VERSION "dbc-export 1 2026.26.6.5"

NS_ :

BS_:

BU_: ADSP APB APP APS APSB BB BMS CC CMP CMPD CP DAS DI DIF DIR DPB EPAS3P EPAS3S EPASTP EPASTS EPBL EPBR ESP EVSE FC GTW HCML HCMR HVP IBST ICR IDB LS OCS1P PARK PCS PCS2 PM PMF PMR PNCD PTC RADC RCM RCM2 RCM3 RCU SCCM SCM SCS SDCR TAS TCU TCU2 TPMS TRCM UI UIS UMC USM V2G VC VCBATT VCBATT0 VCBATT1 VCBATT2 VCCC VCFRONT VCFRONT1 VCFRONT2 VCLEFT VCRIGHT VCSEAT2L VCSEAT2R VCSEC VEH

BO_ 1470 IDB_alertLog: 8 IDB
 SG_ IDB_alertID M : 0|8@1+ (1,0) [0|255] "" Vector__XXX
 SG_ IDB_alertState : 15|1@1+ (1,0) [0|1] "" Vector__XXX
 SG_ IDB_a014_wheelSpeedSensorFreq m14 : 16|1@1+ (1,0) [0|1] "" Vector__XXX
 SG_ IDB_a014_wheelSpeedSensorPhase m14 : 17|1@1+ (1,0) [0|1] "" Vector__XXX
 SG_ IDB_a014_wheelSpeedSensorMisinst m14 : 18|1@1+ (1,0) [0|1] "" Vector__XXX
 SG_ IDB_a014_wheelSpeedSensorWrongEx m14 : 19|1@1+ (1,0) [0|1] "" Vector__XXX
 SG_ IDB_a014_wheelSpeedSensorSpeedJu m14 : 20|1@1+ (1,0) [0|1] "" Vector__XXX
 SG_ IDB_a014_wheelSpeedSensorSp_0001 m14 : 21|1@1+ (1,0) [0|1] "" Vector__XXX
 SG_ IDB_a014_wheelSpeedSensorAirGap m14 : 22|1@1+ (1,0) [0|1] "" Vector__XXX
 SG_ IDB_a014_wheelSpeedSensorBIST m14 : 23|1@1+ (1,0) [0|1] "" Vector__XXX
 SG_ IDB_a014_wheelSpeedSensorLeakage m14 : 24|1@1+ (1,0) [0|1] "" Vector__XXX
 SG_ IDB_a014_wheelSpeedSensorOverTem m14 : 25|1@1+ (1,0) [0|1] "" Vector__XXX
 SG_ IDB_a014_wheelSpeedSensorSh_0001 m14 : 26|1@1+ (1,0) [0|1] "" Vector__XXX
 SG_ IDB_a014_wheelSpeedSensorShortTo m14 : 27|1@1+ (1,0) [0|1] "" Vector__XXX
 SG_ IDB_a014_wheelSpeedSensorOpen m14 : 28|1@1+ (1,0) [0|1] "" Vector__XXX
 SG_ IDB_a015_wheelSpeedSensorFreq m15 : 16|1@1+ (1,0) [0|1] "" Vector__XXX
 SG_ IDB_a015_wheelSpeedSensorPhase m15 : 17|1@1+ (1,0) [0|1] "" Vector__XXX
 SG_ IDB_a015_wheelSpeedSensorMisinst m15 : 18|1@1+ (1,0) [0|1] "" Vector__XXX
 SG_ IDB_a015_wheelSpeedSensorWrongEx m15 : 19|1@1+ (1,0) [0|1] "" Vector__XXX
 SG_ IDB_a015_wheelSpeedSensorSpeedJu m15 : 20|1@1+ (1,0) [0|1] "" Vector__XXX
 SG_ IDB_a015_wheelSpeedSensorSp_0001 m15 : 21|1@1+ (1,0) [0|1] "" Vector__XXX
 SG_ IDB_a015_wheelSpeedSensorAirGap m15 : 22|1@1+ (1,0) [0|1] "" Vector__XXX
 SG_ IDB_a015_wheelSpeedSensorBIST m15 : 23|1@1+ (1,0) [0|1] "" Vector__XXX
 SG_ IDB_a015_wheelSpeedSensorLeakage m15 : 24|1@1+ (1,0) [0|1] "" Vector__XXX
 SG_ IDB_a015_wheelSpeedSensorOverTem m15 : 25|1@1+ (1,0) [0|1] "" Vector__XXX
 SG_ IDB_a015_wheelSpeedSensorSh_0001 m15 : 26|1@1+ (1,0) [0|1] "" Vector__XXX
 SG_ IDB_a015_wheelSpeedSensorShortTo m15 : 27|1@1+ (1,0) [0|1] "" Vector__XXX
 SG_ IDB_a015_wheelSpeedSensorOpen m15 : 28|1@1+ (1,0) [0|1] "" Vector__XXX
 SG_ IDB_a016_wheelSpeedSensorFreq m16 : 16|1@1+ (1,0) [0|1] "" Vector__XXX
 SG_ IDB_a016_wheelSpeedSensorPhase m16 : 17|1@1+ (1,0) [0|1] "" Vector__XXX
 SG_ IDB_a016_wheelSpeedSensorMisinst m16 : 18|1@1+ (1,0) [0|1] "" Vector__XXX
 SG_ IDB_a016_wheelSpeedSensorWrongEx m16 : 19|1@1+ (1,0) [0|1] "" Vector__XXX
 SG_ IDB_a016_wheelSpeedSensorSpeedJu m16 : 20|1@1+ (1,0) [0|1] "" Vector__XXX
 SG_ IDB_a016_wheelSpeedSensorSp_0001 m16 : 21|1@1+ (1,0) [0|1] "" Vector__XXX
 SG_ IDB_a016_wheelSpeedSensorAirGap m16 : 22|1@1+ (1,0) [0|1] "" Vector__XXX
 SG_ IDB_a016_wheelSpeedSensorBIST m16 : 23|1@1+ (1,0) [0|1] "" Vector__XXX
 SG_ IDB_a016_wheelSpeedSensorLeakage m16 : 24|1@1+ (1,0) [0|1] "" Vector__XXX
 SG_ IDB_a016_wheelSpeedSensorOverTem m16 : 25|1@1+ (1,0) [0|1] "" Vector__XXX
 SG_ IDB_a016_wheelSpeedSensorSh_0001 m16 : 26|1@1+ (1,0) [0|1] "" Vector__XXX
 SG_ IDB_a016_wheelSpeedSensorShortTo m16 : 27|1@1+ (1,0) [0|1] "" Vector__XXX
 SG_ IDB_a016_wheelSpeedSensorOpen m16 : 28|1@1+ (1,0) [0|1] "" Vector__XXX
 SG_ IDB_a017_wheelSpeedSensorFreq m17 : 16|1@1+ (1,0) [0|1] "" Vector__XXX
 SG_ IDB_a017_wheelSpeedSensorPhase m17 : 17|1@1+ (1,0) [0|1] "" Vector__XXX
 SG_ IDB_a017_wheelSpeedSensorMisinst m17 : 18|1@1+ (1,0) [0|1] "" Vector__XXX
 SG_ IDB_a017_wheelSpeedSensorWrongEx m17 : 19|1@1+ (1,0) [0|1] "" Vector__XXX
 SG_ IDB_a017_wheelSpeedSensorSpeedJu m17 : 20|1@1+ (1,0) [0|1] "" Vector__XXX
 SG_ IDB_a017_wheelSpeedSensorSp_0001 m17 : 21|1@1+ (1,0) [0|1] "" Vector__XXX
 SG_ IDB_a017_wheelSpeedSensorAirGap m17 : 22|1@1+ (1,0) [0|1] "" Vector__XXX
 SG_ IDB_a017_wheelSpeedSensorBIST m17 : 23|1@1+ (1,0) [0|1] "" Vector__XXX
 SG_ IDB_a017_wheelSpeedSensorLeakage m17 : 24|1@1+ (1,0) [0|1] "" Vector__XXX
 SG_ IDB_a017_wheelSpeedSensorOverTem m17 : 25|1@1+ (1,0) [0|1] "" Vector__XXX
 SG_ IDB_a017_wheelSpeedSensorSh_0001 m17 : 26|1@1+ (1,0) [0|1] "" Vector__XXX
 SG_ IDB_a017_wheelSpeedSensorShortTo m17 : 27|1@1+ (1,0) [0|1] "" Vector__XXX
 SG_ IDB_a017_wheelSpeedSensorOpen m17 : 28|1@1+ (1,0) [0|1] "" Vector__XXX
 SG_ IDB_a020_canSignalValidity m20 : 16|1@1+ (1,0) [0|1] "" Vector__XXX
 SG_ IDB_a020_signalValueCrosscheck m20 : 17|1@1+ (1,0) [0|1] "" Vector__XXX
 SG_ IDB_a030_primaryExternalCircuitL m30 : 16|1@1+ (1,0) [0|1] "" Vector__XXX
 SG_ IDB_a030_secondaryExternalCircui m30 : 17|1@1+ (1,0) [0|1] "" Vector__XXX
 SG_ IDB_a030_primaryChamberInternalL m30 : 18|1@1+ (1,0) [0|1] "" Vector__XXX
 SG_ IDB_a030_syncModeInternalLeakage m30 : 19|1@1+ (1,0) [0|1] "" Vector__XXX
 SG_ IDB_a030_secondaryChamberInterna m30 : 20|1@1+ (1,0) [0|1] "" Vector__XXX
 SG_ IDB_a030_masterCylinderInternalL m30 : 21|1@1+ (1,0) [0|1] "" Vector__XXX
 SG_ IDB_a060_validityOnChassisBus m60 : 16|1@1+ (1,0) [0|1] "" Vector__XXX
 SG_ IDB_a060_validityOnPartyBus m60 : 17|1@1+ (1,0) [0|1] "" Vector__XXX
 SG_ IDB_a061_validityOnChassisBus m61 : 16|1@1+ (1,0) [0|1] "" Vector__XXX
 SG_ IDB_a061_validityOnPartyBus m61 : 17|1@1+ (1,0) [0|1] "" Vector__XXX
 SG_ IDB_a063_validityOnChassisBus m63 : 16|1@1+ (1,0) [0|1] "" Vector__XXX
 SG_ IDB_a063_validityOnPartyBus m63 : 17|1@1+ (1,0) [0|1] "" Vector__XXX
 SG_ IDB_a064_validityOnChassisBus m64 : 16|1@1+ (1,0) [0|1] "" Vector__XXX
 SG_ IDB_a064_validityOnPartyBus m64 : 17|1@1+ (1,0) [0|1] "" Vector__XXX
 SG_ IDB_a065_validityOnChassisBus m65 : 16|1@1+ (1,0) [0|1] "" Vector__XXX
 SG_ IDB_a065_validityOnPartyBus m65 : 17|1@1+ (1,0) [0|1] "" Vector__XXX
 SG_ IDB_a106_qualifierValidity m106 : 16|1@1+ (1,0) [0|1] "" Vector__XXX
 SG_ IDB_a106_signalNotAvailable m106 : 17|1@1+ (1,0) [0|1] "" Vector__XXX
 SG_ IDB_a107_qualifierValidity m107 : 16|1@1+ (1,0) [0|1] "" Vector__XXX
 SG_ IDB_a107_signalNotAvailable m107 : 17|1@1+ (1,0) [0|1] "" Vector__XXX
 SG_ IDB_a112_qualifierValidity m112 : 16|1@1+ (1,0) [0|1] "" Vector__XXX
 SG_ IDB_a112_signalNotAvailable m112 : 17|1@1+ (1,0) [0|1] "" Vector__XXX
 SG_ IDB_a113_qualifierValidity m113 : 16|1@1+ (1,0) [0|1] "" Vector__XXX
 SG_ IDB_a113_signalNotAvailable m113 : 17|1@1+ (1,0) [0|1] "" Vector__XXX
 SG_ IDB_a114_qualifierValidity m114 : 16|1@1+ (1,0) [0|1] "" Vector__XXX
 SG_ IDB_a114_signalNotAvailable m114 : 17|1@1+ (1,0) [0|1] "" Vector__XXX
 SG_ IDB_a126_PMebrCmdStateValidity m126 : 16|1@1+ (1,0) [0|1] "" Vector__XXX
 SG_ IDB_a126_PMstate2Validity m126 : 17|1@1+ (1,0) [0|1] "" Vector__XXX
 SG_ IDB_a126_PMstate2Missing m126 : 18|1@1+ (1,0) [0|1] "" Vector__XXX
 SG_ IDB_a126_DIchassisControlValidit m126 : 19|1@1+ (1,0) [0|1] "" Vector__XXX
 SG_ IDB_a126_DIchassisControlMissing m126 : 20|1@1+ (1,0) [0|1] "" Vector__XXX
 SG_ IDB_a126_DIrequestActiveValidity m126 : 21|1@1+ (1,0) [0|1] "" Vector__XXX
 SG_ IDB_a129_validityOnChassisBus m129 : 16|1@1+ (1,0) [0|1] "" Vector__XXX
 SG_ IDB_a129_validityOnPartyBus m129 : 17|1@1+ (1,0) [0|1] "" Vector__XXX
 SG_ IDB_a130_PMbrakePedalCmdQFValidi m130 : 16|1@1+ (1,0) [0|1] "" Vector__XXX
 SG_ IDB_a130_PMstate2Validity m130 : 17|1@1+ (1,0) [0|1] "" Vector__XXX
 SG_ IDB_a130_PMstate2Missing m130 : 18|1@1+ (1,0) [0|1] "" Vector__XXX
 SG_ IDB_a130_DIbrakeCommandValidity m130 : 19|1@1+ (1,0) [0|1] "" Vector__XXX
 SG_ IDB_a130_DIbrakeCommandMissing m130 : 20|1@1+ (1,0) [0|1] "" Vector__XXX
 SG_ IDB_a130_DIbrakeTorqueCommandFul m130 : 21|1@1+ (1,0) [0|1] "" Vector__XXX
 SG_ IDB_a130_DIbrakeTorqueComma_0001 m130 : 22|1@1+ (1,0) [0|1] "" Vector__XXX
 SG_ IDB_a132_validityOnChassisBus m132 : 16|1@1+ (1,0) [0|1] "" Vector__XXX
 SG_ IDB_a132_validityOnPartyBus m132 : 17|1@1+ (1,0) [0|1] "" Vector__XXX

BO_ 983 IDB_alertMatrix: 8 IDB
 SG_ IDB_matrixIndex M : 0|4@1+ (1,0) [0|15] "" Vector__XXX
 SG_ IDB_a001_mcuGenericFault m0 : 4|1@1+ (1,0) [0|1] "" Vector__XXX
 SG_ IDB_a002_supplyOvervoltage m0 : 5|1@1+ (1,0) [0|1] "" Vector__XXX
 SG_ IDB_a003_supplyHardOvervoltage m0 : 6|1@1+ (1,0) [0|1] "" Vector__XXX
 SG_ IDB_a004_supplyUndervoltage m0 : 7|1@1+ (1,0) [0|1] "" Vector__XXX
 SG_ IDB_a005_supplyMidUndervoltage m0 : 8|1@1+ (1,0) [0|1] "" Vector__XXX
 SG_ IDB_a006_supplyHardUndervoltage m0 : 9|1@1+ (1,0) [0|1] "" Vector__XXX
 SG_ IDB_a007_wakeLineOpen m0 : 10|1@1+ (1,0) [0|1] "" Vector__XXX
 SG_ IDB_a008_motorPowerOpen m0 : 11|1@1+ (1,0) [0|1] "" Vector__XXX
 SG_ IDB_a009_asicBoostFault m0 : 12|1@1+ (1,0) [0|1] "" Vector__XXX
 SG_ IDB_a010_asicGenericFault m0 : 13|1@1+ (1,0) [0|1] "" Vector__XXX
 SG_ IDB_a011_solenoidValveFault m0 : 14|1@1+ (1,0) [0|1] "" Vector__XXX
 SG_ IDB_a012_motorGenericFault m0 : 15|1@1+ (1,0) [0|1] "" Vector__XXX
 SG_ IDB_a013_motorPosSensorFault m0 : 16|1@1+ (1,0) [0|1] "" Vector__XXX
 SG_ IDB_a014_FrLWSSFault m0 : 17|1@1+ (1,0) [0|1] "" Vector__XXX
 SG_ IDB_a015_FrRWSSFault m0 : 18|1@1+ (1,0) [0|1] "" Vector__XXX
 SG_ IDB_a016_ReLWSSFault m0 : 19|1@1+ (1,0) [0|1] "" Vector__XXX
 SG_ IDB_a017_ReRWSSFault m0 : 20|1@1+ (1,0) [0|1] "" Vector__XXX
 SG_ IDB_a018_WSSGenericFault m0 : 21|1@1+ (1,0) [0|1] "" Vector__XXX
 SG_ IDB_a019_pedalSensorFault m0 : 22|1@1+ (1,0) [0|1] "" Vector__XXX
 SG_ IDB_a020_RCUpedalTravelMismatch m0 : 23|1@1+ (1,0) [0|1] "" Vector__XXX
 SG_ IDB_a021_pedalSensorNotCal m0 : 24|1@1+ (1,0) [0|1] "" Vector__XXX
 SG_ IDB_a022_brakeFluidLow m0 : 25|1@1+ (1,0) [0|1] "" Vector__XXX
 SG_ IDB_a023_steeringImplausible m0 : 26|1@1+ (1,0) [0|1] "" Vector__XXX
 SG_ IDB_a024_yawImplausible m0 : 27|1@1+ (1,0) [0|1] "" Vector__XXX
 SG_ IDB_a025_ayImplausible m0 : 28|1@1+ (1,0) [0|1] "" Vector__XXX
 SG_ IDB_a026_axImplausible m0 : 29|1@1+ (1,0) [0|1] "" Vector__XXX
 SG_ IDB_a027_circuitPresSensorFault m0 : 30|1@1+ (1,0) [0|1] "" Vector__XXX
 SG_ IDB_a028_simPresSensorFault m0 : 31|1@1+ (1,0) [0|1] "" Vector__XXX
 SG_ IDB_a029_pressureSensNotCal m0 : 32|1@1+ (1,0) [0|1] "" Vector__XXX
 SG_ IDB_a030_fluidLeakDetected m0 : 33|1@1+ (1,0) [0|1] "" Vector__XXX
 SG_ IDB_a031_solenoidValveStuck m0 : 34|1@1+ (1,0) [0|1] "" Vector__XXX
 SG_ IDB_a032_motorSoftOverheat m0 : 35|1@1+ (1,0) [0|1] "" Vector__XXX
 SG_ IDB_a033_motorHardOverheat m0 : 36|1@1+ (1,0) [0|1] "" Vector__XXX
 SG_ IDB_a034_motorPositionSetFault m0 : 37|1@1+ (1,0) [0|1] "" Vector__XXX
 SG_ IDB_a035_motorStuck m0 : 38|1@1+ (1,0) [0|1] "" Vector__XXX
 SG_ IDB_a036_partyBusOff m0 : 39|1@1+ (1,0) [0|1] "" Vector__XXX
 SG_ IDB_a037_chassisBusOff m0 : 40|1@1+ (1,0) [0|1] "" Vector__XXX
 SG_ IDB_a038_motorInitFault m0 : 41|1@1+ (1,0) [0|1] "" Vector__XXX
 SG_ IDB_a039_absActive m0 : 42|1@1+ (1,0) [0|1] "" Vector__XXX
 SG_ IDB_a040_ebdActive m0 : 43|1@1+ (1,0) [0|1] "" Vector__XXX
 SG_ IDB_a041_vdcActive m0 : 44|1@1+ (1,0) [0|1] "" Vector__XXX
 SG_ IDB_a042_btcActive m0 : 45|1@1+ (1,0) [0|1] "" Vector__XXX
 SG_ IDB_a043_cbcActive m0 : 46|1@1+ (1,0) [0|1] "" Vector__XXX
 SG_ IDB_a044_standstillSkidDetected m0 : 47|1@1+ (1,0) [0|1] "" Vector__XXX
 SG_ IDB_a045_panicBrakeAssistActive m0 : 48|1@1+ (1,0) [0|1] "" Vector__XXX
 SG_ IDB_a046_fadeCompensationActive m0 : 49|1@1+ (1,0) [0|1] "" Vector__XXX
 SG_ IDB_a047_brakeDiscWipeActive m0 : 50|1@1+ (1,0) [0|1] "" Vector__XXX
 SG_ IDB_a048_scmActive m0 : 51|1@1+ (1,0) [0|1] "" Vector__XXX
 SG_ IDB_a049_cdpActive m0 : 52|1@1+ (1,0) [0|1] "" Vector__XXX
 SG_ IDB_a050_absFaulted m0 : 53|1@1+ (1,0) [0|1] "" Vector__XXX
 SG_ IDB_a051_ebdFaulted m0 : 54|1@1+ (1,0) [0|1] "" Vector__XXX
 SG_ IDB_a052_vdcFaulted m0 : 55|1@1+ (1,0) [0|1] "" Vector__XXX
 SG_ IDB_a053_DItorquePathFaulted m0 : 56|1@1+ (1,0) [0|1] "" Vector__XXX
 SG_ IDB_a054_skidDetectionFaulted m0 : 57|1@1+ (1,0) [0|1] "" Vector__XXX
 SG_ IDB_a055_panicBrakeAssistFaulted m0 : 58|1@1+ (1,0) [0|1] "" Vector__XXX
 SG_ IDB_a056_fadeCompensationFaulted m0 : 59|1@1+ (1,0) [0|1] "" Vector__XXX
 SG_ IDB_a057_bdwRequestInvalid m0 : 60|1@1+ (1,0) [0|1] "" Vector__XXX
 SG_ IDB_a058_scmFaulted m0 : 61|1@1+ (1,0) [0|1] "" Vector__XXX
 SG_ IDB_a059_cdpFaulted m0 : 62|1@1+ (1,0) [0|1] "" Vector__XXX
 SG_ IDB_a060_RCUstatusDLC m0 : 63|1@1+ (1,0) [0|1] "" Vector__XXX
 SG_ IDB_a061_RCUstatusChecksum m1 : 4|1@1+ (1,0) [0|1] "" Vector__XXX
 SG_ IDB_a062_RCUstatusCounter m1 : 5|1@1+ (1,0) [0|1] "" Vector__XXX
 SG_ IDB_a063_RCUactuationDLC m1 : 6|1@1+ (1,0) [0|1] "" Vector__XXX
 SG_ IDB_a064_RCUactuationChecksum m1 : 7|1@1+ (1,0) [0|1] "" Vector__XXX
 SG_ IDB_a065_RCUactuationCounter m1 : 8|1@1+ (1,0) [0|1] "" Vector__XXX
 SG_ IDB_a066_DIFtorqueDLC m1 : 9|1@1+ (1,0) [0|1] "" Vector__XXX
 SG_ IDB_a067_DIFtorqueChecksum m1 : 10|1@1+ (1,0) [0|1] "" Vector__XXX
 SG_ IDB_a068_DIFtorqueCounter m1 : 11|1@1+ (1,0) [0|1] "" Vector__XXX
 SG_ IDB_a069_DIchassisControlDLC m1 : 12|1@1+ (1,0) [0|1] "" Vector__XXX
 SG_ IDB_a070_DIchassisControlChecksu m1 : 13|1@1+ (1,0) [0|1] "" Vector__XXX
 SG_ IDB_a071_DIchassisControlCounter m1 : 14|1@1+ (1,0) [0|1] "" Vector__XXX
 SG_ IDB_a072_DIsystemStatusDLC m1 : 15|1@1+ (1,0) [0|1] "" Vector__XXX
 SG_ IDB_a073_DIsystemStatusChecksum m1 : 16|1@1+ (1,0) [0|1] "" Vector__XXX
 SG_ IDB_a074_DIsystemStatusCounter m1 : 17|1@1+ (1,0) [0|1] "" Vector__XXX
 SG_ IDB_a075_DIRtorqueDLC m1 : 18|1@1+ (1,0) [0|1] "" Vector__XXX
 SG_ IDB_a076_DIRtorqueChecksum m1 : 19|1@1+ (1,0) [0|1] "" Vector__XXX
 SG_ IDB_a077_DIRtorqueCounter m1 : 20|1@1+ (1,0) [0|1] "" Vector__XXX
 SG_ IDB_a078_DIvdcLeftDLC m1 : 21|1@1+ (1,0) [0|1] "" Vector__XXX
 SG_ IDB_a079_DIvdcLeftChecksum m1 : 22|1@1+ (1,0) [0|1] "" Vector__XXX
 SG_ IDB_a080_DIvdcLeftCounter m1 : 23|1@1+ (1,0) [0|1] "" Vector__XXX
 SG_ IDB_a081_DIvdcRightDLC m1 : 24|1@1+ (1,0) [0|1] "" Vector__XXX
 SG_ IDB_a082_DIvdcRightChecksum m1 : 25|1@1+ (1,0) [0|1] "" Vector__XXX
 SG_ IDB_a083_DIvdcRightCounter m1 : 26|1@1+ (1,0) [0|1] "" Vector__XXX
 SG_ IDB_a084_EPAS3PsysStatusDLC m1 : 27|1@1+ (1,0) [0|1] "" Vector__XXX
 SG_ IDB_a085_EPAS3PsysStatusChecksum m1 : 28|1@1+ (1,0) [0|1] "" Vector__XXX
 SG_ IDB_a086_EPAS3PsysStatusCounter m1 : 29|1@1+ (1,0) [0|1] "" Vector__XXX
 SG_ IDB_a087_PMstate2DLC m1 : 30|1@1+ (1,0) [0|1] "" Vector__XXX
 SG_ IDB_a088_PMstate2Checksum m1 : 31|1@1+ (1,0) [0|1] "" Vector__XXX
 SG_ IDB_a089_PMstate2Counter m1 : 32|1@1+ (1,0) [0|1] "" Vector__XXX
 SG_ IDB_a090_RCMinertial1DLC m1 : 33|1@1+ (1,0) [0|1] "" Vector__XXX
 SG_ IDB_a091_RCMinertial1Checksum m1 : 34|1@1+ (1,0) [0|1] "" Vector__XXX
 SG_ IDB_a092_RCMinertial1Counter m1 : 35|1@1+ (1,0) [0|1] "" Vector__XXX
 SG_ IDB_a093_RCMinertial2DLC m1 : 36|1@1+ (1,0) [0|1] "" Vector__XXX
 SG_ IDB_a094_RCMinertial2Checksum m1 : 37|1@1+ (1,0) [0|1] "" Vector__XXX
 SG_ IDB_a095_RCMinertial2Counter m1 : 38|1@1+ (1,0) [0|1] "" Vector__XXX
 SG_ IDB_a096_VCFRONTLVPowerStateDLC m1 : 39|1@1+ (1,0) [0|1] "" Vector__XXX
 SG_ IDB_a097_VCFRONTLVPwrStChecksum m1 : 40|1@1+ (1,0) [0|1] "" Vector__XXX
 SG_ IDB_a098_VCFRONTLVPwrStCounter m1 : 41|1@1+ (1,0) [0|1] "" Vector__XXX
 SG_ IDB_a099_RCMcollisionDLC m1 : 42|1@1+ (1,0) [0|1] "" Vector__XXX
 SG_ IDB_a100_RCMcollisionChecksum m1 : 43|1@1+ (1,0) [0|1] "" Vector__XXX
 SG_ IDB_a101_RCMcollisionCounter m1 : 44|1@1+ (1,0) [0|1] "" Vector__XXX
 SG_ IDB_a102_bdwRequestActiveInvalid m1 : 45|1@1+ (1,0) [0|1] "" Vector__XXX
 SG_ IDB_a103_DIfullTorquePathFaulted m1 : 46|1@1+ (1,0) [0|1] "" Vector__XXX
 SG_ IDB_a104_DIaccelPosInvalid m1 : 47|1@1+ (1,0) [0|1] "" Vector__XXX
 SG_ IDB_a105_DIgearInvalid m1 : 48|1@1+ (1,0) [0|1] "" Vector__XXX
 SG_ IDB_a106_DIFtorqueInvalid m1 : 49|1@1+ (1,0) [0|1] "" Vector__XXX
 SG_ IDB_a107_DIRtorqueInvalid m1 : 50|1@1+ (1,0) [0|1] "" Vector__XXX
 SG_ IDB_a108_EPBstatusDLC m1 : 51|1@1+ (1,0) [0|1] "" Vector__XXX
 SG_ IDB_a109_BDWsignalInvalid m1 : 52|1@1+ (1,0) [0|1] "" Vector__XXX
 SG_ IDB_a110_EPBstatusCounter m1 : 53|1@1+ (1,0) [0|1] "" Vector__XXX
 SG_ IDB_a111_EPBstatusChecksum m1 : 54|1@1+ (1,0) [0|1] "" Vector__XXX
 SG_ IDB_a112_yawRateInvalid m1 : 55|1@1+ (1,0) [0|1] "" Vector__XXX
 SG_ IDB_a113_latAccelInvalid m1 : 56|1@1+ (1,0) [0|1] "" Vector__XXX
 SG_ IDB_a114_longAccelInvalid m1 : 57|1@1+ (1,0) [0|1] "" Vector__XXX
 SG_ IDB_a115_VCFRONTespLvStInvalid m1 : 58|1@1+ (1,0) [0|1] "" Vector__XXX
 SG_ IDB_a116_VCFRONTsensorsDLC m1 : 59|1@1+ (1,0) [0|1] "" Vector__XXX
 SG_ IDB_a117_VCLEFTepbmStatusDLC m1 : 60|1@1+ (1,0) [0|1] "" Vector__XXX
 SG_ IDB_a118_VCLEFTepbmStatusCounter m1 : 61|1@1+ (1,0) [0|1] "" Vector__XXX
 SG_ IDB_a119_VCLEFTepbmStatusChecksu m1 : 62|1@1+ (1,0) [0|1] "" Vector__XXX
 SG_ IDB_a120_EPAS3Pinvalid m1 : 63|1@1+ (1,0) [0|1] "" Vector__XXX
 SG_ IDB_a121_dynoModeActive m2 : 4|1@1+ (1,0) [0|1] "" Vector__XXX
 SG_ IDB_a122_DIFtorqueCommandInvalid m2 : 5|1@1+ (1,0) [0|1] "" Vector__XXX
 SG_ IDB_a123_DIRtorqueCommandInvalid m2 : 6|1@1+ (1,0) [0|1] "" Vector__XXX
 SG_ IDB_a124_VCFRONTtempInvalid m2 : 7|1@1+ (1,0) [0|1] "" Vector__XXX
 SG_ IDB_a125_PMvdcCmdStateInvalid m2 : 8|1@1+ (1,0) [0|1] "" Vector__XXX
 SG_ IDB_a126_DItorqueRequestInvalid m2 : 9|1@1+ (1,0) [0|1] "" Vector__XXX
 SG_ IDB_a127_brakeFluidLevelInvalid m2 : 10|1@1+ (1,0) [0|1] "" Vector__XXX
 SG_ IDB_a128_largeAirVolume m2 : 11|1@1+ (1,0) [0|1] "" Vector__XXX
 SG_ IDB_a129_RCUinputRodStrokeInvali m2 : 12|1@1+ (1,0) [0|1] "" Vector__XXX
 SG_ IDB_a130_DIfullTorqueRequestInva m2 : 13|1@1+ (1,0) [0|1] "" Vector__XXX
 SG_ IDB_a131_cbcFaulted m2 : 14|1@1+ (1,0) [0|1] "" Vector__XXX
 SG_ IDB_a132_RCUinputRodStrokeQFInva m2 : 15|1@1+ (1,0) [0|1] "" Vector__XXX
 SG_ IDB_a133_DIbrakeCommandDLC m2 : 16|1@1+ (1,0) [0|1] "" Vector__XXX
 SG_ IDB_a134_DIbrakeCommandCounter m2 : 17|1@1+ (1,0) [0|1] "" Vector__XXX
 SG_ IDB_a135_DIbrakeCommandChecksum m2 : 18|1@1+ (1,0) [0|1] "" Vector__XXX
 SG_ IDB_a136_RCUptsCalMissing m2 : 19|1@1+ (1,0) [0|1] "" Vector__XXX
 SG_ IDB_a137_VCLEFTcdpRequestInvalid m2 : 20|1@1+ (1,0) [0|1] "" Vector__XXX
 SG_ IDB_a138_DIbrakeTorqueCommandAnd m2 : 21|1@1+ (1,0) [0|1] "" Vector__XXX
 SG_ IDB_a139_DIbrakeTorqueCommandFul m2 : 22|1@1+ (1,0) [0|1] "" Vector__XXX
 SG_ IDB_a140_PMbrakePedalCmdQFInvali m2 : 23|1@1+ (1,0) [0|1] "" Vector__XXX
 SG_ IDB_a141_DIbrakeTorqueCommandFul m2 : 24|1@1+ (1,0) [0|1] "" Vector__XXX
 SG_ IDB_a142_PMebrCmdStateInvalid m2 : 25|1@1+ (1,0) [0|1] "" Vector__XXX
 SG_ IDB_a143_factoryModeActive m2 : 26|1@1+ (1,0) [0|1] "" Vector__XXX
 SG_ IDB_a144_hydraulicPushthroughAct m2 : 27|1@1+ (1,0) [0|1] "" Vector__XXX
 SG_ IDB_a145_DASredundantBrakingCont m2 : 28|1@1+ (1,0) [0|1] "" Vector__XXX
 SG_ IDB_a146_DASredundantBrakingCont m2 : 29|1@1+ (1,0) [0|1] "" Vector__XXX
 SG_ IDB_a147_DASredundantBrakingCont m2 : 30|1@1+ (1,0) [0|1] "" Vector__XXX
 SG_ IDB_a148_DASbrakeTorqueCommandIn m2 : 31|1@1+ (1,0) [0|1] "" Vector__XXX
 SG_ IDB_a149_DASmiaBrakeTorqueComman m2 : 32|1@1+ (1,0) [0|1] "" Vector__XXX
 SG_ IDB_a150_DIlocStatus2DLC m2 : 33|1@1+ (1,0) [0|1] "" Vector__XXX
 SG_ IDB_a151_DIlocStatus2Counter m2 : 34|1@1+ (1,0) [0|1] "" Vector__XXX
 SG_ IDB_a152_DIlocStatus2Checksum m2 : 35|1@1+ (1,0) [0|1] "" Vector__XXX
 SG_ IDB_a155_PMlocStateDLC m2 : 38|1@1+ (1,0) [0|1] "" Vector__XXX
 SG_ IDB_a156_PMlocStateChecksum m2 : 39|1@1+ (1,0) [0|1] "" Vector__XXX
 SG_ IDB_a157_PMlocStateCounter m2 : 40|1@1+ (1,0) [0|1] "" Vector__XXX

BO_ 828 IDB_info: 8 IDB
 SG_ IDB_infoIndex M : 0|8@1+ (1,0) [0|255] "" Vector__XXX
 SG_ IDB_infoPcbaID m11 : 16|8@1+ (1,0) [0|255] "" Vector__XXX
 SG_ IDB_infoAssemblyID m11 : 24|8@1+ (1,0) [0|255] "" Vector__XXX
 SG_ IDB_infoUsageID m11 : 32|16@1+ (1,0) [0|65535] "" Vector__XXX
 SG_ IDB_infoSubUsageID m11 : 48|16@1+ (1,0) [0|65535] "" Vector__XXX

BO_ 1012 LS_lightShow: 8 LS
 SG_ LS_lightShowIndex M : 0|5@1+ (1,0) [0|31] "" Vector__XXX
 SG_ LS_lightLeftRampedChannel1Reques m0 : 5|1@1+ (1,0) [0|1] "" Vector__XXX
 SG_ LS_lightLeftRampedChannel1Durati m0 : 6|2@1+ (1,0) [0|3] "" Vector__XXX
 SG_ LS_lightLeftRampedChannel2Reques m0 : 8|1@1+ (1,0) [0|1] "" Vector__XXX
 SG_ LS_lightLeftRampedChannel2Durati m0 : 9|2@1+ (1,0) [0|3] "" Vector__XXX
 SG_ LS_lightLeftRampedChannel3Reques m0 : 11|1@1+ (1,0) [0|1] "" Vector__XXX
 SG_ LS_lightLeftRampedChannel3Durati m0 : 12|2@1+ (1,0) [0|3] "" Vector__XXX
 SG_ LS_lightLeftRampedChannel4Reques m0 : 14|1@1+ (1,0) [0|1] "" Vector__XXX
 SG_ LS_lightLeftRampedChannel4Durati m0 : 16|2@1+ (1,0) [0|3] "" Vector__XXX
 SG_ LS_lightLeftRampedChannel5Reques m0 : 18|1@1+ (1,0) [0|1] "" Vector__XXX
 SG_ LS_lightLeftRampedChannel5Durati m0 : 19|2@1+ (1,0) [0|3] "" Vector__XXX
 SG_ LS_lightLeftRampedChannel6Reques m0 : 21|1@1+ (1,0) [0|1] "" Vector__XXX
 SG_ LS_lightLeftRampedChannel6Durati m0 : 22|2@1+ (1,0) [0|3] "" Vector__XXX
 SG_ LS_lightLeftRampedChannel7Reques m0 : 24|1@1+ (1,0) [0|1] "" Vector__XXX
 SG_ LS_lightLeftRampedChannel7Durati m0 : 25|2@1+ (1,0) [0|3] "" Vector__XXX
 SG_ LS_lightRightRampedChannel1Reque m0 : 27|1@1+ (1,0) [0|1] "" Vector__XXX
 SG_ LS_lightRightRampedChannel1Durat m0 : 28|2@1+ (1,0) [0|3] "" Vector__XXX
 SG_ LS_lightRightRampedChannel2Reque m0 : 30|1@1+ (1,0) [0|1] "" Vector__XXX
 SG_ LS_lightRightRampedChannel2Durat m0 : 31|2@1+ (1,0) [0|3] "" Vector__XXX
 SG_ LS_lightRightRampedChannel3Reque m0 : 33|1@1+ (1,0) [0|1] "" Vector__XXX
 SG_ LS_lightRightRampedChannel3Durat m0 : 34|2@1+ (1,0) [0|3] "" Vector__XXX
 SG_ LS_lightRightRampedChannel4Reque m0 : 36|1@1+ (1,0) [0|1] "" Vector__XXX
 SG_ LS_lightRightRampedChannel4Durat m0 : 37|2@1+ (1,0) [0|3] "" Vector__XXX
 SG_ LS_lightRightRampedChannel5Reque m0 : 39|1@1+ (1,0) [0|1] "" Vector__XXX
 SG_ LS_lightRightRampedChannel5Durat m0 : 40|2@1+ (1,0) [0|3] "" Vector__XXX
 SG_ LS_lightRightRampedChannel6Reque m0 : 42|1@1+ (1,0) [0|1] "" Vector__XXX
 SG_ LS_lightRightRampedChannel6Durat m0 : 43|2@1+ (1,0) [0|3] "" Vector__XXX
 SG_ LS_lightRightRampedChannel7Reque m0 : 45|1@1+ (1,0) [0|1] "" Vector__XXX
 SG_ LS_lightRightRampedChannel7Durat m0 : 46|2@1+ (1,0) [0|3] "" Vector__XXX
 SG_ LS_lightRearTurnLeftRequest m0 : 48|1@1+ (1,0) [0|1] "" Vector__XXX
 SG_ LS_lightRearTurnRightRequest m0 : 49|1@1+ (1,0) [0|1] "" Vector__XXX
 SG_ LS_lightSideRepeaterLeftRequest m0 : 50|1@1+ (1,0) [0|1] "" Vector__XXX
 SG_ LS_lightSideRepeaterRightRequest m0 : 51|1@1+ (1,0) [0|1] "" Vector__XXX
 SG_ LS_lightSideMarkerLeftRequest m0 : 52|1@1+ (1,0) [0|1] "" Vector__XXX
 SG_ LS_lightSideMarkerRightRequest m0 : 53|1@1+ (1,0) [0|1] "" Vector__XXX
 SG_ LS_lightFrontFogLeftRequest m0 : 54|1@1+ (1,0) [0|1] "" Vector__XXX
 SG_ LS_lightFrontFogRightRequest m0 : 55|1@1+ (1,0) [0|1] "" Vector__XXX
 SG_ LS_lightRearFogRequest m0 : 56|1@1+ (1,0) [0|1] "" Vector__XXX
 SG_ LS_lightBrakeRequest m0 : 57|1@1+ (1,0) [0|1] "" Vector__XXX
 SG_ LS_lightTailLeftRequest m0 : 58|1@1+ (1,0) [0|1] "" Vector__XXX
 SG_ LS_lightTailRightRequest m0 : 59|1@1+ (1,0) [0|1] "" Vector__XXX
 SG_ LS_lightLicensePlateRequest m0 : 60|1@1+ (1,0) [0|1] "" Vector__XXX
 SG_ LS_lightReverseRequest m0 : 61|1@1+ (1,0) [0|1] "" Vector__XXX
 SG_ LS_lightAuxParkLeftRequest m0 : 62|1@1+ (1,0) [0|1] "" Vector__XXX
 SG_ LS_lightAuxParkRightRequest m0 : 63|1@1+ (1,0) [0|1] "" Vector__XXX
 SG_ LS_mirrorRequestLeft m1 : 5|3@1+ (1,0) [0|7] "" Vector__XXX
 SG_ LS_mirrorRequestRight m1 : 8|3@1+ (1,0) [0|7] "" Vector__XXX
 SG_ LS_liftgateRequest m1 : 11|3@1+ (1,0) [0|7] "" Vector__XXX
 SG_ LS_windowRequestLF m1 : 16|3@1+ (1,0) [0|7] "" Vector__XXX
 SG_ LS_windowRequestLR m1 : 19|3@1+ (1,0) [0|7] "" Vector__XXX
 SG_ LS_windowRequestRF m1 : 24|3@1+ (1,0) [0|7] "" Vector__XXX
 SG_ LS_windowRequestRR m1 : 27|3@1+ (1,0) [0|7] "" Vector__XXX
 SG_ LS_presentingHandleRequestLF m1 : 32|3@1+ (1,0) [0|7] "" Vector__XXX
 SG_ LS_presentingHandleRequestLR m1 : 35|3@1+ (1,0) [0|7] "" Vector__XXX
 SG_ LS_presentingHandleRequestRF m1 : 40|3@1+ (1,0) [0|7] "" Vector__XXX
 SG_ LS_presentingHandleRequestRR m1 : 43|3@1+ (1,0) [0|7] "" Vector__XXX
 SG_ LS_powerFrontDoorRequestLeft m1 : 46|3@1+ (1,0) [0|7] "" Vector__XXX
 SG_ LS_powerFrontDoorRequestRight m1 : 49|3@1+ (1,0) [0|7] "" Vector__XXX
 SG_ LS_falconDoorRequestLeft m1 : 52|3@1+ (1,0) [0|7] "" Vector__XXX
 SG_ LS_falconDoorRequestRight m1 : 55|3@1+ (1,0) [0|7] "" Vector__XXX
 SG_ LS_chargePortRequest m1 : 58|2@1+ (1,0) [0|2] "" Vector__XXX
 SG_ LS_chargePortRaveRequest m1 : 60|1@1+ (1,0) [0|1] "" Vector__XXX
 SG_ LS_suspensionRequest m1 : 61|2@1+ (1,0) [0|2] "" Vector__XXX
 SG_ LS_rgbIPFLRed m2 : 8|8@1+ (1,0) [0|255] "" Vector__XXX
 SG_ LS_rgbIPFLGreen m2 : 16|8@1+ (1,0) [0|255] "" Vector__XXX
 SG_ LS_rgbIPFLBlue m2 : 24|8@1+ (1,0) [0|255] "" Vector__XXX
 SG_ LS_rgbIPFRRed m2 : 32|8@1+ (1,0) [0|255] "" Vector__XXX
 SG_ LS_rgbIPFRGreen m2 : 40|8@1+ (1,0) [0|255] "" Vector__XXX
 SG_ LS_rgbIPFRBlue m2 : 48|8@1+ (1,0) [0|255] "" Vector__XXX
 SG_ LS_rgbDoorFLForeRed m3 : 8|8@1+ (1,0) [0|255] "" Vector__XXX
 SG_ LS_rgbDoorFLForeGreen m3 : 16|8@1+ (1,0) [0|255] "" Vector__XXX
 SG_ LS_rgbDoorFLForeBlue m3 : 24|8@1+ (1,0) [0|255] "" Vector__XXX
 SG_ LS_rgbDoorFLAftRed m3 : 32|8@1+ (1,0) [0|255] "" Vector__XXX
 SG_ LS_rgbDoorFLAftGreen m3 : 40|8@1+ (1,0) [0|255] "" Vector__XXX
 SG_ LS_rgbDoorFLAftBlue m3 : 48|8@1+ (1,0) [0|255] "" Vector__XXX
 SG_ LS_rgbDoorFRForeRed m4 : 8|8@1+ (1,0) [0|255] "" Vector__XXX
 SG_ LS_rgbDoorFRForeGreen m4 : 16|8@1+ (1,0) [0|255] "" Vector__XXX
 SG_ LS_rgbDoorFRForeBlue m4 : 24|8@1+ (1,0) [0|255] "" Vector__XXX
 SG_ LS_rgbDoorFRAftRed m4 : 32|8@1+ (1,0) [0|255] "" Vector__XXX
 SG_ LS_rgbDoorFRAftGreen m4 : 40|8@1+ (1,0) [0|255] "" Vector__XXX
 SG_ LS_rgbDoorFRAftBlue m4 : 48|8@1+ (1,0) [0|255] "" Vector__XXX
 SG_ LS_rgbDoorRLForeRed m5 : 8|8@1+ (1,0) [0|255] "" Vector__XXX
 SG_ LS_rgbDoorRLForeGreen m5 : 16|8@1+ (1,0) [0|255] "" Vector__XXX
 SG_ LS_rgbDoorRLForeBlue m5 : 24|8@1+ (1,0) [0|255] "" Vector__XXX
 SG_ LS_rgbDoorRLAftRed m5 : 32|8@1+ (1,0) [0|255] "" Vector__XXX
 SG_ LS_rgbDoorRLAftGreen m5 : 40|8@1+ (1,0) [0|255] "" Vector__XXX
 SG_ LS_rgbDoorRLAftBlue m5 : 48|8@1+ (1,0) [0|255] "" Vector__XXX
 SG_ LS_rgbDoorRRForeRed m6 : 8|8@1+ (1,0) [0|255] "" Vector__XXX
 SG_ LS_rgbDoorRRForeGreen m6 : 16|8@1+ (1,0) [0|255] "" Vector__XXX
 SG_ LS_rgbDoorRRForeBlue m6 : 24|8@1+ (1,0) [0|255] "" Vector__XXX
 SG_ LS_rgbDoorRRAftRed m6 : 32|8@1+ (1,0) [0|255] "" Vector__XXX
 SG_ LS_rgbDoorRRAftGreen m6 : 40|8@1+ (1,0) [0|255] "" Vector__XXX
 SG_ LS_rgbDoorRRAftBlue m6 : 48|8@1+ (1,0) [0|255] "" Vector__XXX
 SG_ LS_frontMatrix0 m7 : 8|8@1+ (1,0) [0|255] "" Vector__XXX
 SG_ LS_frontMatrix1 m7 : 16|8@1+ (1,0) [0|255] "" Vector__XXX
 SG_ LS_frontMatrix2 m7 : 24|8@1+ (1,0) [0|255] "" Vector__XXX
 SG_ LS_frontMatrix3 m7 : 32|8@1+ (1,0) [0|255] "" Vector__XXX
 SG_ LS_frontMatrix4 m7 : 40|8@1+ (1,0) [0|255] "" Vector__XXX
 SG_ LS_frontMatrix5 m7 : 48|8@1+ (1,0) [0|255] "" Vector__XXX
 SG_ LS_frontMatrix6 m7 : 56|8@1+ (1,0) [0|255] "" Vector__XXX
 SG_ LS_frontMatrix7 m8 : 8|8@1+ (1,0) [0|255] "" Vector__XXX
 SG_ LS_frontMatrix8 m8 : 16|8@1+ (1,0) [0|255] "" Vector__XXX
 SG_ LS_frontMatrix9 m8 : 24|8@1+ (1,0) [0|255] "" Vector__XXX
 SG_ LS_frontMatrix10 m8 : 32|8@1+ (1,0) [0|255] "" Vector__XXX
 SG_ LS_frontMatrix11 m8 : 40|8@1+ (1,0) [0|255] "" Vector__XXX
 SG_ LS_frontMatrix12 m8 : 48|8@1+ (1,0) [0|255] "" Vector__XXX
 SG_ LS_frontMatrix13 m8 : 56|8@1+ (1,0) [0|255] "" Vector__XXX
 SG_ LS_frontMatrix14 m9 : 8|8@1+ (1,0) [0|255] "" Vector__XXX
 SG_ LS_frontMatrix15 m9 : 16|8@1+ (1,0) [0|255] "" Vector__XXX
 SG_ LS_frontMatrix16 m9 : 24|8@1+ (1,0) [0|255] "" Vector__XXX
 SG_ LS_frontMatrix17 m9 : 32|8@1+ (1,0) [0|255] "" Vector__XXX
 SG_ LS_frontMatrix18 m9 : 40|8@1+ (1,0) [0|255] "" Vector__XXX
 SG_ LS_frontMatrix19 m9 : 48|8@1+ (1,0) [0|255] "" Vector__XXX
 SG_ LS_frontMatrix20 m9 : 56|8@1+ (1,0) [0|255] "" Vector__XXX
 SG_ LS_frontMatrix21 m10 : 8|8@1+ (1,0) [0|255] "" Vector__XXX
 SG_ LS_frontMatrix22 m10 : 16|8@1+ (1,0) [0|255] "" Vector__XXX
 SG_ LS_frontMatrix23 m10 : 24|8@1+ (1,0) [0|255] "" Vector__XXX
 SG_ LS_frontMatrix24 m10 : 32|8@1+ (1,0) [0|255] "" Vector__XXX
 SG_ LS_frontMatrix25 m10 : 40|8@1+ (1,0) [0|255] "" Vector__XXX
 SG_ LS_frontMatrix26 m10 : 48|8@1+ (1,0) [0|255] "" Vector__XXX
 SG_ LS_frontMatrix27 m10 : 56|8@1+ (1,0) [0|255] "" Vector__XXX
 SG_ LS_frontMatrix28 m11 : 8|8@1+ (1,0) [0|255] "" Vector__XXX
 SG_ LS_frontMatrix29 m11 : 16|8@1+ (1,0) [0|255] "" Vector__XXX
 SG_ LS_frontMatrix30 m11 : 24|8@1+ (1,0) [0|255] "" Vector__XXX
 SG_ LS_frontMatrix31 m11 : 32|8@1+ (1,0) [0|255] "" Vector__XXX
 SG_ LS_frontMatrix32 m11 : 40|8@1+ (1,0) [0|255] "" Vector__XXX
 SG_ LS_frontMatrix33 m11 : 48|8@1+ (1,0) [0|255] "" Vector__XXX
 SG_ LS_frontMatrix34 m11 : 56|8@1+ (1,0) [0|255] "" Vector__XXX
 SG_ LS_frontMatrix35 m12 : 8|8@1+ (1,0) [0|255] "" Vector__XXX
 SG_ LS_frontMatrix36 m12 : 16|8@1+ (1,0) [0|255] "" Vector__XXX
 SG_ LS_frontMatrix37 m12 : 24|8@1+ (1,0) [0|255] "" Vector__XXX
 SG_ LS_frontMatrix38 m12 : 32|8@1+ (1,0) [0|255] "" Vector__XXX
 SG_ LS_frontMatrix39 m12 : 40|8@1+ (1,0) [0|255] "" Vector__XXX
 SG_ LS_frontMatrix40 m12 : 48|8@1+ (1,0) [0|255] "" Vector__XXX
 SG_ LS_frontMatrix41 m12 : 56|8@1+ (1,0) [0|255] "" Vector__XXX
 SG_ LS_frontMatrix42 m13 : 8|8@1+ (1,0) [0|255] "" Vector__XXX
 SG_ LS_frontMatrix43 m13 : 16|8@1+ (1,0) [0|255] "" Vector__XXX
 SG_ LS_frontMatrix44 m13 : 24|8@1+ (1,0) [0|255] "" Vector__XXX
 SG_ LS_frontMatrix45 m13 : 32|8@1+ (1,0) [0|255] "" Vector__XXX
 SG_ LS_frontMatrix46 m13 : 40|8@1+ (1,0) [0|255] "" Vector__XXX
 SG_ LS_frontMatrix47 m13 : 48|8@1+ (1,0) [0|255] "" Vector__XXX
 SG_ LS_frontMatrix48 m13 : 56|8@1+ (1,0) [0|255] "" Vector__XXX
 SG_ LS_frontMatrix49 m14 : 8|8@1+ (1,0) [0|255] "" Vector__XXX
 SG_ LS_frontMatrix50 m14 : 16|8@1+ (1,0) [0|255] "" Vector__XXX
 SG_ LS_frontMatrix51 m14 : 24|8@1+ (1,0) [0|255] "" Vector__XXX
 SG_ LS_frontMatrix52 m14 : 32|8@1+ (1,0) [0|255] "" Vector__XXX
 SG_ LS_frontMatrix53 m14 : 40|8@1+ (1,0) [0|255] "" Vector__XXX
 SG_ LS_frontMatrix54 m14 : 48|8@1+ (1,0) [0|255] "" Vector__XXX
 SG_ LS_frontMatrix55 m14 : 56|8@1+ (1,0) [0|255] "" Vector__XXX
 SG_ LS_frontMatrix56 m15 : 8|8@1+ (1,0) [0|255] "" Vector__XXX
 SG_ LS_frontMatrix57 m15 : 16|8@1+ (1,0) [0|255] "" Vector__XXX
 SG_ LS_frontMatrix58 m15 : 24|8@1+ (1,0) [0|255] "" Vector__XXX
 SG_ LS_frontMatrix59 m15 : 32|8@1+ (1,0) [0|255] "" Vector__XXX
 SG_ LS_rearMatrix0 m15 : 40|8@1+ (1,0) [0|255] "" Vector__XXX
 SG_ LS_rearMatrix1 m15 : 48|8@1+ (1,0) [0|255] "" Vector__XXX
 SG_ LS_rearMatrix2 m15 : 56|8@1+ (1,0) [0|255] "" Vector__XXX
 SG_ LS_rearMatrix3 m16 : 8|8@1+ (1,0) [0|255] "" Vector__XXX
 SG_ LS_rearMatrix4 m16 : 16|8@1+ (1,0) [0|255] "" Vector__XXX
 SG_ LS_rearMatrix5 m16 : 24|8@1+ (1,0) [0|255] "" Vector__XXX
 SG_ LS_rearMatrix6 m16 : 32|8@1+ (1,0) [0|255] "" Vector__XXX
 SG_ LS_rearMatrix7 m16 : 40|8@1+ (1,0) [0|255] "" Vector__XXX
 SG_ LS_rearMatrix8 m16 : 48|8@1+ (1,0) [0|255] "" Vector__XXX
 SG_ LS_rearMatrix9 m16 : 56|8@1+ (1,0) [0|255] "" Vector__XXX
 SG_ LS_rearMatrix10 m17 : 8|8@1+ (1,0) [0|255] "" Vector__XXX
 SG_ LS_rearMatrix11 m17 : 16|8@1+ (1,0) [0|255] "" Vector__XXX
 SG_ LS_rearMatrix12 m17 : 24|8@1+ (1,0) [0|255] "" Vector__XXX
 SG_ LS_rearMatrix13 m17 : 32|8@1+ (1,0) [0|255] "" Vector__XXX
 SG_ LS_rearMatrix14 m17 : 40|8@1+ (1,0) [0|255] "" Vector__XXX
 SG_ LS_rearMatrix15 m17 : 48|8@1+ (1,0) [0|255] "" Vector__XXX
 SG_ LS_rearMatrix16 m17 : 56|8@1+ (1,0) [0|255] "" Vector__XXX
 SG_ LS_rearMatrix17 m18 : 8|8@1+ (1,0) [0|255] "" Vector__XXX
 SG_ LS_rearMatrix18 m18 : 16|8@1+ (1,0) [0|255] "" Vector__XXX
 SG_ LS_rearMatrix19 m18 : 24|8@1+ (1,0) [0|255] "" Vector__XXX
 SG_ LS_rearMatrix20 m18 : 32|8@1+ (1,0) [0|255] "" Vector__XXX
 SG_ LS_rearMatrix21 m18 : 40|8@1+ (1,0) [0|255] "" Vector__XXX
 SG_ LS_rearMatrix22 m18 : 48|8@1+ (1,0) [0|255] "" Vector__XXX
 SG_ LS_rearMatrix23 m18 : 56|8@1+ (1,0) [0|255] "" Vector__XXX
 SG_ LS_rearMatrix24 m19 : 8|8@1+ (1,0) [0|255] "" Vector__XXX
 SG_ LS_rearMatrix25 m19 : 16|8@1+ (1,0) [0|255] "" Vector__XXX
 SG_ LS_rearMatrix26 m19 : 24|8@1+ (1,0) [0|255] "" Vector__XXX
 SG_ LS_rearMatrix27 m19 : 32|8@1+ (1,0) [0|255] "" Vector__XXX
 SG_ LS_rearMatrix28 m19 : 40|8@1+ (1,0) [0|255] "" Vector__XXX
 SG_ LS_rearMatrix29 m19 : 48|8@1+ (1,0) [0|255] "" Vector__XXX
 SG_ LS_rearMatrix30 m19 : 56|8@1+ (1,0) [0|255] "" Vector__XXX
 SG_ LS_rearMatrix31 m20 : 8|8@1+ (1,0) [0|255] "" Vector__XXX
 SG_ LS_rearMatrix32 m20 : 16|8@1+ (1,0) [0|255] "" Vector__XXX
 SG_ LS_rearMatrix33 m20 : 24|8@1+ (1,0) [0|255] "" Vector__XXX
 SG_ LS_rearMatrix34 m20 : 32|8@1+ (1,0) [0|255] "" Vector__XXX
 SG_ LS_rearMatrix35 m20 : 40|8@1+ (1,0) [0|255] "" Vector__XXX
 SG_ LS_rearMatrix36 m20 : 48|8@1+ (1,0) [0|255] "" Vector__XXX
 SG_ LS_rearMatrix37 m20 : 56|8@1+ (1,0) [0|255] "" Vector__XXX
 SG_ LS_rearMatrix38 m21 : 8|8@1+ (1,0) [0|255] "" Vector__XXX
 SG_ LS_rearMatrix39 m21 : 16|8@1+ (1,0) [0|255] "" Vector__XXX
 SG_ LS_rearMatrix40 m21 : 24|8@1+ (1,0) [0|255] "" Vector__XXX
 SG_ LS_rearMatrix41 m21 : 32|8@1+ (1,0) [0|255] "" Vector__XXX
 SG_ LS_rearMatrix42 m21 : 40|8@1+ (1,0) [0|255] "" Vector__XXX
 SG_ LS_rearMatrix43 m21 : 48|8@1+ (1,0) [0|255] "" Vector__XXX
 SG_ LS_rearMatrix44 m21 : 56|8@1+ (1,0) [0|255] "" Vector__XXX
 SG_ LS_rearMatrix45 m22 : 8|8@1+ (1,0) [0|255] "" Vector__XXX
 SG_ LS_rearMatrix46 m22 : 16|8@1+ (1,0) [0|255] "" Vector__XXX
 SG_ LS_rearMatrix47 m22 : 24|8@1+ (1,0) [0|255] "" Vector__XXX
 SG_ LS_rearMatrix48 m22 : 32|8@1+ (1,0) [0|255] "" Vector__XXX
 SG_ LS_rearMatrix49 m22 : 40|8@1+ (1,0) [0|255] "" Vector__XXX
 SG_ LS_rearMatrix50 m22 : 48|8@1+ (1,0) [0|255] "" Vector__XXX
 SG_ LS_rearMatrix51 m22 : 56|8@1+ (1,0) [0|255] "" Vector__XXX
 SG_ LS_rearMatrix52 m23 : 8|8@1+ (1,0) [0|255] "" Vector__XXX
 SG_ LS_rearMatrix53 m23 : 16|8@1+ (1,0) [0|255] "" Vector__XXX
 SG_ LS_rearMatrix54 m23 : 24|8@1+ (1,0) [0|255] "" Vector__XXX
 SG_ LS_rearMatrix55 m23 : 32|8@1+ (1,0) [0|255] "" Vector__XXX
 SG_ LS_rearMatrix56 m23 : 40|8@1+ (1,0) [0|255] "" Vector__XXX
 SG_ LS_rearMatrix57 m23 : 48|8@1+ (1,0) [0|255] "" Vector__XXX
 SG_ LS_rearMatrix58 m23 : 56|8@1+ (1,0) [0|255] "" Vector__XXX
 SG_ LS_rearMatrix59 m24 : 8|8@1+ (1,0) [0|255] "" Vector__XXX
 SG_ LS_offroadLightBar0 m24 : 16|8@1+ (1,0) [0|255] "" Vector__XXX
 SG_ LS_offroadLightBar1 m24 : 24|8@1+ (1,0) [0|255] "" Vector__XXX
 SG_ LS_offroadLightBar2 m24 : 32|8@1+ (1,0) [0|255] "" Vector__XXX
 SG_ LS_offroadLightBar3 m24 : 40|8@1+ (1,0) [0|255] "" Vector__XXX
 SG_ LS_offroadLightBar4 m24 : 48|8@1+ (1,0) [0|255] "" Vector__XXX
 SG_ LS_offroadLightBar5 m24 : 56|8@1+ (1,0) [0|255] "" Vector__XXX

BO_ 1429 OCS1P_alertLog: 8 OCS1P
 SG_ OCS1P_alertID M : 0|8@1+ (1,0) [0|255] "" Vector__XXX
 SG_ OCS1P_alertState : 15|1@1+ (1,0) [0|1] "" Vector__XXX
 SG_ OCS1P_a121_sandwichFreq m121 : 16|32@1+ (1,0) [0|4294967295] "" Vector__XXX
 SG_ OCS1P_a122_sandwichFreq m122 : 16|32@1+ (1,0) [0|4294967295] "" Vector__XXX
 SG_ OCS1P_a123_sandwichFreq m123 : 16|32@1+ (1,0) [0|4294967295] "" Vector__XXX
 SG_ OCS1P_a124_cushionSelfFreq m124 : 16|32@1+ (1,0) [0|4294967295] "" Vector__XXX
 SG_ OCS1P_a125_cushionSelfFreq m125 : 16|32@1+ (1,0) [0|4294967295] "" Vector__XXX
 SG_ OCS1P_a126_cushionSelfFreq m126 : 16|32@1+ (1,0) [0|4294967295] "" Vector__XXX
 SG_ OCS1P_a127_seatbackSelfFreq m127 : 16|32@1+ (1,0) [0|4294967295] "" Vector__XXX
 SG_ OCS1P_a128_seatbackSelfFreq m128 : 16|32@1+ (1,0) [0|4294967295] "" Vector__XXX
 SG_ OCS1P_a129_seatbackSelfFreq m129 : 16|32@1+ (1,0) [0|4294967295] "" Vector__XXX
 SG_ OCS1P_a130_sandwichNoCalib m130 : 16|1@1+ (1,0) [0|1] "" Vector__XXX
 SG_ OCS1P_a131_cushionSelfNoCalib m131 : 16|1@1+ (1,0) [0|1] "" Vector__XXX
 SG_ OCS1P_a132_seatbackSelfNoCalib m132 : 16|1@1+ (1,0) [0|1] "" Vector__XXX
 SG_ OCS1P_a133_sandwichBadCalib m133 : 16|1@1+ (1,0) [0|1] "" Vector__XXX
 SG_ OCS1P_a134_uninitializedCalib m134 : 16|1@1+ (1,0) [0|1] "" Vector__XXX
 SG_ OCS1P_a135_tempNoCalib m135 : 16|1@1+ (1,0) [0|1] "" Vector__XXX
 SG_ OCS1P_a140_tempInvalidCalib m140 : 16|1@1+ (1,0) [0|1] "" Vector__XXX
 SG_ OCS1P_a141_humidityInvalidCalib m141 : 16|1@1+ (1,0) [0|1] "" Vector__XXX
 SG_ OCS1P_a142_tempHumidityInvalid m142 : 16|1@1+ (1,0) [0|1] "" Vector__XXX
 SG_ OCS1P_a143_mismatchPassAirbag m143 : 16|1@1+ (1,0) [0|1] "" Vector__XXX
 SG_ OCS1P_a144_mismatchCarRegion m144 : 16|1@1+ (1,0) [0|1] "" Vector__XXX

BO_ 767 OCS1P_alertMatrix: 8 OCS1P
 SG_ OCS1P_matrixIndex M : 0|4@1+ (1,0) [0|15] "" Vector__XXX
 SG_ OCS1P_w015_NVMMAlert m0 : 18|1@1+ (1,0) [0|1] "" Vector__XXX
 SG_ OCS1P_w121_sandwichOpen m2 : 4|1@1+ (1,0) [0|1] "" Vector__XXX
 SG_ OCS1P_w122_sandwichLow m2 : 5|1@1+ (1,0) [0|1] "" Vector__XXX
 SG_ OCS1P_w123_sandwichShort m2 : 6|1@1+ (1,0) [0|1] "" Vector__XXX
 SG_ OCS1P_w124_cushionSelfOpen m2 : 7|1@1+ (1,0) [0|1] "" Vector__XXX
 SG_ OCS1P_w125_cushionSelfLow m2 : 8|1@1+ (1,0) [0|1] "" Vector__XXX
 SG_ OCS1P_w126_cushionSelfShort m2 : 9|1@1+ (1,0) [0|1] "" Vector__XXX
 SG_ OCS1P_w127_seatbackSelfOpen m2 : 10|1@1+ (1,0) [0|1] "" Vector__XXX
 SG_ OCS1P_w128_seatbackSelfLow m2 : 11|1@1+ (1,0) [0|1] "" Vector__XXX
 SG_ OCS1P_w129_seatbackSelfShort m2 : 12|1@1+ (1,0) [0|1] "" Vector__XXX
 SG_ OCS1P_w130_sandwichNoCalib m2 : 13|1@1+ (1,0) [0|1] "" Vector__XXX
 SG_ OCS1P_w131_cushionSelfNoCalib m2 : 14|1@1+ (1,0) [0|1] "" Vector__XXX
 SG_ OCS1P_w132_seatbackSelfNoCalib m2 : 15|1@1+ (1,0) [0|1] "" Vector__XXX
 SG_ OCS1P_w133_sandwichBadCalib m2 : 16|1@1+ (1,0) [0|1] "" Vector__XXX
 SG_ OCS1P_w134_uninitializedCalib m2 : 17|1@1+ (1,0) [0|1] "" Vector__XXX
 SG_ OCS1P_w135_tempNoCalib m2 : 18|1@1+ (1,0) [0|1] "" Vector__XXX
 SG_ OCS1P_w136_cushionSelfDutyLow m2 : 19|1@1+ (1,0) [0|1] "" Vector__XXX
 SG_ OCS1P_w137_cushionSelfDutyHigh m2 : 20|1@1+ (1,0) [0|1] "" Vector__XXX
 SG_ OCS1P_w138_seatbackSelfDutyLow m2 : 21|1@1+ (1,0) [0|1] "" Vector__XXX
 SG_ OCS1P_w139_seatbackSelfDutyHigh m2 : 22|1@1+ (1,0) [0|1] "" Vector__XXX
 SG_ OCS1P_w140_tempInvalidCalib m2 : 23|1@1+ (1,0) [0|1] "" Vector__XXX
 SG_ OCS1P_w141_humidityInvalidCalib m2 : 24|1@1+ (1,0) [0|1] "" Vector__XXX
 SG_ OCS1P_w142_tempHumidityInvalid m2 : 25|1@1+ (1,0) [0|1] "" Vector__XXX
 SG_ OCS1P_w143_mismatchPassAirbag m2 : 26|1@1+ (1,0) [0|1] "" Vector__XXX
 SG_ OCS1P_w144_mismatchCarRegion m2 : 27|1@1+ (1,0) [0|1] "" Vector__XXX
 SG_ OCS1P_w145_rebaselineTriggered m2 : 28|1@1+ (1,0) [0|1] "" Vector__XXX
 SG_ OCS1P_w148_classificationMismatc m2 : 31|1@1+ (1,0) [0|1] "" Vector__XXX
 SG_ OCS1P_w150_rbEntryTriggered m2 : 33|1@1+ (1,0) [0|1] "" Vector__XXX
 SG_ OCS1P_w151_rbEntryExited m2 : 34|1@1+ (1,0) [0|1] "" Vector__XXX
 SG_ OCS1P_w152_rbExit1Triggered m2 : 35|1@1+ (1,0) [0|1] "" Vector__XXX
 SG_ OCS1P_w153_rbExit1Exited m2 : 36|1@1+ (1,0) [0|1] "" Vector__XXX
 SG_ OCS1P_w154_rbExit2Exited1 m2 : 37|1@1+ (1,0) [0|1] "" Vector__XXX
 SG_ OCS1P_w155_rbExit2Exited2 m2 : 38|1@1+ (1,0) [0|1] "" Vector__XXX
 SG_ OCS1P_w156_seatbeltReminderUnava m2 : 39|1@1+ (1,0) [0|1] "" Vector__XXX

BO_ 766 OCS1P_info: 8 OCS1P
 SG_ OCS1P_infoIndex M : 0|8@1+ (1,0) [0|255] "" Vector__XXX
 SG_ OCS1P_infoBuildType m10 : 8|8@1+ (1,0) [0|255] "" Vector__XXX
 SG_ OCS1P_infoBuildConfigID m10 : 16|16@1+ (1,0) [0|65535] "" Vector__XXX
 SG_ OCS1P_infoHardwareID m10 : 32|16@1+ (1,0) [0|65535] "" Vector__XXX
 SG_ OCS1P_infoComponentID m10 : 48|16@1+ (1,0) [0|65535] "" Vector__XXX
 SG_ OCS1P_infoPcbaID m11 : 16|8@1+ (1,0) [0|255] "" Vector__XXX
 SG_ OCS1P_infoAssemblyID m11 : 24|8@1+ (1,0) [0|255] "" Vector__XXX
 SG_ OCS1P_infoUsageID m11 : 32|16@1+ (1,0) [0|65535] "" Vector__XXX
 SG_ OCS1P_infoSubUsageID m11 : 48|16@1+ (1,0) [0|65535] "" Vector__XXX
 SG_ OCS1P_infoApplicationCRC m13 : 32|32@1+ (1,0) [0|4294967295] "" Vector__XXX
 SG_ OCS1P_infoBootSvnRev m14 : 8|24@1+ (1,0) [0|16777215] "" Vector__XXX
 SG_ OCS1P_infoAppGitHashBytes m17 : 8|56@1+ (1,0) [0|7.20575940379e+16] "" Vector__XXX
 SG_ OCS1P_infoBootGitHashBytes m18 : 8|56@1+ (1,0) [0|7.20575940379e+16] "" Vector__XXX
 SG_ OCS1P_infoPlatformType m19 : 8|8@1+ (1,0) [0|255] "" Vector__XXX
 SG_ OCS1P_infoBootUdsProtoVersion m20 : 8|8@1+ (1,0) [0|255] "" Vector__XXX
 SG_ OCS1P_infoBootloaderCRC m20 : 32|32@1+ (1,0) [0|4294967295] "" Vector__XXX

BO_ 771 OCS1P_status: 8 OCS1P
 SG_ OCS1P_occupantClassification : 0|8@1+ (1,0) [0|254] "" Vector__XXX
 SG_ OCS1P_occupantClassificationQF : 8|1@1+ (1,0) [0|1] "" Vector__XXX
 SG_ OCS1P_occupiedState : 9|2@1+ (1,0) [0|2] "" Vector__XXX
 SG_ OCS1P_triggerSnapshot : 11|5@1+ (1,0) [0|31] "" Vector__XXX
 SG_ OCS1P_occupantClassificationRaw : 16|3@1+ (1,0) [0|6] "" Vector__XXX
 SG_ OCS1P_occupantClassificationSelf : 19|3@1+ (1,0) [0|6] "" Vector__XXX
 SG_ OCS1P_occupantClassificationRawC : 22|3@1+ (1,0) [0|6] "" Vector__XXX
 SG_ OCS1P_occupantClassificationCap : 25|3@1+ (1,0) [0|6] "" Vector__XXX
 SG_ OCS1P_classificationHeld : 30|1@1+ (1,0) [0|1] "" Vector__XXX
 SG_ OCS1P_cushionStable : 31|1@1+ (1,0) [0|1] "" Vector__XXX
 SG_ OCS1P_classificationExtHold : 32|1@1+ (1,0) [0|1] "" Vector__XXX
 SG_ OCS1P_classificationHoldState : 33|3@1+ (1,0) [0|7] "" Vector__XXX
 SG_ OCS1P_classificationVariant : 36|3@1+ (1,0) [0|7] "" Vector__XXX
 SG_ OCS1P_sandwichDisabled : 39|1@1+ (1,0) [0|1] "" Vector__XXX
 SG_ OCS1P_noSandwichType : 40|2@1+ (1,0) [0|3] "" Vector__XXX
 SG_ OCS1P_sandwichBoundaryType : 42|1@1+ (1,0) [0|1] "" Vector__XXX
 SG_ OCS1P_sbrBoundaryType : 43|1@1+ (1,0) [0|1] "" Vector__XXX
 SG_ OCS1P_occupiedStateCap : 45|2@1+ (1,0) [0|2] "" Vector__XXX
 SG_ OCS1P_seatbackStable : 47|1@1+ (1,0) [0|1] "" Vector__XXX
 SG_ OCS1P_sandwichStable : 48|1@1+ (1,0) [0|1] "" Vector__XXX
 SG_ OCS1P_cushionStableCap : 49|1@1+ (1,0) [0|1] "" Vector__XXX
 SG_ OCS1P_seatbackStableCap : 50|1@1+ (1,0) [0|1] "" Vector__XXX
 SG_ OCS1P_classificationHeldCap : 51|1@1+ (1,0) [0|1] "" Vector__XXX
 SG_ OCS1P_statusCounter : 52|4@1+ (1,0) [0|15] "" Vector__XXX
 SG_ OCS1P_statusChecksum : 56|8@1+ (1,0) [0|255] "" Vector__XXX

BO_ 1486 PARK_alertLog: 8 PARK
 SG_ PARK_alertID M : 0|7@1+ (1,0) [0|127] "" Vector__XXX
 SG_ PARK_alertState : 15|1@1+ (1,0) [0|1] "" Vector__XXX
 SG_ PARK_sw001_sensorTemperature m1 : 16|16@1+ (0.1,-40) [-40|6513.5] "deg" Vector__XXX
 SG_ PARK_sw002_membraneDisconct m2 : 16|1@1+ (1,0) [0|1] "" Vector__XXX
 SG_ PARK_sw002_dampResistorFail m2 : 17|1@1+ (1,0) [0|1] "" Vector__XXX
 SG_ PARK_sw002_resonanceDrift m2 : 18|1@1+ (1,0) [0|1] "" Vector__XXX
 SG_ PARK_sw002_sensorCRC m2 : 19|1@1+ (1,0) [0|1] "" Vector__XXX
 SG_ PARK_sw002_recieveFailure m2 : 20|1@1+ (1,0) [0|1] "" Vector__XXX
 SG_ PARK_sw002_diagnosticTransferErr m2 : 21|1@1+ (1,0) [0|1] "" Vector__XXX
 SG_ PARK_sw003_linError m3 : 16|1@1+ (1,0) [0|1] "" Vector__XXX
 SG_ PARK_sw003_linBusError m3 : 17|1@1+ (1,0) [0|1] "" Vector__XXX
 SG_ PARK_sw003_linFrameCountError m3 : 18|1@1+ (1,0) [0|1] "" Vector__XXX
 SG_ PARK_sw004_reverbPeriod m4 : 16|16@1+ (1,0) [0|65535] "microseconds" Vector__XXX
 SG_ PARK_sw004_reverbTime m4 : 32|16@1+ (1,0) [0|65535] "microseconds" Vector__XXX
 SG_ PARK_sw004_highAttenTime m4 : 48|1@1+ (1,0) [0|1] "" Vector__XXX
 SG_ PARK_sw004_closeConstEcho m4 : 49|1@1+ (1,0) [0|1] "" Vector__XXX
 SG_ PARK_sw004_lowAttenTime m4 : 50|1@1+ (1,0) [0|1] "" Vector__XXX
 SG_ PARK_sw004_attenTimeJitter m4 : 51|1@1+ (1,0) [0|1] "" Vector__XXX
 SG_ PARK_sw004_reverbFreqJitter m4 : 52|1@1+ (1,0) [0|1] "" Vector__XXX
 SG_ PARK_sw006_sensorTemperature m6 : 16|16@1+ (0.1,-40) [-40|6513.5] "deg" Vector__XXX
 SG_ PARK_sw007_membraneDisconct m7 : 16|1@1+ (1,0) [0|1] "" Vector__XXX
 SG_ PARK_sw007_dampResistorFail m7 : 17|1@1+ (1,0) [0|1] "" Vector__XXX
 SG_ PARK_sw007_resonanceDrift m7 : 18|1@1+ (1,0) [0|1] "" Vector__XXX
 SG_ PARK_sw007_sensorCRC m7 : 19|1@1+ (1,0) [0|1] "" Vector__XXX
 SG_ PARK_sw007_recieveFailure m7 : 20|1@1+ (1,0) [0|1] "" Vector__XXX
 SG_ PARK_sw007_diagnosticTransferErr m7 : 21|1@1+ (1,0) [0|1] "" Vector__XXX
 SG_ PARK_sw008_linError m8 : 16|1@1+ (1,0) [0|1] "" Vector__XXX
 SG_ PARK_sw008_linBusError m8 : 17|1@1+ (1,0) [0|1] "" Vector__XXX
 SG_ PARK_sw008_linFrameCountError m8 : 18|1@1+ (1,0) [0|1] "" Vector__XXX
 SG_ PARK_sw009_reverbPeriod m9 : 16|16@1+ (1,0) [0|65535] "microseconds" Vector__XXX
 SG_ PARK_sw009_reverbTime m9 : 32|16@1+ (1,0) [0|65535] "microseconds" Vector__XXX
 SG_ PARK_sw009_highAttenTime m9 : 48|1@1+ (1,0) [0|1] "" Vector__XXX
 SG_ PARK_sw009_closeConstEcho m9 : 49|1@1+ (1,0) [0|1] "" Vector__XXX
 SG_ PARK_sw009_lowAttenTime m9 : 50|1@1+ (1,0) [0|1] "" Vector__XXX
 SG_ PARK_sw009_attenTimeJitter m9 : 51|1@1+ (1,0) [0|1] "" Vector__XXX
 SG_ PARK_sw009_reverbFreqJitter m9 : 52|1@1+ (1,0) [0|1] "" Vector__XXX
 SG_ PARK_sw011_sensorTemperature m11 : 16|16@1+ (0.1,-40) [-40|6513.5] "deg" Vector__XXX
 SG_ PARK_sw012_membraneDisconct m12 : 16|1@1+ (1,0) [0|1] "" Vector__XXX
 SG_ PARK_sw012_dampResistorFail m12 : 17|1@1+ (1,0) [0|1] "" Vector__XXX
 SG_ PARK_sw012_resonanceDrift m12 : 18|1@1+ (1,0) [0|1] "" Vector__XXX
 SG_ PARK_sw012_sensorCRC m12 : 19|1@1+ (1,0) [0|1] "" Vector__XXX
 SG_ PARK_sw012_recieveFailure m12 : 20|1@1+ (1,0) [0|1] "" Vector__XXX
 SG_ PARK_sw012_diagnosticTransferErr m12 : 21|1@1+ (1,0) [0|1] "" Vector__XXX
 SG_ PARK_sw013_linError m13 : 16|1@1+ (1,0) [0|1] "" Vector__XXX
 SG_ PARK_sw013_linBusError m13 : 17|1@1+ (1,0) [0|1] "" Vector__XXX
 SG_ PARK_sw013_linFrameCountError m13 : 18|1@1+ (1,0) [0|1] "" Vector__XXX
 SG_ PARK_sw014_reverbPeriod m14 : 16|16@1+ (1,0) [0|65535] "microseconds" Vector__XXX
 SG_ PARK_sw014_reverbTime m14 : 32|16@1+ (1,0) [0|65535] "microseconds" Vector__XXX
 SG_ PARK_sw014_highAttenTime m14 : 48|1@1+ (1,0) [0|1] "" Vector__XXX
 SG_ PARK_sw014_closeConstEcho m14 : 49|1@1+ (1,0) [0|1] "" Vector__XXX
 SG_ PARK_sw014_lowAttenTime m14 : 50|1@1+ (1,0) [0|1] "" Vector__XXX
 SG_ PARK_sw014_attenTimeJitter m14 : 51|1@1+ (1,0) [0|1] "" Vector__XXX
 SG_ PARK_sw014_reverbFreqJitter m14 : 52|1@1+ (1,0) [0|1] "" Vector__XXX
 SG_ PARK_sw016_sensorTemperature m16 : 16|16@1+ (0.1,-40) [-40|6513.5] "deg" Vector__XXX
 SG_ PARK_sw017_membraneDisconct m17 : 16|1@1+ (1,0) [0|1] "" Vector__XXX
 SG_ PARK_sw017_dampResistorFail m17 : 17|1@1+ (1,0) [0|1] "" Vector__XXX
 SG_ PARK_sw017_resonanceDrift m17 : 18|1@1+ (1,0) [0|1] "" Vector__XXX
 SG_ PARK_sw017_sensorCRC m17 : 19|1@1+ (1,0) [0|1] "" Vector__XXX
 SG_ PARK_sw017_recieveFailure m17 : 20|1@1+ (1,0) [0|1] "" Vector__XXX
 SG_ PARK_sw017_diagnosticTransferErr m17 : 21|1@1+ (1,0) [0|1] "" Vector__XXX
 SG_ PARK_sw018_linError m18 : 16|1@1+ (1,0) [0|1] "" Vector__XXX
 SG_ PARK_sw018_linBusError m18 : 17|1@1+ (1,0) [0|1] "" Vector__XXX
 SG_ PARK_sw018_linFrameCountError m18 : 18|1@1+ (1,0) [0|1] "" Vector__XXX
 SG_ PARK_sw019_reverbPeriod m19 : 16|16@1+ (1,0) [0|65535] "microseconds" Vector__XXX
 SG_ PARK_sw019_reverbTime m19 : 32|16@1+ (1,0) [0|65535] "microseconds" Vector__XXX
 SG_ PARK_sw019_highAttenTime m19 : 48|1@1+ (1,0) [0|1] "" Vector__XXX
 SG_ PARK_sw019_closeConstEcho m19 : 49|1@1+ (1,0) [0|1] "" Vector__XXX
 SG_ PARK_sw019_lowAttenTime m19 : 50|1@1+ (1,0) [0|1] "" Vector__XXX
 SG_ PARK_sw019_attenTimeJitter m19 : 51|1@1+ (1,0) [0|1] "" Vector__XXX
 SG_ PARK_sw019_reverbFreqJitter m19 : 52|1@1+ (1,0) [0|1] "" Vector__XXX
 SG_ PARK_sw021_sensorTemperature m21 : 16|16@1+ (0.1,-40) [-40|6513.5] "deg" Vector__XXX
 SG_ PARK_sw022_membraneDisconct m22 : 16|1@1+ (1,0) [0|1] "" Vector__XXX
 SG_ PARK_sw022_dampResistorFail m22 : 17|1@1+ (1,0) [0|1] "" Vector__XXX
 SG_ PARK_sw022_resonanceDrift m22 : 18|1@1+ (1,0) [0|1] "" Vector__XXX
 SG_ PARK_sw022_sensorCRC m22 : 19|1@1+ (1,0) [0|1] "" Vector__XXX
 SG_ PARK_sw022_recieveFailure m22 : 20|1@1+ (1,0) [0|1] "" Vector__XXX
 SG_ PARK_sw022_diagnosticTransferErr m22 : 21|1@1+ (1,0) [0|1] "" Vector__XXX
 SG_ PARK_sw023_linError m23 : 16|1@1+ (1,0) [0|1] "" Vector__XXX
 SG_ PARK_sw023_linBusError m23 : 17|1@1+ (1,0) [0|1] "" Vector__XXX
 SG_ PARK_sw023_linFrameCountError m23 : 18|1@1+ (1,0) [0|1] "" Vector__XXX
 SG_ PARK_sw024_reverbPeriod m24 : 16|16@1+ (1,0) [0|65535] "microseconds" Vector__XXX
 SG_ PARK_sw024_reverbTime m24 : 32|16@1+ (1,0) [0|65535] "microseconds" Vector__XXX
 SG_ PARK_sw024_highAttenTime m24 : 48|1@1+ (1,0) [0|1] "" Vector__XXX
 SG_ PARK_sw024_closeConstEcho m24 : 49|1@1+ (1,0) [0|1] "" Vector__XXX
 SG_ PARK_sw024_lowAttenTime m24 : 50|1@1+ (1,0) [0|1] "" Vector__XXX
 SG_ PARK_sw024_attenTimeJitter m24 : 51|1@1+ (1,0) [0|1] "" Vector__XXX
 SG_ PARK_sw024_reverbFreqJitter m24 : 52|1@1+ (1,0) [0|1] "" Vector__XXX
 SG_ PARK_sw026_sensorTemperature m26 : 16|16@1+ (0.1,-40) [-40|6513.5] "deg" Vector__XXX
 SG_ PARK_sw027_membraneDisconct m27 : 16|1@1+ (1,0) [0|1] "" Vector__XXX
 SG_ PARK_sw027_dampResistorFail m27 : 17|1@1+ (1,0) [0|1] "" Vector__XXX
 SG_ PARK_sw027_resonanceDrift m27 : 18|1@1+ (1,0) [0|1] "" Vector__XXX
 SG_ PARK_sw027_sensorCRC m27 : 19|1@1+ (1,0) [0|1] "" Vector__XXX
 SG_ PARK_sw027_recieveFailure m27 : 20|1@1+ (1,0) [0|1] "" Vector__XXX
 SG_ PARK_sw027_diagnosticTransferErr m27 : 21|1@1+ (1,0) [0|1] "" Vector__XXX
 SG_ PARK_sw028_linError m28 : 16|1@1+ (1,0) [0|1] "" Vector__XXX
 SG_ PARK_sw028_linBusError m28 : 17|1@1+ (1,0) [0|1] "" Vector__XXX
 SG_ PARK_sw028_linFrameCountError m28 : 18|1@1+ (1,0) [0|1] "" Vector__XXX
 SG_ PARK_sw029_reverbPeriod m29 : 16|16@1+ (1,0) [0|65535] "microseconds" Vector__XXX
 SG_ PARK_sw029_reverbTime m29 : 32|16@1+ (1,0) [0|65535] "microseconds" Vector__XXX
 SG_ PARK_sw029_highAttenTime m29 : 48|1@1+ (1,0) [0|1] "" Vector__XXX
 SG_ PARK_sw029_closeConstEcho m29 : 49|1@1+ (1,0) [0|1] "" Vector__XXX
 SG_ PARK_sw029_lowAttenTime m29 : 50|1@1+ (1,0) [0|1] "" Vector__XXX
 SG_ PARK_sw029_attenTimeJitter m29 : 51|1@1+ (1,0) [0|1] "" Vector__XXX
 SG_ PARK_sw029_reverbFreqJitter m29 : 52|1@1+ (1,0) [0|1] "" Vector__XXX
 SG_ PARK_sw031_sensorTemperature m31 : 16|16@1+ (0.1,-40) [-40|6513.5] "deg" Vector__XXX
 SG_ PARK_sw032_membraneDisconct m32 : 16|1@1+ (1,0) [0|1] "" Vector__XXX
 SG_ PARK_sw032_dampResistorFail m32 : 17|1@1+ (1,0) [0|1] "" Vector__XXX
 SG_ PARK_sw032_resonanceDrift m32 : 18|1@1+ (1,0) [0|1] "" Vector__XXX
 SG_ PARK_sw032_sensorCRC m32 : 19|1@1+ (1,0) [0|1] "" Vector__XXX
 SG_ PARK_sw032_recieveFailure m32 : 20|1@1+ (1,0) [0|1] "" Vector__XXX
 SG_ PARK_sw032_diagnosticTransferErr m32 : 21|1@1+ (1,0) [0|1] "" Vector__XXX
 SG_ PARK_sw033_linError m33 : 16|1@1+ (1,0) [0|1] "" Vector__XXX
 SG_ PARK_sw033_linBusError m33 : 17|1@1+ (1,0) [0|1] "" Vector__XXX
 SG_ PARK_sw033_linFrameCountError m33 : 18|1@1+ (1,0) [0|1] "" Vector__XXX
 SG_ PARK_sw034_reverbPeriod m34 : 16|16@1+ (1,0) [0|65535] "microseconds" Vector__XXX
 SG_ PARK_sw034_reverbTime m34 : 32|16@1+ (1,0) [0|65535] "microseconds" Vector__XXX
 SG_ PARK_sw034_highAttenTime m34 : 48|1@1+ (1,0) [0|1] "" Vector__XXX
 SG_ PARK_sw034_closeConstEcho m34 : 49|1@1+ (1,0) [0|1] "" Vector__XXX
 SG_ PARK_sw034_lowAttenTime m34 : 50|1@1+ (1,0) [0|1] "" Vector__XXX
 SG_ PARK_sw034_attenTimeJitter m34 : 51|1@1+ (1,0) [0|1] "" Vector__XXX
 SG_ PARK_sw034_reverbFreqJitter m34 : 52|1@1+ (1,0) [0|1] "" Vector__XXX
 SG_ PARK_sw036_sensorTemperature m36 : 16|16@1+ (0.1,-40) [-40|6513.5] "deg" Vector__XXX
 SG_ PARK_sw037_membraneDisconct m37 : 16|1@1+ (1,0) [0|1] "" Vector__XXX
 SG_ PARK_sw037_dampResistorFail m37 : 17|1@1+ (1,0) [0|1] "" Vector__XXX
 SG_ PARK_sw037_resonanceDrift m37 : 18|1@1+ (1,0) [0|1] "" Vector__XXX
 SG_ PARK_sw037_sensorCRC m37 : 19|1@1+ (1,0) [0|1] "" Vector__XXX
 SG_ PARK_sw037_recieveFailure m37 : 20|1@1+ (1,0) [0|1] "" Vector__XXX
 SG_ PARK_sw037_diagnosticTransferErr m37 : 21|1@1+ (1,0) [0|1] "" Vector__XXX
 SG_ PARK_sw038_linError m38 : 16|1@1+ (1,0) [0|1] "" Vector__XXX
 SG_ PARK_sw038_linBusError m38 : 17|1@1+ (1,0) [0|1] "" Vector__XXX
 SG_ PARK_sw038_linFrameCountError m38 : 18|1@1+ (1,0) [0|1] "" Vector__XXX
 SG_ PARK_sw039_reverbPeriod m39 : 16|16@1+ (1,0) [0|65535] "microseconds" Vector__XXX
 SG_ PARK_sw039_reverbTime m39 : 32|16@1+ (1,0) [0|65535] "microseconds" Vector__XXX
 SG_ PARK_sw039_highAttenTime m39 : 48|1@1+ (1,0) [0|1] "" Vector__XXX
 SG_ PARK_sw039_closeConstEcho m39 : 49|1@1+ (1,0) [0|1] "" Vector__XXX
 SG_ PARK_sw039_lowAttenTime m39 : 50|1@1+ (1,0) [0|1] "" Vector__XXX
 SG_ PARK_sw039_attenTimeJitter m39 : 51|1@1+ (1,0) [0|1] "" Vector__XXX
 SG_ PARK_sw039_reverbFreqJitter m39 : 52|1@1+ (1,0) [0|1] "" Vector__XXX
 SG_ PARK_sw041_sensorTemperature m41 : 16|16@1+ (0.1,-40) [-40|6513.5] "deg" Vector__XXX
 SG_ PARK_sw042_membraneDisconct m42 : 16|1@1+ (1,0) [0|1] "" Vector__XXX
 SG_ PARK_sw042_dampResistorFail m42 : 17|1@1+ (1,0) [0|1] "" Vector__XXX
 SG_ PARK_sw042_resonanceDrift m42 : 18|1@1+ (1,0) [0|1] "" Vector__XXX
 SG_ PARK_sw042_sensorCRC m42 : 19|1@1+ (1,0) [0|1] "" Vector__XXX
 SG_ PARK_sw042_recieveFailure m42 : 20|1@1+ (1,0) [0|1] "" Vector__XXX
 SG_ PARK_sw042_diagnosticTransferErr m42 : 21|1@1+ (1,0) [0|1] "" Vector__XXX
 SG_ PARK_sw043_linError m43 : 16|1@1+ (1,0) [0|1] "" Vector__XXX
 SG_ PARK_sw043_linBusError m43 : 17|1@1+ (1,0) [0|1] "" Vector__XXX
 SG_ PARK_sw043_linFrameCountError m43 : 18|1@1+ (1,0) [0|1] "" Vector__XXX
 SG_ PARK_sw044_reverbPeriod m44 : 16|16@1+ (1,0) [0|65535] "microseconds" Vector__XXX
 SG_ PARK_sw044_reverbTime m44 : 32|16@1+ (1,0) [0|65535] "microseconds" Vector__XXX
 SG_ PARK_sw044_highAttenTime m44 : 48|1@1+ (1,0) [0|1] "" Vector__XXX
 SG_ PARK_sw044_closeConstEcho m44 : 49|1@1+ (1,0) [0|1] "" Vector__XXX
 SG_ PARK_sw044_lowAttenTime m44 : 50|1@1+ (1,0) [0|1] "" Vector__XXX
 SG_ PARK_sw044_attenTimeJitter m44 : 51|1@1+ (1,0) [0|1] "" Vector__XXX
 SG_ PARK_sw044_reverbFreqJitter m44 : 52|1@1+ (1,0) [0|1] "" Vector__XXX
 SG_ PARK_sw046_sensorTemperature m46 : 16|16@1+ (0.1,-40) [-40|6513.5] "deg" Vector__XXX
 SG_ PARK_sw047_membraneDisconct m47 : 16|1@1+ (1,0) [0|1] "" Vector__XXX
 SG_ PARK_sw047_dampResistorFail m47 : 17|1@1+ (1,0) [0|1] "" Vector__XXX
 SG_ PARK_sw047_resonanceDrift m47 : 18|1@1+ (1,0) [0|1] "" Vector__XXX
 SG_ PARK_sw047_sensorCRC m47 : 19|1@1+ (1,0) [0|1] "" Vector__XXX
 SG_ PARK_sw047_recieveFailure m47 : 20|1@1+ (1,0) [0|1] "" Vector__XXX
 SG_ PARK_sw047_diagnosticTransferErr m47 : 21|1@1+ (1,0) [0|1] "" Vector__XXX
 SG_ PARK_sw048_linError m48 : 16|1@1+ (1,0) [0|1] "" Vector__XXX
 SG_ PARK_sw048_linBusError m48 : 17|1@1+ (1,0) [0|1] "" Vector__XXX
 SG_ PARK_sw048_linFrameCountError m48 : 18|1@1+ (1,0) [0|1] "" Vector__XXX
 SG_ PARK_sw049_reverbPeriod m49 : 16|16@1+ (1,0) [0|65535] "microseconds" Vector__XXX
 SG_ PARK_sw049_reverbTime m49 : 32|16@1+ (1,0) [0|65535] "microseconds" Vector__XXX
 SG_ PARK_sw049_highAttenTime m49 : 48|1@1+ (1,0) [0|1] "" Vector__XXX
 SG_ PARK_sw049_closeConstEcho m49 : 49|1@1+ (1,0) [0|1] "" Vector__XXX
 SG_ PARK_sw049_lowAttenTime m49 : 50|1@1+ (1,0) [0|1] "" Vector__XXX
 SG_ PARK_sw049_attenTimeJitter m49 : 51|1@1+ (1,0) [0|1] "" Vector__XXX
 SG_ PARK_sw049_reverbFreqJitter m49 : 52|1@1+ (1,0) [0|1] "" Vector__XXX
 SG_ PARK_sw051_sensorTemperature m51 : 16|16@1+ (0.1,-40) [-40|6513.5] "deg" Vector__XXX
 SG_ PARK_sw052_membraneDisconct m52 : 16|1@1+ (1,0) [0|1] "" Vector__XXX
 SG_ PARK_sw052_dampResistorFail m52 : 17|1@1+ (1,0) [0|1] "" Vector__XXX
 SG_ PARK_sw052_resonanceDrift m52 : 18|1@1+ (1,0) [0|1] "" Vector__XXX
 SG_ PARK_sw052_sensorCRC m52 : 19|1@1+ (1,0) [0|1] "" Vector__XXX
 SG_ PARK_sw052_recieveFailure m52 : 20|1@1+ (1,0) [0|1] "" Vector__XXX
 SG_ PARK_sw052_diagnosticTransferErr m52 : 21|1@1+ (1,0) [0|1] "" Vector__XXX
 SG_ PARK_sw053_linError m53 : 16|1@1+ (1,0) [0|1] "" Vector__XXX
 SG_ PARK_sw053_linBusError m53 : 17|1@1+ (1,0) [0|1] "" Vector__XXX
 SG_ PARK_sw053_linFrameCountError m53 : 18|1@1+ (1,0) [0|1] "" Vector__XXX
 SG_ PARK_sw054_reverbPeriod m54 : 16|16@1+ (1,0) [0|65535] "microseconds" Vector__XXX
 SG_ PARK_sw054_reverbTime m54 : 32|16@1+ (1,0) [0|65535] "microseconds" Vector__XXX
 SG_ PARK_sw054_highAttenTime m54 : 48|1@1+ (1,0) [0|1] "" Vector__XXX
 SG_ PARK_sw054_closeConstEcho m54 : 49|1@1+ (1,0) [0|1] "" Vector__XXX
 SG_ PARK_sw054_lowAttenTime m54 : 50|1@1+ (1,0) [0|1] "" Vector__XXX
 SG_ PARK_sw054_attenTimeJitter m54 : 51|1@1+ (1,0) [0|1] "" Vector__XXX
 SG_ PARK_sw054_reverbFreqJitter m54 : 52|1@1+ (1,0) [0|1] "" Vector__XXX
 SG_ PARK_sw056_sensorTemperature m56 : 16|16@1+ (0.1,-40) [-40|6513.5] "deg" Vector__XXX
 SG_ PARK_sw057_membraneDisconct m57 : 16|1@1+ (1,0) [0|1] "" Vector__XXX
 SG_ PARK_sw057_dampResistorFail m57 : 17|1@1+ (1,0) [0|1] "" Vector__XXX
 SG_ PARK_sw057_resonanceDrift m57 : 18|1@1+ (1,0) [0|1] "" Vector__XXX
 SG_ PARK_sw057_sensorCRC m57 : 19|1@1+ (1,0) [0|1] "" Vector__XXX
 SG_ PARK_sw057_recieveFailure m57 : 20|1@1+ (1,0) [0|1] "" Vector__XXX
 SG_ PARK_sw057_diagnosticTransferErr m57 : 21|1@1+ (1,0) [0|1] "" Vector__XXX
 SG_ PARK_sw058_linError m58 : 16|1@1+ (1,0) [0|1] "" Vector__XXX
 SG_ PARK_sw058_linBusError m58 : 17|1@1+ (1,0) [0|1] "" Vector__XXX
 SG_ PARK_sw058_linFrameCountError m58 : 18|1@1+ (1,0) [0|1] "" Vector__XXX
 SG_ PARK_sw059_reverbPeriod m59 : 16|16@1+ (1,0) [0|65535] "microseconds" Vector__XXX
 SG_ PARK_sw059_reverbTime m59 : 32|16@1+ (1,0) [0|65535] "microseconds" Vector__XXX
 SG_ PARK_sw059_highAttenTime m59 : 48|1@1+ (1,0) [0|1] "" Vector__XXX
 SG_ PARK_sw059_closeConstEcho m59 : 49|1@1+ (1,0) [0|1] "" Vector__XXX
 SG_ PARK_sw059_lowAttenTime m59 : 50|1@1+ (1,0) [0|1] "" Vector__XXX
 SG_ PARK_sw059_attenTimeJitter m59 : 51|1@1+ (1,0) [0|1] "" Vector__XXX
 SG_ PARK_sw059_reverbFreqJitter m59 : 52|1@1+ (1,0) [0|1] "" Vector__XXX
 SG_ PARK_sw061_voltage m61 : 16|16@1+ (0.1,0) [0|6553.5] "volts" Vector__XXX
 SG_ PARK_sw063_voltage m63 : 16|16@1+ (0.1,0) [0|6553.5] "volts" Vector__XXX
 SG_ PARK_sw064_faultCode m64 : 16|8@1+ (1,0) [0|255] "" Vector__XXX
 SG_ PARK_sw065_expectedCRC m65 : 16|16@1+ (1,0) [0|65535] "" Vector__XXX
 SG_ PARK_sw065_calculatedCRC m65 : 32|16@1+ (1,0) [0|65535] "" Vector__XXX
 SG_ PARK_sw066_placeHolder m66 : 16|1@1+ (1,0) [0|1] "" Vector__XXX
 SG_ PARK_sw068_placeHolder m68 : 16|1@1+ (1,0) [0|1] "" Vector__XXX
 SG_ PARK_sw069_messageID m69 : 16|16@1+ (1,0) [0|65535] "" Vector__XXX
 SG_ PARK_sw070_messageID m70 : 16|16@1+ (1,0) [0|65535] "" Vector__XXX
 SG_ PARK_sw071_messageID m71 : 16|16@1+ (1,0) [0|65535] "" Vector__XXX
 SG_ PARK_sw072_messageID m72 : 16|16@1+ (1,0) [0|65535] "" Vector__XXX
 SG_ PARK_sw073_messageID m73 : 16|16@1+ (1,0) [0|65535] "" Vector__XXX
 SG_ PARK_sw074_messageID m74 : 16|16@1+ (1,0) [0|65535] "" Vector__XXX
 SG_ PARK_sw075_messageID m75 : 16|16@1+ (1,0) [0|65535] "" Vector__XXX
 SG_ PARK_sw076_messageID m76 : 16|16@1+ (1,0) [0|65535] "" Vector__XXX
 SG_ PARK_sw077_errorExp m77 : 16|8@1+ (1,0) [0|255] "" Vector__XXX
 SG_ PARK_sw077_errorRx m77 : 24|8@1+ (1,0) [0|255] "" Vector__XXX
 SG_ PARK_sw077_messageID m77 : 32|12@1+ (1,0) [0|4095] "" Vector__XXX
 SG_ PARK_sw077_errorType m77 : 44|3@1+ (1,0) [0|7] "" Vector__XXX
 SG_ PARK_sw078_errorExp m78 : 16|8@1+ (1,0) [0|255] "" Vector__XXX
 SG_ PARK_sw078_errorRx m78 : 24|8@1+ (1,0) [0|255] "" Vector__XXX
 SG_ PARK_sw078_messageID m78 : 32|12@1+ (1,0) [0|4095] "" Vector__XXX
 SG_ PARK_sw078_errorType m78 : 44|3@1+ (1,0) [0|7] "" Vector__XXX
 SG_ PARK_sw079_errorExp m79 : 16|8@1+ (1,0) [0|255] "" Vector__XXX
 SG_ PARK_sw079_errorRx m79 : 24|8@1+ (1,0) [0|255] "" Vector__XXX
 SG_ PARK_sw079_messageID m79 : 32|12@1+ (1,0) [0|4095] "" Vector__XXX
 SG_ PARK_sw079_errorType m79 : 44|3@1+ (1,0) [0|7] "" Vector__XXX
 SG_ PARK_sw080_errorExp m80 : 16|8@1+ (1,0) [0|255] "" Vector__XXX
 SG_ PARK_sw080_errorRx m80 : 24|8@1+ (1,0) [0|255] "" Vector__XXX
 SG_ PARK_sw080_messageID m80 : 32|12@1+ (1,0) [0|4095] "" Vector__XXX
 SG_ PARK_sw080_errorType m80 : 44|3@1+ (1,0) [0|7] "" Vector__XXX
 SG_ PARK_sw081_errorExp m81 : 16|8@1+ (1,0) [0|255] "" Vector__XXX
 SG_ PARK_sw081_errorRx m81 : 24|8@1+ (1,0) [0|255] "" Vector__XXX
 SG_ PARK_sw081_messageID m81 : 32|12@1+ (1,0) [0|4095] "" Vector__XXX
 SG_ PARK_sw081_errorType m81 : 44|3@1+ (1,0) [0|7] "" Vector__XXX
 SG_ PARK_sw082_errorExp m82 : 16|8@1+ (1,0) [0|255] "" Vector__XXX
 SG_ PARK_sw082_errorRx m82 : 24|8@1+ (1,0) [0|255] "" Vector__XXX
 SG_ PARK_sw082_messageID m82 : 32|12@1+ (1,0) [0|4095] "" Vector__XXX
 SG_ PARK_sw082_errorType m82 : 44|3@1+ (1,0) [0|7] "" Vector__XXX
 SG_ PARK_sw083_errorExp m83 : 16|8@1+ (1,0) [0|255] "" Vector__XXX
 SG_ PARK_sw083_errorRx m83 : 24|8@1+ (1,0) [0|255] "" Vector__XXX
 SG_ PARK_sw083_messageID m83 : 32|12@1+ (1,0) [0|4095] "" Vector__XXX
 SG_ PARK_sw083_errorType m83 : 44|3@1+ (1,0) [0|7] "" Vector__XXX
 SG_ PARK_sw084_errorExp m84 : 16|8@1+ (1,0) [0|255] "" Vector__XXX
 SG_ PARK_sw084_errorRx m84 : 24|8@1+ (1,0) [0|255] "" Vector__XXX
 SG_ PARK_sw084_messageID m84 : 32|12@1+ (1,0) [0|4095] "" Vector__XXX
 SG_ PARK_sw084_errorType m84 : 44|3@1+ (1,0) [0|7] "" Vector__XXX
 SG_ PARK_sw086_writeRetryCounter m86 : 16|8@1+ (1,0) [0|255] "" Vector__XXX
 SG_ PARK_sw086_readRetryCounter m86 : 24|8@1+ (1,0) [0|255] "" Vector__XXX
 SG_ PARK_sw086_currentErrorCode m86 : 32|8@1+ (1,0) [0|255] "" Vector__XXX
 SG_ PARK_sw087_s1_sensorType m87 : 16|2@1+ (1,0) [0|2] "" Vector__XXX
 SG_ PARK_sw087_s2_sensorType m87 : 18|2@1+ (1,0) [0|2] "" Vector__XXX
 SG_ PARK_sw087_s3_sensorType m87 : 20|2@1+ (1,0) [0|2] "" Vector__XXX
 SG_ PARK_sw087_s4_sensorType m87 : 22|2@1+ (1,0) [0|2] "" Vector__XXX
 SG_ PARK_sw087_s5_sensorType m87 : 24|2@1+ (1,0) [0|2] "" Vector__XXX
 SG_ PARK_sw087_s6_sensorType m87 : 26|2@1+ (1,0) [0|2] "" Vector__XXX
 SG_ PARK_sw087_s7_sensorType m87 : 28|2@1+ (1,0) [0|2] "" Vector__XXX
 SG_ PARK_sw087_s8_sensorType m87 : 30|2@1+ (1,0) [0|2] "" Vector__XXX
 SG_ PARK_sw087_s9_sensorType m87 : 32|2@1+ (1,0) [0|2] "" Vector__XXX
 SG_ PARK_sw087_s10_sensorType m87 : 34|2@1+ (1,0) [0|2] "" Vector__XXX
 SG_ PARK_sw087_s11_sensorType m87 : 36|2@1+ (1,0) [0|2] "" Vector__XXX
 SG_ PARK_sw087_s12_sensorType m87 : 38|2@1+ (1,0) [0|2] "" Vector__XXX

BO_ 806 PARK_info: 8 PARK
 SG_ PARK_infoIndex M : 0|8@1+ (1,0) [0|255] "" Vector__XXX
 SG_ PARK_infoBuildType m10 : 8|8@1+ (1,0) [0|255] "" Vector__XXX
 SG_ PARK_infoComponentID m10 : 48|16@1+ (1,0) [0|65535] "" Vector__XXX
 SG_ PARK_infoPcbaID m11 : 16|8@1+ (1,0) [0|255] "" Vector__XXX
 SG_ PARK_infoAssemblyID m11 : 24|8@1+ (1,0) [0|255] "" Vector__XXX
 SG_ PARK_infoUsageID m11 : 32|16@1+ (1,0) [0|65535] "" Vector__XXX
 SG_ PARK_infoApplicationCRC m13 : 32|32@1+ (1,0) [0|4294967295] "" Vector__XXX
 SG_ PARK_infoBootUdsProtoVersion m20 : 8|8@1+ (1,0) [0|255] "" Vector__XXX
 SG_ PARK_infoBootloaderCRC m20 : 32|32@1+ (1,0) [0|4294967295] "" Vector__XXX

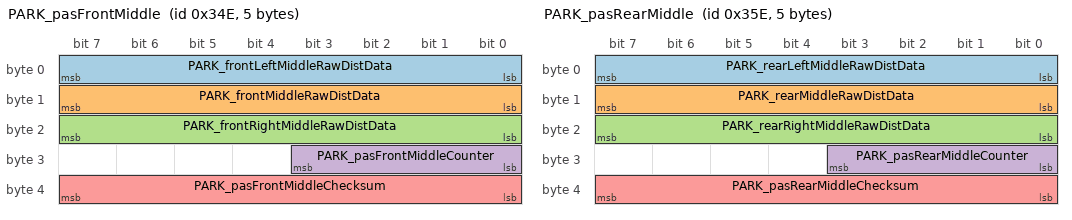
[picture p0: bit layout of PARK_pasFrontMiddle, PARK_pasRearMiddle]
BO_ 846 PARK_pasFrontMiddle: 5 PARK
 SG_ PARK_frontLeftMiddleRawDistData : 0|8@1+ (1,0) [0|254] "cm" Vector__XXX
 SG_ PARK_frontMiddleRawDistData : 8|8@1+ (1,0) [0|254] "cm" Vector__XXX
 SG_ PARK_frontRightMiddleRawDistData : 16|8@1+ (1,0) [0|254] "cm" Vector__XXX
 SG_ PARK_pasFrontMiddleCounter : 24|4@1+ (1,0) [0|15] "" Vector__XXX
 SG_ PARK_pasFrontMiddleChecksum : 32|8@1+ (1,0) [0|255] "" Vector__XXX

BO_ 862 PARK_pasRearMiddle: 5 PARK
 SG_ PARK_rearLeftMiddleRawDistData : 0|8@1+ (1,0) [0|254] "cm" Vector__XXX
 SG_ PARK_rearMiddleRawDistData : 8|8@1+ (1,0) [0|254] "cm" Vector__XXX
 SG_ PARK_rearRightMiddleRawDistData : 16|8@1+ (1,0) [0|254] "cm" Vector__XXX
 SG_ PARK_pasRearMiddleCounter : 24|4@1+ (1,0) [0|15] "" Vector__XXX
 SG_ PARK_pasRearMiddleChecksum : 32|8@1+ (1,0) [0|255] "" Vector__XXX

BO_TX_BU_ 1470 : IDB;
BO_TX_BU_ 983 : IDB;
BO_TX_BU_ 828 : IDB;
BO_TX_BU_ 1012 : LS;
BO_TX_BU_ 1429 : OCS1P;
BO_TX_BU_ 767 : OCS1P;
BO_TX_BU_ 766 : OCS1P;
BO_TX_BU_ 771 : OCS1P;
BO_TX_BU_ 1486 : PARK;
BO_TX_BU_ 806 : PARK;
BO_TX_BU_ 846 : PARK;
BO_TX_BU_ 862 : PARK;
CM_ BO_ 1470 "IDB ECU message: alert log";
CM_ SG_ 1470 IDB_alertID "IDB ECU: alert ID";
CM_ SG_ 1470 IDB_alertState "IDB ECU: alert state";
CM_ SG_ 1470 IDB_a014_wheelSpeedSensorFreq "IDB ECU: a014 wheel speed sensor freq";
CM_ SG_ 1470 IDB_a014_wheelSpeedSensorPhase "IDB ECU: a014 wheel speed sensor phase";
CM_ SG_ 1470 IDB_a014_wheelSpeedSensorMisinst "IDB ECU: a014 wheel speed sensor misinstallation";
CM_ SG_ 1470 IDB_a014_wheelSpeedSensorWrongEx "IDB ECU: a014 wheel speed sensor wrong exciter";
CM_ SG_ 1470 IDB_a014_wheelSpeedSensorSpeedJu "IDB ECU: a014 wheel speed sensor speed jump minus";
CM_ SG_ 1470 IDB_a014_wheelSpeedSensorSp_0001 "IDB ECU: a014 wheel speed sensor speed jump plus";
CM_ SG_ 1470 IDB_a014_wheelSpeedSensorAirGap "IDB ECU: a014 wheel speed sensor air gap";
CM_ SG_ 1470 IDB_a014_wheelSpeedSensorBIST "IDB ECU: a014 wheel speed sensor BIST";
CM_ SG_ 1470 IDB_a014_wheelSpeedSensorLeakage "IDB ECU: a014 wheel speed sensor leakage cur";
CM_ SG_ 1470 IDB_a014_wheelSpeedSensorOverTem "IDB ECU: a014 wheel speed sensor over temp";
CM_ SG_ 1470 IDB_a014_wheelSpeedSensorSh_0001 "IDB ECU: a014 wheel speed sensor short to gnd";
CM_ SG_ 1470 IDB_a014_wheelSpeedSensorShortTo "IDB ECU: a014 wheel speed sensor short to bat";
CM_ SG_ 1470 IDB_a014_wheelSpeedSensorOpen "IDB ECU: a014 wheel speed sensor open";
CM_ SG_ 1470 IDB_a015_wheelSpeedSensorFreq "IDB ECU: a015 wheel speed sensor freq";
CM_ SG_ 1470 IDB_a015_wheelSpeedSensorPhase "IDB ECU: a015 wheel speed sensor phase";
CM_ SG_ 1470 IDB_a015_wheelSpeedSensorMisinst "IDB ECU: a015 wheel speed sensor misinstallation";
CM_ SG_ 1470 IDB_a015_wheelSpeedSensorWrongEx "IDB ECU: a015 wheel speed sensor wrong exciter";
CM_ SG_ 1470 IDB_a015_wheelSpeedSensorSpeedJu "IDB ECU: a015 wheel speed sensor speed jump minus";
CM_ SG_ 1470 IDB_a015_wheelSpeedSensorSp_0001 "IDB ECU: a015 wheel speed sensor speed jump plus";
CM_ SG_ 1470 IDB_a015_wheelSpeedSensorAirGap "IDB ECU: a015 wheel speed sensor air gap";
CM_ SG_ 1470 IDB_a015_wheelSpeedSensorBIST "IDB ECU: a015 wheel speed sensor BIST";
CM_ SG_ 1470 IDB_a015_wheelSpeedSensorLeakage "IDB ECU: a015 wheel speed sensor leakage cur";
CM_ SG_ 1470 IDB_a015_wheelSpeedSensorOverTem "IDB ECU: a015 wheel speed sensor over temp";
CM_ SG_ 1470 IDB_a015_wheelSpeedSensorSh_0001 "IDB ECU: a015 wheel speed sensor short to gnd";
CM_ SG_ 1470 IDB_a015_wheelSpeedSensorShortTo "IDB ECU: a015 wheel speed sensor short to bat";
CM_ SG_ 1470 IDB_a015_wheelSpeedSensorOpen "IDB ECU: a015 wheel speed sensor open";
CM_ SG_ 1470 IDB_a016_wheelSpeedSensorFreq "IDB ECU: a016 wheel speed sensor freq";
CM_ SG_ 1470 IDB_a016_wheelSpeedSensorPhase "IDB ECU: a016 wheel speed sensor phase";
CM_ SG_ 1470 IDB_a016_wheelSpeedSensorMisinst "IDB ECU: a016 wheel speed sensor misinstallation";
CM_ SG_ 1470 IDB_a016_wheelSpeedSensorWrongEx "IDB ECU: a016 wheel speed sensor wrong exciter";
CM_ SG_ 1470 IDB_a016_wheelSpeedSensorSpeedJu "IDB ECU: a016 wheel speed sensor speed jump minus";
CM_ SG_ 1470 IDB_a016_wheelSpeedSensorSp_0001 "IDB ECU: a016 wheel speed sensor speed jump plus";
CM_ SG_ 1470 IDB_a016_wheelSpeedSensorAirGap "IDB ECU: a016 wheel speed sensor air gap";
CM_ SG_ 1470 IDB_a016_wheelSpeedSensorBIST "IDB ECU: a016 wheel speed sensor BIST";
CM_ SG_ 1470 IDB_a016_wheelSpeedSensorLeakage "IDB ECU: a016 wheel speed sensor leakage cur";
CM_ SG_ 1470 IDB_a016_wheelSpeedSensorOverTem "IDB ECU: a016 wheel speed sensor over temp";
CM_ SG_ 1470 IDB_a016_wheelSpeedSensorSh_0001 "IDB ECU: a016 wheel speed sensor short to gnd";
CM_ SG_ 1470 IDB_a016_wheelSpeedSensorShortTo "IDB ECU: a016 wheel speed sensor short to bat";
CM_ SG_ 1470 IDB_a016_wheelSpeedSensorOpen "IDB ECU: a016 wheel speed sensor open";
CM_ SG_ 1470 IDB_a017_wheelSpeedSensorFreq "IDB ECU: a017 wheel speed sensor freq";
CM_ SG_ 1470 IDB_a017_wheelSpeedSensorPhase "IDB ECU: a017 wheel speed sensor phase";
CM_ SG_ 1470 IDB_a017_wheelSpeedSensorMisinst "IDB ECU: a017 wheel speed sensor misinstallation";
CM_ SG_ 1470 IDB_a017_wheelSpeedSensorWrongEx "IDB ECU: a017 wheel speed sensor wrong exciter";
CM_ SG_ 1470 IDB_a017_wheelSpeedSensorSpeedJu "IDB ECU: a017 wheel speed sensor speed jump minus";
CM_ SG_ 1470 IDB_a017_wheelSpeedSensorSp_0001 "IDB ECU: a017 wheel speed sensor speed jump plus";
CM_ SG_ 1470 IDB_a017_wheelSpeedSensorAirGap "IDB ECU: a017 wheel speed sensor air gap";
CM_ SG_ 1470 IDB_a017_wheelSpeedSensorBIST "IDB ECU: a017 wheel speed sensor BIST";
CM_ SG_ 1470 IDB_a017_wheelSpeedSensorLeakage "IDB ECU: a017 wheel speed sensor leakage cur";
CM_ SG_ 1470 IDB_a017_wheelSpeedSensorOverTem "IDB ECU: a017 wheel speed sensor over temp";
CM_ SG_ 1470 IDB_a017_wheelSpeedSensorSh_0001 "IDB ECU: a017 wheel speed sensor short to gnd";
CM_ SG_ 1470 IDB_a017_wheelSpeedSensorShortTo "IDB ECU: a017 wheel speed sensor short to bat";
CM_ SG_ 1470 IDB_a017_wheelSpeedSensorOpen "IDB ECU: a017 wheel speed sensor open";
CM_ SG_ 1470 IDB_a020_canSignalValidity "IDB ECU: a020 can signal validity";
CM_ SG_ 1470 IDB_a020_signalValueCrosscheck "IDB ECU: a020 signal value crosscheck";
CM_ SG_ 1470 IDB_a030_primaryExternalCircuitL "IDB ECU: a030 primary external circuit leakage";
CM_ SG_ 1470 IDB_a030_secondaryExternalCircui "IDB ECU: a030 secondary external circuit leakage";
CM_ SG_ 1470 IDB_a030_primaryChamberInternalL "IDB ECU: a030 primary chamber internal leakage";
CM_ SG_ 1470 IDB_a030_syncModeInternalLeakage "IDB ECU: a030 sync mode internal leakage";
CM_ SG_ 1470 IDB_a030_secondaryChamberInterna "IDB ECU: a030 secondary chamber internal leakage";
CM_ SG_ 1470 IDB_a030_masterCylinderInternalL "IDB ECU: a030 master cylinder internal leakage";
CM_ SG_ 1470 IDB_a060_validityOnChassisBus "IDB ECU: a060 validity on chassis bus";
CM_ SG_ 1470 IDB_a060_validityOnPartyBus "IDB ECU: a060 validity on party bus";
CM_ SG_ 1470 IDB_a061_validityOnChassisBus "IDB ECU: a061 validity on chassis bus";
CM_ SG_ 1470 IDB_a061_validityOnPartyBus "IDB ECU: a061 validity on party bus";
CM_ SG_ 1470 IDB_a063_validityOnChassisBus "IDB ECU: a063 validity on chassis bus";
CM_ SG_ 1470 IDB_a063_validityOnPartyBus "IDB ECU: a063 validity on party bus";
CM_ SG_ 1470 IDB_a064_validityOnChassisBus "IDB ECU: a064 validity on chassis bus";
CM_ SG_ 1470 IDB_a064_validityOnPartyBus "IDB ECU: a064 validity on party bus";
CM_ SG_ 1470 IDB_a065_validityOnChassisBus "IDB ECU: a065 validity on chassis bus";
CM_ SG_ 1470 IDB_a065_validityOnPartyBus "IDB ECU: a065 validity on party bus";
CM_ SG_ 1470 IDB_a106_qualifierValidity "IDB ECU: a106 qualifier validity";
CM_ SG_ 1470 IDB_a106_signalNotAvailable "IDB ECU: a106 signal not available";
CM_ SG_ 1470 IDB_a107_qualifierValidity "IDB ECU: a107 qualifier validity";
CM_ SG_ 1470 IDB_a107_signalNotAvailable "IDB ECU: a107 signal not available";
CM_ SG_ 1470 IDB_a112_qualifierValidity "IDB ECU: a112 qualifier validity";
CM_ SG_ 1470 IDB_a112_signalNotAvailable "IDB ECU: a112 signal not available";
CM_ SG_ 1470 IDB_a113_qualifierValidity "IDB ECU: a113 qualifier validity";
CM_ SG_ 1470 IDB_a113_signalNotAvailable "IDB ECU: a113 signal not available";
CM_ SG_ 1470 IDB_a114_qualifierValidity "IDB ECU: a114 qualifier validity";
CM_ SG_ 1470 IDB_a114_signalNotAvailable "IDB ECU: a114 signal not available";
CM_ SG_ 1470 IDB_a126_PMebrCmdStateValidity "IDB ECU: a126 p mebr cmd state validity";
CM_ SG_ 1470 IDB_a126_PMstate2Validity "IDB ECU: a126 p mstate2 validity";
CM_ SG_ 1470 IDB_a126_PMstate2Missing "IDB ECU: a126 p mstate2 missing";
CM_ SG_ 1470 IDB_a126_DIchassisControlValidit "IDB ECU: a126 d ichassis control validity";
CM_ SG_ 1470 IDB_a126_DIchassisControlMissing "IDB ECU: a126 d ichassis control missing";
CM_ SG_ 1470 IDB_a126_DIrequestActiveValidity "IDB ECU: a126 d irequest active validity";
CM_ SG_ 1470 IDB_a129_validityOnChassisBus "IDB ECU: a129 validity on chassis bus";
CM_ SG_ 1470 IDB_a129_validityOnPartyBus "IDB ECU: a129 validity on party bus";
CM_ SG_ 1470 IDB_a130_PMbrakePedalCmdQFValidi "IDB ECU: a130 p mbrake pedal cmd QF validity";
CM_ SG_ 1470 IDB_a130_PMstate2Validity "IDB ECU: a130 p mstate2 validity";
CM_ SG_ 1470 IDB_a130_PMstate2Missing "IDB ECU: a130 p mstate2 missing";
CM_ SG_ 1470 IDB_a130_DIbrakeCommandValidity "IDB ECU: a130 d ibrake command validity";
CM_ SG_ 1470 IDB_a130_DIbrakeCommandMissing "IDB ECU: a130 d ibrake command missing";
CM_ SG_ 1470 IDB_a130_DIbrakeTorqueCommandFul "IDB ECU: a130 d ibrake torque command full SNA";
CM_ SG_ 1470 IDB_a130_DIbrakeTorqueComma_0001 "IDB ECU: a130 d ibrake torque command full too low";
CM_ SG_ 1470 IDB_a132_validityOnChassisBus "IDB ECU: a132 validity on chassis bus";
CM_ SG_ 1470 IDB_a132_validityOnPartyBus "IDB ECU: a132 validity on party bus";
CM_ BO_ 983 "IDB ECU message: alert matrix";
CM_ SG_ 983 IDB_matrixIndex "IDB ECU: matrix index";
CM_ SG_ 983 IDB_a001_mcuGenericFault "IDB ECU: a001 mcu generic fault";
CM_ SG_ 983 IDB_a002_supplyOvervoltage "IDB ECU: a002 supply overvoltage";
CM_ SG_ 983 IDB_a003_supplyHardOvervoltage "IDB ECU: a003 supply hard overvoltage";
CM_ SG_ 983 IDB_a004_supplyUndervoltage "IDB ECU: a004 supply undervoltage";
CM_ SG_ 983 IDB_a005_supplyMidUndervoltage "IDB ECU: a005 supply mid undervoltage";
CM_ SG_ 983 IDB_a006_supplyHardUndervoltage "IDB ECU: a006 supply hard undervoltage";
CM_ SG_ 983 IDB_a007_wakeLineOpen "IDB ECU: a007 wake line open";
CM_ SG_ 983 IDB_a008_motorPowerOpen "IDB ECU: a008 motor power open";
CM_ SG_ 983 IDB_a009_asicBoostFault "IDB ECU: a009 asic boost fault";
CM_ SG_ 983 IDB_a010_asicGenericFault "IDB ECU: a010 asic generic fault";
CM_ SG_ 983 IDB_a011_solenoidValveFault "IDB ECU: a011 solenoid valve fault";
CM_ SG_ 983 IDB_a012_motorGenericFault "IDB ECU: a012 motor generic fault";
CM_ SG_ 983 IDB_a013_motorPosSensorFault "IDB ECU: a013 motor pos sensor fault";
CM_ SG_ 983 IDB_a014_FrLWSSFault "IDB ECU: a014 fr LWSS fault";
CM_ SG_ 983 IDB_a015_FrRWSSFault "IDB ECU: a015 fr RWSS fault";
CM_ SG_ 983 IDB_a016_ReLWSSFault "IDB ECU: a016 re LWSS fault";
CM_ SG_ 983 IDB_a017_ReRWSSFault "IDB ECU: a017 re RWSS fault";
CM_ SG_ 983 IDB_a018_WSSGenericFault "IDB ECU: a018 WSS generic fault";
CM_ SG_ 983 IDB_a019_pedalSensorFault "IDB ECU: a019 pedal sensor fault";
CM_ SG_ 983 IDB_a020_RCUpedalTravelMismatch "IDB ECU: a020 RC upedal travel mismatch";
CM_ SG_ 983 IDB_a021_pedalSensorNotCal "IDB ECU: a021 pedal sensor not cal";
CM_ SG_ 983 IDB_a022_brakeFluidLow "IDB ECU: a022 brake fluid low";
CM_ SG_ 983 IDB_a023_steeringImplausible "IDB ECU: a023 steering implausible";
CM_ SG_ 983 IDB_a024_yawImplausible "IDB ECU: a024 yaw implausible";
CM_ SG_ 983 IDB_a025_ayImplausible "IDB ECU: a025 ay implausible";
CM_ SG_ 983 IDB_a026_axImplausible "IDB ECU: a026 ax implausible";
CM_ SG_ 983 IDB_a027_circuitPresSensorFault "IDB ECU: a027 circuit pres sensor fault";
CM_ SG_ 983 IDB_a028_simPresSensorFault "IDB ECU: a028 sim pres sensor fault";
CM_ SG_ 983 IDB_a029_pressureSensNotCal "IDB ECU: a029 pressure sens not cal";
CM_ SG_ 983 IDB_a030_fluidLeakDetected "IDB ECU: a030 fluid leak detected";
CM_ SG_ 983 IDB_a031_solenoidValveStuck "IDB ECU: a031 solenoid valve stuck";
CM_ SG_ 983 IDB_a032_motorSoftOverheat "IDB ECU: a032 motor soft overheat";
CM_ SG_ 983 IDB_a033_motorHardOverheat "IDB ECU: a033 motor hard overheat";
CM_ SG_ 983 IDB_a034_motorPositionSetFault "IDB ECU: a034 motor position set fault";
CM_ SG_ 983 IDB_a035_motorStuck "IDB ECU: a035 motor stuck";
CM_ SG_ 983 IDB_a036_partyBusOff "IDB ECU: a036 party bus off";
CM_ SG_ 983 IDB_a037_chassisBusOff "IDB ECU: a037 chassis bus off";
CM_ SG_ 983 IDB_a038_motorInitFault "IDB ECU: a038 motor init fault";
CM_ SG_ 983 IDB_a039_absActive "IDB ECU: a039 abs active";
CM_ SG_ 983 IDB_a040_ebdActive "IDB ECU: a040 ebd active";
CM_ SG_ 983 IDB_a041_vdcActive "IDB ECU: a041 vdc active";
CM_ SG_ 983 IDB_a042_btcActive "IDB ECU: a042 btc active";
CM_ SG_ 983 IDB_a043_cbcActive "IDB ECU: a043 cbc active";
CM_ SG_ 983 IDB_a044_standstillSkidDetected "IDB ECU: a044 standstill skid detected";
CM_ SG_ 983 IDB_a045_panicBrakeAssistActive "IDB ECU: a045 panic brake assist active";
CM_ SG_ 983 IDB_a046_fadeCompensationActive "IDB ECU: a046 fade compensation active";
CM_ SG_ 983 IDB_a047_brakeDiscWipeActive "IDB ECU: a047 brake disc wipe active";
CM_ SG_ 983 IDB_a048_scmActive "IDB ECU: a048 scm active";
CM_ SG_ 983 IDB_a049_cdpActive "IDB ECU: a049 cdp active";
CM_ SG_ 983 IDB_a050_absFaulted "IDB ECU: a050 abs faulted";
CM_ SG_ 983 IDB_a051_ebdFaulted "IDB ECU: a051 ebd faulted";
CM_ SG_ 983 IDB_a052_vdcFaulted "IDB ECU: a052 vdc faulted";
CM_ SG_ 983 IDB_a053_DItorquePathFaulted "IDB ECU: a053 d itorque path faulted";
CM_ SG_ 983 IDB_a054_skidDetectionFaulted "IDB ECU: a054 skid detection faulted";
CM_ SG_ 983 IDB_a055_panicBrakeAssistFaulted "IDB ECU: a055 panic brake assist faulted";
CM_ SG_ 983 IDB_a056_fadeCompensationFaulted "IDB ECU: a056 fade compensation faulted";
CM_ SG_ 983 IDB_a057_bdwRequestInvalid "IDB ECU: a057 bdw request invalid";
CM_ SG_ 983 IDB_a058_scmFaulted "IDB ECU: a058 scm faulted";
CM_ SG_ 983 IDB_a059_cdpFaulted "IDB ECU: a059 cdp faulted";
CM_ SG_ 983 IDB_a060_RCUstatusDLC "IDB ECU: a060 RC ustatus DLC";
CM_ SG_ 983 IDB_a061_RCUstatusChecksum "IDB ECU: a061 RC ustatus checksum";
CM_ SG_ 983 IDB_a062_RCUstatusCounter "IDB ECU: a062 RC ustatus counter";
CM_ SG_ 983 IDB_a063_RCUactuationDLC "IDB ECU: a063 RC uactuation DLC";
CM_ SG_ 983 IDB_a064_RCUactuationChecksum "IDB ECU: a064 RC uactuation checksum";
CM_ SG_ 983 IDB_a065_RCUactuationCounter "IDB ECU: a065 RC uactuation counter";
CM_ SG_ 983 IDB_a066_DIFtorqueDLC "IDB ECU: a066 DI ftorque DLC";
CM_ SG_ 983 IDB_a067_DIFtorqueChecksum "IDB ECU: a067 DI ftorque checksum";
CM_ SG_ 983 IDB_a068_DIFtorqueCounter "IDB ECU: a068 DI ftorque counter";
CM_ SG_ 983 IDB_a069_DIchassisControlDLC "IDB ECU: a069 d ichassis control DLC";
CM_ SG_ 983 IDB_a070_DIchassisControlChecksu "IDB ECU: a070 d ichassis control checksum";
CM_ SG_ 983 IDB_a071_DIchassisControlCounter "IDB ECU: a071 d ichassis control counter";
CM_ SG_ 983 IDB_a072_DIsystemStatusDLC "IDB ECU: a072 d isystem status DLC";
CM_ SG_ 983 IDB_a073_DIsystemStatusChecksum "IDB ECU: a073 d isystem status checksum";
CM_ SG_ 983 IDB_a074_DIsystemStatusCounter "IDB ECU: a074 d isystem status counter";
CM_ SG_ 983 IDB_a075_DIRtorqueDLC "IDB ECU: a075 DI rtorque DLC";
CM_ SG_ 983 IDB_a076_DIRtorqueChecksum "IDB ECU: a076 DI rtorque checksum";
CM_ SG_ 983 IDB_a077_DIRtorqueCounter "IDB ECU: a077 DI rtorque counter";
CM_ SG_ 983 IDB_a078_DIvdcLeftDLC "IDB ECU: a078 d ivdc left DLC";
CM_ SG_ 983 IDB_a079_DIvdcLeftChecksum "IDB ECU: a079 d ivdc left checksum";
CM_ SG_ 983 IDB_a080_DIvdcLeftCounter "IDB ECU: a080 d ivdc left counter";
CM_ SG_ 983 IDB_a081_DIvdcRightDLC "IDB ECU: a081 d ivdc right DLC";
CM_ SG_ 983 IDB_a082_DIvdcRightChecksum "IDB ECU: a082 d ivdc right checksum";
CM_ SG_ 983 IDB_a083_DIvdcRightCounter "IDB ECU: a083 d ivdc right counter";
CM_ SG_ 983 IDB_a084_EPAS3PsysStatusDLC "IDB ECU: a084 EPAS3 psys status DLC";
CM_ SG_ 983 IDB_a085_EPAS3PsysStatusChecksum "IDB ECU: a085 EPAS3 psys status checksum";
CM_ SG_ 983 IDB_a086_EPAS3PsysStatusCounter "IDB ECU: a086 EPAS3 psys status counter";
CM_ SG_ 983 IDB_a087_PMstate2DLC "IDB ECU: a087 p mstate2 DLC";
CM_ SG_ 983 IDB_a088_PMstate2Checksum "IDB ECU: a088 p mstate2 checksum";
CM_ SG_ 983 IDB_a089_PMstate2Counter "IDB ECU: a089 p mstate2 counter";
CM_ SG_ 983 IDB_a090_RCMinertial1DLC "IDB ECU: a090 RC minertial1 DLC";
CM_ SG_ 983 IDB_a091_RCMinertial1Checksum "IDB ECU: a091 RC minertial1 checksum";
CM_ SG_ 983 IDB_a092_RCMinertial1Counter "IDB ECU: a092 RC minertial1 counter";
CM_ SG_ 983 IDB_a093_RCMinertial2DLC "IDB ECU: a093 RC minertial2 DLC";
CM_ SG_ 983 IDB_a094_RCMinertial2Checksum "IDB ECU: a094 RC minertial2 checksum";
CM_ SG_ 983 IDB_a095_RCMinertial2Counter "IDB ECU: a095 RC minertial2 counter";
CM_ SG_ 983 IDB_a096_VCFRONTLVPowerStateDLC "IDB ECU: a096 VCFRONTLV power state DLC";
CM_ SG_ 983 IDB_a097_VCFRONTLVPwrStChecksum "IDB ECU: a097 VCFRONTLV pwr st checksum";
CM_ SG_ 983 IDB_a098_VCFRONTLVPwrStCounter "IDB ECU: a098 VCFRONTLV pwr st counter";
CM_ SG_ 983 IDB_a099_RCMcollisionDLC "IDB ECU: a099 RC mcollision DLC";
CM_ SG_ 983 IDB_a100_RCMcollisionChecksum "IDB ECU: a100 RC mcollision checksum";
CM_ SG_ 983 IDB_a101_RCMcollisionCounter "IDB ECU: a101 RC mcollision counter";
CM_ SG_ 983 IDB_a102_bdwRequestActiveInvalid "IDB ECU: a102 bdw request active invalid";
CM_ SG_ 983 IDB_a103_DIfullTorquePathFaulted "IDB ECU: a103 d ifull torque path faulted";
CM_ SG_ 983 IDB_a104_DIaccelPosInvalid "IDB ECU: a104 d iaccel pos invalid";
CM_ SG_ 983 IDB_a105_DIgearInvalid "IDB ECU: a105 d igear invalid";
CM_ SG_ 983 IDB_a106_DIFtorqueInvalid "IDB ECU: a106 DI ftorque invalid";
CM_ SG_ 983 IDB_a107_DIRtorqueInvalid "IDB ECU: a107 DI rtorque invalid";
CM_ SG_ 983 IDB_a108_EPBstatusDLC "IDB ECU: a108 EP bstatus DLC";
CM_ SG_ 983 IDB_a109_BDWsignalInvalid "IDB ECU: a109 BD wsignal invalid";
CM_ SG_ 983 IDB_a110_EPBstatusCounter "IDB ECU: a110 EP bstatus counter";
CM_ SG_ 983 IDB_a111_EPBstatusChecksum "IDB ECU: a111 EP bstatus checksum";
CM_ SG_ 983 IDB_a112_yawRateInvalid "IDB ECU: a112 yaw rate invalid";
CM_ SG_ 983 IDB_a113_latAccelInvalid "IDB ECU: a113 lat accel invalid";
CM_ SG_ 983 IDB_a114_longAccelInvalid "IDB ECU: a114 long accel invalid";
CM_ SG_ 983 IDB_a115_VCFRONTespLvStInvalid "IDB ECU: a115 VCFRON tesp lv st invalid";
CM_ SG_ 983 IDB_a116_VCFRONTsensorsDLC "IDB ECU: a116 VCFRON tsensors DLC";
CM_ SG_ 983 IDB_a117_VCLEFTepbmStatusDLC "IDB ECU: a117 VCLEF tepbm status DLC";
CM_ SG_ 983 IDB_a118_VCLEFTepbmStatusCounter "IDB ECU: a118 VCLEF tepbm status counter";
CM_ SG_ 983 IDB_a119_VCLEFTepbmStatusChecksu "IDB ECU: a119 VCLEF tepbm status checksum";
CM_ SG_ 983 IDB_a120_EPAS3Pinvalid "IDB ECU: a120 EPAS3 pinvalid";
CM_ SG_ 983 IDB_a121_dynoModeActive "IDB ECU: a121 dyno mode active";
CM_ SG_ 983 IDB_a122_DIFtorqueCommandInvalid "IDB ECU: a122 DI ftorque command invalid";
CM_ SG_ 983 IDB_a123_DIRtorqueCommandInvalid "IDB ECU: a123 DI rtorque command invalid";
CM_ SG_ 983 IDB_a124_VCFRONTtempInvalid "IDB ECU: a124 VCFRON ttemp invalid";
CM_ SG_ 983 IDB_a125_PMvdcCmdStateInvalid "IDB ECU: a125 p mvdc cmd state invalid";
CM_ SG_ 983 IDB_a126_DItorqueRequestInvalid "IDB ECU: a126 d itorque request invalid";
CM_ SG_ 983 IDB_a127_brakeFluidLevelInvalid "IDB ECU: a127 brake fluid level invalid";
CM_ SG_ 983 IDB_a128_largeAirVolume "IDB ECU: a128 large air volume";
CM_ SG_ 983 IDB_a129_RCUinputRodStrokeInvali "IDB ECU: a129 RC uinput rod stroke invalid";
CM_ SG_ 983 IDB_a130_DIfullTorqueRequestInva "IDB ECU: a130 d ifull torque request invalid";
CM_ SG_ 983 IDB_a131_cbcFaulted "IDB ECU: a131 cbc faulted";
CM_ SG_ 983 IDB_a132_RCUinputRodStrokeQFInva "IDB ECU: a132 RC uinput rod stroke QF invalid";
CM_ SG_ 983 IDB_a133_DIbrakeCommandDLC "IDB ECU: a133 d ibrake command DLC";
CM_ SG_ 983 IDB_a134_DIbrakeCommandCounter "IDB ECU: a134 d ibrake command counter";
CM_ SG_ 983 IDB_a135_DIbrakeCommandChecksum "IDB ECU: a135 d ibrake command checksum";
CM_ SG_ 983 IDB_a136_RCUptsCalMissing "IDB ECU: a136 RC upts cal missing";
CM_ SG_ 983 IDB_a137_VCLEFTcdpRequestInvalid "IDB ECU: a137 VCLEF tcdp request invalid";
CM_ SG_ 983 IDB_a138_DIbrakeTorqueCommandAnd "IDB ECU: a138 d ibrake torque command and flag mismatch";
CM_ SG_ 983 IDB_a139_DIbrakeTorqueCommandFul "IDB ECU: a139 d ibrake torque command full SNA";
CM_ SG_ 983 IDB_a140_PMbrakePedalCmdQFInvali "IDB ECU: a140 p mbrake pedal cmd QF invalid";
CM_ SG_ 983 IDB_a141_DIbrakeTorqueCommandFul "IDB ECU: a141 d ibrake torque command full too low";
CM_ SG_ 983 IDB_a142_PMebrCmdStateInvalid "IDB ECU: a142 p mebr cmd state invalid";
CM_ SG_ 983 IDB_a143_factoryModeActive "IDB ECU: a143 factory mode active";
CM_ SG_ 983 IDB_a144_hydraulicPushthroughAct "IDB ECU: a144 hydraulic pushthrough active";
CM_ SG_ 983 IDB_a145_DASredundantBrakingCont "IDB ECU: a145 DA sredundant braking control DLC";
CM_ SG_ 983 IDB_a146_DASredundantBrakingCont "IDB ECU: a146 DA sredundant braking control counter";
CM_ SG_ 983 IDB_a147_DASredundantBrakingCont "IDB ECU: a147 DA sredundant braking control checksum";
CM_ SG_ 983 IDB_a148_DASbrakeTorqueCommandIn "IDB ECU: a148 DA sbrake torque command invalid";
CM_ SG_ 983 IDB_a149_DASmiaBrakeTorqueComman "IDB ECU: a149 DA smia brake torque command invalid";
CM_ SG_ 983 IDB_a150_DIlocStatus2DLC "IDB ECU: a150 d iloc status2 DLC";
CM_ SG_ 983 IDB_a151_DIlocStatus2Counter "IDB ECU: a151 d iloc status2 counter";
CM_ SG_ 983 IDB_a152_DIlocStatus2Checksum "IDB ECU: a152 d iloc status2 checksum";
CM_ SG_ 983 IDB_a155_PMlocStateDLC "IDB ECU: a155 p mloc state DLC";
CM_ SG_ 983 IDB_a156_PMlocStateChecksum "IDB ECU: a156 p mloc state checksum";
CM_ SG_ 983 IDB_a157_PMlocStateCounter "IDB ECU: a157 p mloc state counter";
CM_ BO_ 828 "IDB ECU message: info";
CM_ SG_ 828 IDB_infoIndex "IDB ECU: info index";
CM_ SG_ 828 IDB_infoPcbaID "IDB ECU: info pcba ID";
CM_ SG_ 828 IDB_infoAssemblyID "IDB ECU: info assembly ID";
CM_ SG_ 828 IDB_infoUsageID "IDB ECU: info usage ID";
CM_ SG_ 828 IDB_infoSubUsageID "IDB ECU: info sub usage ID";
CM_ BO_ 1012 "LS ECU message: light show";
CM_ SG_ 1012 LS_lightShowIndex "LS ECU: light show index";
CM_ SG_ 1012 LS_lightLeftRampedChannel1Reques "LS ECU: light left ramped channel1 request";
CM_ SG_ 1012 LS_lightLeftRampedChannel1Durati "LS ECU: light left ramped channel1 duration";
CM_ SG_ 1012 LS_lightLeftRampedChannel2Reques "LS ECU: light left ramped channel2 request";
CM_ SG_ 1012 LS_lightLeftRampedChannel2Durati "LS ECU: light left ramped channel2 duration";
CM_ SG_ 1012 LS_lightLeftRampedChannel3Reques "LS ECU: light left ramped channel3 request";
CM_ SG_ 1012 LS_lightLeftRampedChannel3Durati "LS ECU: light left ramped channel3 duration";
CM_ SG_ 1012 LS_lightLeftRampedChannel4Reques "LS ECU: light left ramped channel4 request";
CM_ SG_ 1012 LS_lightLeftRampedChannel4Durati "LS ECU: light left ramped channel4 duration";
CM_ SG_ 1012 LS_lightLeftRampedChannel5Reques "LS ECU: light left ramped channel5 request";
CM_ SG_ 1012 LS_lightLeftRampedChannel5Durati "LS ECU: light left ramped channel5 duration";
CM_ SG_ 1012 LS_lightLeftRampedChannel6Reques "LS ECU: light left ramped channel6 request";
CM_ SG_ 1012 LS_lightLeftRampedChannel6Durati "LS ECU: light left ramped channel6 duration";
CM_ SG_ 1012 LS_lightLeftRampedChannel7Reques "LS ECU: light left ramped channel7 request";
CM_ SG_ 1012 LS_lightLeftRampedChannel7Durati "LS ECU: light left ramped channel7 duration";
CM_ SG_ 1012 LS_lightRightRampedChannel1Reque "LS ECU: light right ramped channel1 request";
CM_ SG_ 1012 LS_lightRightRampedChannel1Durat "LS ECU: light right ramped channel1 duration; raw 1 = signal not available (SNA)";
CM_ SG_ 1012 LS_lightRightRampedChannel2Reque "LS ECU: light right ramped channel2 request";
CM_ SG_ 1012 LS_lightRightRampedChannel2Durat "LS ECU: light right ramped channel2 duration; raw 1 = signal not available (SNA)";
CM_ SG_ 1012 LS_lightRightRampedChannel3Reque "LS ECU: light right ramped channel3 request";
CM_ SG_ 1012 LS_lightRightRampedChannel3Durat "LS ECU: light right ramped channel3 duration";
CM_ SG_ 1012 LS_lightRightRampedChannel4Reque "LS ECU: light right ramped channel4 request";
CM_ SG_ 1012 LS_lightRightRampedChannel4Durat "LS ECU: light right ramped channel4 duration";
CM_ SG_ 1012 LS_lightRightRampedChannel5Reque "LS ECU: light right ramped channel5 request";
CM_ SG_ 1012 LS_lightRightRampedChannel5Durat "LS ECU: light right ramped channel5 duration";
CM_ SG_ 1012 LS_lightRightRampedChannel6Reque "LS ECU: light right ramped channel6 request";
CM_ SG_ 1012 LS_lightRightRampedChannel6Durat "LS ECU: light right ramped channel6 duration";
CM_ SG_ 1012 LS_lightRightRampedChannel7Reque "LS ECU: light right ramped channel7 request";
CM_ SG_ 1012 LS_lightRightRampedChannel7Durat "LS ECU: light right ramped channel7 duration";
CM_ SG_ 1012 LS_lightRearTurnLeftRequest "LS ECU: light rear turn left request";
CM_ SG_ 1012 LS_lightRearTurnRightRequest "LS ECU: light rear turn right request";
CM_ SG_ 1012 LS_lightSideRepeaterLeftRequest "LS ECU: light side repeater left request";
CM_ SG_ 1012 LS_lightSideRepeaterRightRequest "LS ECU: light side repeater right request";
CM_ SG_ 1012 LS_lightSideMarkerLeftRequest "LS ECU: light side marker left request";
CM_ SG_ 1012 LS_lightSideMarkerRightRequest "LS ECU: light side marker right request";
CM_ SG_ 1012 LS_lightFrontFogLeftRequest "LS ECU: light front fog left request";
CM_ SG_ 1012 LS_lightFrontFogRightRequest "LS ECU: light front fog right request";
CM_ SG_ 1012 LS_lightRearFogRequest "LS ECU: light rear fog request";
CM_ SG_ 1012 LS_lightBrakeRequest "LS ECU: light brake request";
CM_ SG_ 1012 LS_lightTailLeftRequest "LS ECU: light tail left request";
CM_ SG_ 1012 LS_lightTailRightRequest "LS ECU: light tail right request";
CM_ SG_ 1012 LS_lightLicensePlateRequest "LS ECU: light license plate request";
CM_ SG_ 1012 LS_lightReverseRequest "LS ECU: light reverse request";
CM_ SG_ 1012 LS_lightAuxParkLeftRequest "LS ECU: light aux park left request";
CM_ SG_ 1012 LS_lightAuxParkRightRequest "LS ECU: light aux park right request";
CM_ SG_ 1012 LS_mirrorRequestLeft "LS ECU: mirror request left";
CM_ SG_ 1012 LS_mirrorRequestRight "LS ECU: mirror request right";
CM_ SG_ 1012 LS_liftgateRequest "LS ECU: liftgate request";
CM_ SG_ 1012 LS_windowRequestLF "LS ECU: window request LF";
CM_ SG_ 1012 LS_windowRequestLR "LS ECU: window request LR";
CM_ SG_ 1012 LS_windowRequestRF "LS ECU: window request RF";
CM_ SG_ 1012 LS_windowRequestRR "LS ECU: window request RR";
CM_ SG_ 1012 LS_presentingHandleRequestLF "LS ECU: presenting handle request LF";
CM_ SG_ 1012 LS_presentingHandleRequestLR "LS ECU: presenting handle request LR";
CM_ SG_ 1012 LS_presentingHandleRequestRF "LS ECU: presenting handle request RF";
CM_ SG_ 1012 LS_presentingHandleRequestRR "LS ECU: presenting handle request RR";
CM_ SG_ 1012 LS_powerFrontDoorRequestLeft "LS ECU: power front door request left";
CM_ SG_ 1012 LS_powerFrontDoorRequestRight "LS ECU: power front door request right";
CM_ SG_ 1012 LS_falconDoorRequestLeft "LS ECU: falcon door request left";
CM_ SG_ 1012 LS_falconDoorRequestRight "LS ECU: falcon door request right";
CM_ SG_ 1012 LS_chargePortRequest "LS ECU: charge port request; raw 3 = signal not available (SNA)";
CM_ SG_ 1012 LS_chargePortRaveRequest "LS ECU: charge port rave request";
CM_ SG_ 1012 LS_suspensionRequest "LS ECU: suspension request; raw 3 = signal not available (SNA)";
CM_ SG_ 1012 LS_rgbIPFLRed "LS ECU: rgb IPFL red";
CM_ SG_ 1012 LS_rgbIPFLGreen "LS ECU: rgb IPFL green";
CM_ SG_ 1012 LS_rgbIPFLBlue "LS ECU: rgb IPFL blue";
CM_ SG_ 1012 LS_rgbIPFRRed "LS ECU: rgb IPFR red";
CM_ SG_ 1012 LS_rgbIPFRGreen "LS ECU: rgb IPFR green";
CM_ SG_ 1012 LS_rgbIPFRBlue "LS ECU: rgb IPFR blue";
CM_ SG_ 1012 LS_rgbDoorFLForeRed "LS ECU: rgb door FL fore red";
CM_ SG_ 1012 LS_rgbDoorFLForeGreen "LS ECU: rgb door FL fore green";
CM_ SG_ 1012 LS_rgbDoorFLForeBlue "LS ECU: rgb door FL fore blue";
CM_ SG_ 1012 LS_rgbDoorFLAftRed "LS ECU: rgb door FL aft red";
CM_ SG_ 1012 LS_rgbDoorFLAftGreen "LS ECU: rgb door FL aft green";
CM_ SG_ 1012 LS_rgbDoorFLAftBlue "LS ECU: rgb door FL aft blue";
CM_ SG_ 1012 LS_rgbDoorFRForeRed "LS ECU: rgb door FR fore red";
CM_ SG_ 1012 LS_rgbDoorFRForeGreen "LS ECU: rgb door FR fore green";
CM_ SG_ 1012 LS_rgbDoorFRForeBlue "LS ECU: rgb door FR fore blue";
CM_ SG_ 1012 LS_rgbDoorFRAftRed "LS ECU: rgb door FR aft red";
CM_ SG_ 1012 LS_rgbDoorFRAftGreen "LS ECU: rgb door FR aft green";
CM_ SG_ 1012 LS_rgbDoorFRAftBlue "LS ECU: rgb door FR aft blue";
CM_ SG_ 1012 LS_rgbDoorRLForeRed "LS ECU: rgb door RL fore red";
CM_ SG_ 1012 LS_rgbDoorRLForeGreen "LS ECU: rgb door RL fore green";
CM_ SG_ 1012 LS_rgbDoorRLForeBlue "LS ECU: rgb door RL fore blue";
CM_ SG_ 1012 LS_rgbDoorRLAftRed "LS ECU: rgb door RL aft red";
CM_ SG_ 1012 LS_rgbDoorRLAftGreen "LS ECU: rgb door RL aft green";
CM_ SG_ 1012 LS_rgbDoorRLAftBlue "LS ECU: rgb door RL aft blue";
CM_ SG_ 1012 LS_rgbDoorRRForeRed "LS ECU: rgb door RR fore red";
CM_ SG_ 1012 LS_rgbDoorRRForeGreen "LS ECU: rgb door RR fore green";
CM_ SG_ 1012 LS_rgbDoorRRForeBlue "LS ECU: rgb door RR fore blue";
CM_ SG_ 1012 LS_rgbDoorRRAftRed "LS ECU: rgb door RR aft red";
CM_ SG_ 1012 LS_rgbDoorRRAftGreen "LS ECU: rgb door RR aft green";
CM_ SG_ 1012 LS_rgbDoorRRAftBlue "LS ECU: rgb door RR aft blue";
CM_ SG_ 1012 LS_frontMatrix0 "LS ECU: front matrix0";
CM_ SG_ 1012 LS_frontMatrix1 "LS ECU: front matrix1";
CM_ SG_ 1012 LS_frontMatrix2 "LS ECU: front matrix2";
CM_ SG_ 1012 LS_frontMatrix3 "LS ECU: front matrix3";
CM_ SG_ 1012 LS_frontMatrix4 "LS ECU: front matrix4";
CM_ SG_ 1012 LS_frontMatrix5 "LS ECU: front matrix5";
CM_ SG_ 1012 LS_frontMatrix6 "LS ECU: front matrix6";
CM_ SG_ 1012 LS_frontMatrix7 "LS ECU: front matrix7";
CM_ SG_ 1012 LS_frontMatrix8 "LS ECU: front matrix8";
CM_ SG_ 1012 LS_frontMatrix9 "LS ECU: front matrix9";
CM_ SG_ 1012 LS_frontMatrix10 "LS ECU: front matrix10";
CM_ SG_ 1012 LS_frontMatrix11 "LS ECU: front matrix11";
CM_ SG_ 1012 LS_frontMatrix12 "LS ECU: front matrix12";
CM_ SG_ 1012 LS_frontMatrix13 "LS ECU: front matrix13";
CM_ SG_ 1012 LS_frontMatrix14 "LS ECU: front matrix14";
CM_ SG_ 1012 LS_frontMatrix15 "LS ECU: front matrix15";
CM_ SG_ 1012 LS_frontMatrix16 "LS ECU: front matrix16";
CM_ SG_ 1012 LS_frontMatrix17 "LS ECU: front matrix17";
CM_ SG_ 1012 LS_frontMatrix18 "LS ECU: front matrix18";
CM_ SG_ 1012 LS_frontMatrix19 "LS ECU: front matrix19";
CM_ SG_ 1012 LS_frontMatrix20 "LS ECU: front matrix20";
CM_ SG_ 1012 LS_frontMatrix21 "LS ECU: front matrix21";
CM_ SG_ 1012 LS_frontMatrix22 "LS ECU: front matrix22";
CM_ SG_ 1012 LS_frontMatrix23 "LS ECU: front matrix23";
CM_ SG_ 1012 LS_frontMatrix24 "LS ECU: front matrix24";
CM_ SG_ 1012 LS_frontMatrix25 "LS ECU: front matrix25";
CM_ SG_ 1012 LS_frontMatrix26 "LS ECU: front matrix26";
CM_ SG_ 1012 LS_frontMatrix27 "LS ECU: front matrix27";
CM_ SG_ 1012 LS_frontMatrix28 "LS ECU: front matrix28";
CM_ SG_ 1012 LS_frontMatrix29 "LS ECU: front matrix29";
CM_ SG_ 1012 LS_frontMatrix30 "LS ECU: front matrix30";
CM_ SG_ 1012 LS_frontMatrix31 "LS ECU: front matrix31";
CM_ SG_ 1012 LS_frontMatrix32 "LS ECU: front matrix32";
CM_ SG_ 1012 LS_frontMatrix33 "LS ECU: front matrix33";
CM_ SG_ 1012 LS_frontMatrix34 "LS ECU: front matrix34";
CM_ SG_ 1012 LS_frontMatrix35 "LS ECU: front matrix35";
CM_ SG_ 1012 LS_frontMatrix36 "LS ECU: front matrix36";
CM_ SG_ 1012 LS_frontMatrix37 "LS ECU: front matrix37";
CM_ SG_ 1012 LS_frontMatrix38 "LS ECU: front matrix38";
CM_ SG_ 1012 LS_frontMatrix39 "LS ECU: front matrix39";
CM_ SG_ 1012 LS_frontMatrix40 "LS ECU: front matrix40";
CM_ SG_ 1012 LS_frontMatrix41 "LS ECU: front matrix41";
CM_ SG_ 1012 LS_frontMatrix42 "LS ECU: front matrix42";
CM_ SG_ 1012 LS_frontMatrix43 "LS ECU: front matrix43";
CM_ SG_ 1012 LS_frontMatrix44 "LS ECU: front matrix44";
CM_ SG_ 1012 LS_frontMatrix45 "LS ECU: front matrix45";
CM_ SG_ 1012 LS_frontMatrix46 "LS ECU: front matrix46";
CM_ SG_ 1012 LS_frontMatrix47 "LS ECU: front matrix47";
CM_ SG_ 1012 LS_frontMatrix48 "LS ECU: front matrix48";
CM_ SG_ 1012 LS_frontMatrix49 "LS ECU: front matrix49";
CM_ SG_ 1012 LS_frontMatrix50 "LS ECU: front matrix50";
CM_ SG_ 1012 LS_frontMatrix51 "LS ECU: front matrix51";
CM_ SG_ 1012 LS_frontMatrix52 "LS ECU: front matrix52";
CM_ SG_ 1012 LS_frontMatrix53 "LS ECU: front matrix53";
CM_ SG_ 1012 LS_frontMatrix54 "LS ECU: front matrix54";
CM_ SG_ 1012 LS_frontMatrix55 "LS ECU: front matrix55";
CM_ SG_ 1012 LS_frontMatrix56 "LS ECU: front matrix56";
CM_ SG_ 1012 LS_frontMatrix57 "LS ECU: front matrix57";
CM_ SG_ 1012 LS_frontMatrix58 "LS ECU: front matrix58";
CM_ SG_ 1012 LS_frontMatrix59 "LS ECU: front matrix59";
CM_ SG_ 1012 LS_rearMatrix0 "LS ECU: rear matrix0";
CM_ SG_ 1012 LS_rearMatrix1 "LS ECU: rear matrix1";
CM_ SG_ 1012 LS_rearMatrix2 "LS ECU: rear matrix2";
CM_ SG_ 1012 LS_rearMatrix3 "LS ECU: rear matrix3";
CM_ SG_ 1012 LS_rearMatrix4 "LS ECU: rear matrix4";
CM_ SG_ 1012 LS_rearMatrix5 "LS ECU: rear matrix5";
CM_ SG_ 1012 LS_rearMatrix6 "LS ECU: rear matrix6";
CM_ SG_ 1012 LS_rearMatrix7 "LS ECU: rear matrix7";
CM_ SG_ 1012 LS_rearMatrix8 "LS ECU: rear matrix8";
CM_ SG_ 1012 LS_rearMatrix9 "LS ECU: rear matrix9";
CM_ SG_ 1012 LS_rearMatrix10 "LS ECU: rear matrix10";
CM_ SG_ 1012 LS_rearMatrix11 "LS ECU: rear matrix11";
CM_ SG_ 1012 LS_rearMatrix12 "LS ECU: rear matrix12";
CM_ SG_ 1012 LS_rearMatrix13 "LS ECU: rear matrix13";
CM_ SG_ 1012 LS_rearMatrix14 "LS ECU: rear matrix14";
CM_ SG_ 1012 LS_rearMatrix15 "LS ECU: rear matrix15";
CM_ SG_ 1012 LS_rearMatrix16 "LS ECU: rear matrix16";
CM_ SG_ 1012 LS_rearMatrix17 "LS ECU: rear matrix17";
CM_ SG_ 1012 LS_rearMatrix18 "LS ECU: rear matrix18";
CM_ SG_ 1012 LS_rearMatrix19 "LS ECU: rear matrix19";
CM_ SG_ 1012 LS_rearMatrix20 "LS ECU: rear matrix20";
CM_ SG_ 1012 LS_rearMatrix21 "LS ECU: rear matrix21";
CM_ SG_ 1012 LS_rearMatrix22 "LS ECU: rear matrix22";
CM_ SG_ 1012 LS_rearMatrix23 "LS ECU: rear matrix23";
CM_ SG_ 1012 LS_rearMatrix24 "LS ECU: rear matrix24";
CM_ SG_ 1012 LS_rearMatrix25 "LS ECU: rear matrix25";
CM_ SG_ 1012 LS_rearMatrix26 "LS ECU: rear matrix26";
CM_ SG_ 1012 LS_rearMatrix27 "LS ECU: rear matrix27";
CM_ SG_ 1012 LS_rearMatrix28 "LS ECU: rear matrix28";
CM_ SG_ 1012 LS_rearMatrix29 "LS ECU: rear matrix29";
CM_ SG_ 1012 LS_rearMatrix30 "LS ECU: rear matrix30";
CM_ SG_ 1012 LS_rearMatrix31 "LS ECU: rear matrix31";
CM_ SG_ 1012 LS_rearMatrix32 "LS ECU: rear matrix32";
CM_ SG_ 1012 LS_rearMatrix33 "LS ECU: rear matrix33";
CM_ SG_ 1012 LS_rearMatrix34 "LS ECU: rear matrix34";
CM_ SG_ 1012 LS_rearMatrix35 "LS ECU: rear matrix35";
CM_ SG_ 1012 LS_rearMatrix36 "LS ECU: rear matrix36";
CM_ SG_ 1012 LS_rearMatrix37 "LS ECU: rear matrix37";
CM_ SG_ 1012 LS_rearMatrix38 "LS ECU: rear matrix38";
CM_ SG_ 1012 LS_rearMatrix39 "LS ECU: rear matrix39";
CM_ SG_ 1012 LS_rearMatrix40 "LS ECU: rear matrix40";
CM_ SG_ 1012 LS_rearMatrix41 "LS ECU: rear matrix41";
CM_ SG_ 1012 LS_rearMatrix42 "LS ECU: rear matrix42";
CM_ SG_ 1012 LS_rearMatrix43 "LS ECU: rear matrix43";
CM_ SG_ 1012 LS_rearMatrix44 "LS ECU: rear matrix44";
CM_ SG_ 1012 LS_rearMatrix45 "LS ECU: rear matrix45";
CM_ SG_ 1012 LS_rearMatrix46 "LS ECU: rear matrix46";
CM_ SG_ 1012 LS_rearMatrix47 "LS ECU: rear matrix47";
CM_ SG_ 1012 LS_rearMatrix48 "LS ECU: rear matrix48";
CM_ SG_ 1012 LS_rearMatrix49 "LS ECU: rear matrix49";
CM_ SG_ 1012 LS_rearMatrix50 "LS ECU: rear matrix50";
CM_ SG_ 1012 LS_rearMatrix51 "LS ECU: rear matrix51";
CM_ SG_ 1012 LS_rearMatrix52 "LS ECU: rear matrix52";
CM_ SG_ 1012 LS_rearMatrix53 "LS ECU: rear matrix53";
CM_ SG_ 1012 LS_rearMatrix54 "LS ECU: rear matrix54";
CM_ SG_ 1012 LS_rearMatrix55 "LS ECU: rear matrix55";
CM_ SG_ 1012 LS_rearMatrix56 "LS ECU: rear matrix56";
CM_ SG_ 1012 LS_rearMatrix57 "LS ECU: rear matrix57";
CM_ SG_ 1012 LS_rearMatrix58 "LS ECU: rear matrix58";
CM_ SG_ 1012 LS_rearMatrix59 "LS ECU: rear matrix59";
CM_ SG_ 1012 LS_offroadLightBar0 "LS ECU: offroad light bar0";
CM_ SG_ 1012 LS_offroadLightBar1 "LS ECU: offroad light bar1";
CM_ SG_ 1012 LS_offroadLightBar2 "LS ECU: offroad light bar2";
CM_ SG_ 1012 LS_offroadLightBar3 "LS ECU: offroad light bar3";
CM_ SG_ 1012 LS_offroadLightBar4 "LS ECU: offroad light bar4";
CM_ SG_ 1012 LS_offroadLightBar5 "LS ECU: offroad light bar5";
CM_ BO_ 1429 "Occupant classification system message: alert log";
CM_ SG_ 1429 OCS1P_alertID "Occupant classification system: alert ID";
CM_ SG_ 1429 OCS1P_alertState "Occupant classification system: alert state";
CM_ SG_ 1429 OCS1P_a121_sandwichFreq "Occupant classification system: a121 sandwich freq";
CM_ SG_ 1429 OCS1P_a122_sandwichFreq "Occupant classification system: a122 sandwich freq";
CM_ SG_ 1429 OCS1P_a123_sandwichFreq "Occupant classification system: a123 sandwich freq";
CM_ SG_ 1429 OCS1P_a124_cushionSelfFreq "Occupant classification system: a124 cushion self freq";
CM_ SG_ 1429 OCS1P_a125_cushionSelfFreq "Occupant classification system: a125 cushion self freq";
CM_ SG_ 1429 OCS1P_a126_cushionSelfFreq "Occupant classification system: a126 cushion self freq";
CM_ SG_ 1429 OCS1P_a127_seatbackSelfFreq "Occupant classification system: a127 seatback self freq";
CM_ SG_ 1429 OCS1P_a128_seatbackSelfFreq "Occupant classification system: a128 seatback self freq";
CM_ SG_ 1429 OCS1P_a129_seatbackSelfFreq "Occupant classification system: a129 seatback self freq";
CM_ SG_ 1429 OCS1P_a130_sandwichNoCalib "Occupant classification system: a130 sandwich no calib";
CM_ SG_ 1429 OCS1P_a131_cushionSelfNoCalib "Occupant classification system: a131 cushion self no calib";
CM_ SG_ 1429 OCS1P_a132_seatbackSelfNoCalib "Occupant classification system: a132 seatback self no calib";
CM_ SG_ 1429 OCS1P_a133_sandwichBadCalib "Occupant classification system: a133 sandwich bad calib";
CM_ SG_ 1429 OCS1P_a134_uninitializedCalib "Occupant classification system: a134 uninitialized calib";
CM_ SG_ 1429 OCS1P_a135_tempNoCalib "Occupant classification system: a135 temp no calib";
CM_ SG_ 1429 OCS1P_a140_tempInvalidCalib "Occupant classification system: a140 temp invalid calib";
CM_ SG_ 1429 OCS1P_a141_humidityInvalidCalib "Occupant classification system: a141 humidity invalid calib";
CM_ SG_ 1429 OCS1P_a142_tempHumidityInvalid "Occupant classification system: a142 temp humidity invalid";
CM_ SG_ 1429 OCS1P_a143_mismatchPassAirbag "Occupant classification system: a143 mismatch pass airbag";
CM_ SG_ 1429 OCS1P_a144_mismatchCarRegion "Occupant classification system: a144 mismatch car region";
CM_ BO_ 767 "Occupant classification system message: alert matrix";
CM_ SG_ 767 OCS1P_matrixIndex "Occupant classification system: matrix index";
CM_ SG_ 767 OCS1P_w015_NVMMAlert "Occupant classification system: w015 NVMM alert";
CM_ SG_ 767 OCS1P_w121_sandwichOpen "Occupant classification system: w121 sandwich open";
CM_ SG_ 767 OCS1P_w122_sandwichLow "Occupant classification system: w122 sandwich low";
CM_ SG_ 767 OCS1P_w123_sandwichShort "Occupant classification system: w123 sandwich short";
CM_ SG_ 767 OCS1P_w124_cushionSelfOpen "Occupant classification system: w124 cushion self open";
CM_ SG_ 767 OCS1P_w125_cushionSelfLow "Occupant classification system: w125 cushion self low";
CM_ SG_ 767 OCS1P_w126_cushionSelfShort "Occupant classification system: w126 cushion self short";
CM_ SG_ 767 OCS1P_w127_seatbackSelfOpen "Occupant classification system: w127 seatback self open";
CM_ SG_ 767 OCS1P_w128_seatbackSelfLow "Occupant classification system: w128 seatback self low";
CM_ SG_ 767 OCS1P_w129_seatbackSelfShort "Occupant classification system: w129 seatback self short";
CM_ SG_ 767 OCS1P_w130_sandwichNoCalib "Occupant classification system: w130 sandwich no calib";
CM_ SG_ 767 OCS1P_w131_cushionSelfNoCalib "Occupant classification system: w131 cushion self no calib";
CM_ SG_ 767 OCS1P_w132_seatbackSelfNoCalib "Occupant classification system: w132 seatback self no calib";
CM_ SG_ 767 OCS1P_w133_sandwichBadCalib "Occupant classification system: w133 sandwich bad calib";
CM_ SG_ 767 OCS1P_w134_uninitializedCalib "Occupant classification system: w134 uninitialized calib";
CM_ SG_ 767 OCS1P_w135_tempNoCalib "Occupant classification system: w135 temp no calib";
CM_ SG_ 767 OCS1P_w136_cushionSelfDutyLow "Occupant classification system: w136 cushion self duty low";
CM_ SG_ 767 OCS1P_w137_cushionSelfDutyHigh "Occupant classification system: w137 cushion self duty high";
CM_ SG_ 767 OCS1P_w138_seatbackSelfDutyLow "Occupant classification system: w138 seatback self duty low";
CM_ SG_ 767 OCS1P_w139_seatbackSelfDutyHigh "Occupant classification system: w139 seatback self duty high";
CM_ SG_ 767 OCS1P_w140_tempInvalidCalib "Occupant classification system: w140 temp invalid calib";
CM_ SG_ 767 OCS1P_w141_humidityInvalidCalib "Occupant classification system: w141 humidity invalid calib";
CM_ SG_ 767 OCS1P_w142_tempHumidityInvalid "Occupant classification system: w142 temp humidity invalid";
CM_ SG_ 767 OCS1P_w143_mismatchPassAirbag "Occupant classification system: w143 mismatch pass airbag";
CM_ SG_ 767 OCS1P_w144_mismatchCarRegion "Occupant classification system: w144 mismatch car region";
CM_ SG_ 767 OCS1P_w145_rebaselineTriggered "Occupant classification system: w145 rebaseline triggered";
CM_ SG_ 767 OCS1P_w148_classificationMismatc "Occupant classification system: w148 classification mismatch";
CM_ SG_ 767 OCS1P_w150_rbEntryTriggered "Occupant classification system: w150 rb entry triggered";
CM_ SG_ 767 OCS1P_w151_rbEntryExited "Occupant classification system: w151 rb entry exited";
CM_ SG_ 767 OCS1P_w152_rbExit1Triggered "Occupant classification system: w152 rb exit1 triggered";
CM_ SG_ 767 OCS1P_w153_rbExit1Exited "Occupant classification system: w153 rb exit1 exited";
CM_ SG_ 767 OCS1P_w154_rbExit2Exited1 "Occupant classification system: w154 rb exit2 exited1";
CM_ SG_ 767 OCS1P_w155_rbExit2Exited2 "Occupant classification system: w155 rb exit2 exited2";
CM_ SG_ 767 OCS1P_w156_seatbeltReminderUnava "Occupant classification system: w156 seatbelt reminder unavailable";
CM_ BO_ 766 "Occupant classification system message: info";
CM_ SG_ 766 OCS1P_infoIndex "Occupant classification system: info index";
CM_ SG_ 766 OCS1P_infoBuildType "Occupant classification system: info build type";
CM_ SG_ 766 OCS1P_infoBuildConfigID "Occupant classification system: info build config ID";
CM_ SG_ 766 OCS1P_infoHardwareID "Occupant classification system: info hardware ID";
CM_ SG_ 766 OCS1P_infoComponentID "Occupant classification system: info component ID";
CM_ SG_ 766 OCS1P_infoPcbaID "Occupant classification system: info pcba ID";
CM_ SG_ 766 OCS1P_infoAssemblyID "Occupant classification system: info assembly ID";
CM_ SG_ 766 OCS1P_infoUsageID "Occupant classification system: info usage ID";
CM_ SG_ 766 OCS1P_infoSubUsageID "Occupant classification system: info sub usage ID";
CM_ SG_ 766 OCS1P_infoApplicationCRC "Occupant classification system: info application CRC";
CM_ SG_ 766 OCS1P_infoBootSvnRev "Occupant classification system: info boot svn rev";
CM_ SG_ 766 OCS1P_infoAppGitHashBytes "Occupant classification system: info app git hash bytes";
CM_ SG_ 766 OCS1P_infoBootGitHashBytes "Occupant classification system: info boot git hash bytes";
CM_ SG_ 766 OCS1P_infoPlatformType "Occupant classification system: info platform type";
CM_ SG_ 766 OCS1P_infoBootUdsProtoVersion "Occupant classification system: info boot uds proto version";
CM_ SG_ 766 OCS1P_infoBootloaderCRC "Occupant classification system: info bootloader CRC";
CM_ BO_ 771 "Occupant classification system message: status";
CM_ SG_ 771 OCS1P_occupantClassification "Occupant Classification (Filtered); raw 255 = signal not available (SNA)";
CM_ SG_ 771 OCS1P_occupantClassificationQF "Occupant classification system: occupant classification QF";
CM_ SG_ 771 OCS1P_occupiedState "Passenger seat occupied State; raw 3 = signal not available (SNA)";
CM_ SG_ 771 OCS1P_triggerSnapshot "Occupant classification system: trigger snapshot";
CM_ SG_ 771 OCS1P_occupantClassificationRaw "Occupant classification system: occupant classification raw; raw 7 = signal not available (SNA)";
CM_ SG_ 771 OCS1P_occupantClassificationSelf "Occupant classification system: occupant classification self; raw 7 = signal not available (SNA)";
CM_ SG_ 771 OCS1P_occupantClassificationRawC "Occupant classification system: occupant classification raw cap; raw 7 = signal not available (SNA)";
CM_ SG_ 771 OCS1P_occupantClassificationCap "Occupant classification system: occupant classification cap; raw 7 = signal not available (SNA)";
CM_ SG_ 771 OCS1P_classificationHeld "Whether occupant classification is filtered due to door state or stability based on frequency";
CM_ SG_ 771 OCS1P_cushionStable "Whether frequency reading is unchanging of Cushion Self sensor";
CM_ SG_ 771 OCS1P_classificationExtHold "Occupant classification request to be filtered due to door state";
CM_ SG_ 771 OCS1P_classificationHoldState "Occupant classification system: classification hold state";
CM_ SG_ 771 OCS1P_classificationVariant "The combination of sensors used to classify occupant";
CM_ SG_ 771 OCS1P_sandwichDisabled "Cushion mutual sensor disabled by calibration";
CM_ SG_ 771 OCS1P_noSandwichType "Configuration set in factory or service that determines logic around uninstalled sandwich";
CM_ SG_ 771 OCS1P_sandwichBoundaryType "Occupant classification system: sandwich boundary type";
CM_ SG_ 771 OCS1P_sbrBoundaryType "Occupant classification system: sbr boundary type";
CM_ SG_ 771 OCS1P_occupiedStateCap "Occupant classification system: occupied state cap; raw 3 = signal not available (SNA)";
CM_ SG_ 771 OCS1P_seatbackStable "Whether frequency reading is unchanging of Seatback Self sensor";
CM_ SG_ 771 OCS1P_sandwichStable "Whether frequency reading is unchanging of Cushion Mutual sensor";
CM_ SG_ 771 OCS1P_cushionStableCap "Occupant classification system: cushion stable cap";
CM_ SG_ 771 OCS1P_seatbackStableCap "Occupant classification system: seatback stable cap";
CM_ SG_ 771 OCS1P_classificationHeldCap "Occupant classification system: classification held cap";
CM_ SG_ 771 OCS1P_statusCounter "Occupant classification system: status counter";
CM_ SG_ 771 OCS1P_statusChecksum "Occupant classification system: status checksum";
CM_ BO_ 1486 "Parking assist sensors message: alert log";
CM_ SG_ 1486 PARK_alertID "Parking assist sensors: alert ID";
CM_ SG_ 1486 PARK_alertState "Parking assist sensors: alert state";
CM_ SG_ 1486 PARK_sw001_sensorTemperature "Parking assist sensors: sw001 sensor temperature";
CM_ SG_ 1486 PARK_sw002_membraneDisconct "Parking assist sensors: sw002 membrane disconct";
CM_ SG_ 1486 PARK_sw002_dampResistorFail "Parking assist sensors: sw002 damp resistor fail";
CM_ SG_ 1486 PARK_sw002_resonanceDrift "Parking assist sensors: sw002 resonance drift";
CM_ SG_ 1486 PARK_sw002_sensorCRC "Parking assist sensors: sw002 sensor CRC";
CM_ SG_ 1486 PARK_sw002_recieveFailure "Parking assist sensors: sw002 recieve failure";
CM_ SG_ 1486 PARK_sw002_diagnosticTransferErr "Parking assist sensors: sw002 diagnostic transfer error";
CM_ SG_ 1486 PARK_sw003_linError "Parking assist sensors: sw003 lin error";
CM_ SG_ 1486 PARK_sw003_linBusError "Parking assist sensors: sw003 lin bus error";
CM_ SG_ 1486 PARK_sw003_linFrameCountError "Parking assist sensors: sw003 lin frame count error";
CM_ SG_ 1486 PARK_sw004_reverbPeriod "Parking assist sensors: sw004 reverb period";
CM_ SG_ 1486 PARK_sw004_reverbTime "Parking assist sensors: sw004 reverb time";
CM_ SG_ 1486 PARK_sw004_highAttenTime "Parking assist sensors: sw004 high atten time";
CM_ SG_ 1486 PARK_sw004_closeConstEcho "Parking assist sensors: sw004 close const echo";
CM_ SG_ 1486 PARK_sw004_lowAttenTime "Parking assist sensors: sw004 low atten time";
CM_ SG_ 1486 PARK_sw004_attenTimeJitter "Parking assist sensors: sw004 atten time jitter";
CM_ SG_ 1486 PARK_sw004_reverbFreqJitter "Parking assist sensors: sw004 reverb freq jitter";
CM_ SG_ 1486 PARK_sw006_sensorTemperature "Parking assist sensors: sw006 sensor temperature";
CM_ SG_ 1486 PARK_sw007_membraneDisconct "Parking assist sensors: sw007 membrane disconct";
CM_ SG_ 1486 PARK_sw007_dampResistorFail "Parking assist sensors: sw007 damp resistor fail";
CM_ SG_ 1486 PARK_sw007_resonanceDrift "Parking assist sensors: sw007 resonance drift";
CM_ SG_ 1486 PARK_sw007_sensorCRC "Parking assist sensors: sw007 sensor CRC";
CM_ SG_ 1486 PARK_sw007_recieveFailure "Parking assist sensors: sw007 recieve failure";
CM_ SG_ 1486 PARK_sw007_diagnosticTransferErr "Parking assist sensors: sw007 diagnostic transfer error";
CM_ SG_ 1486 PARK_sw008_linError "Parking assist sensors: sw008 lin error";
CM_ SG_ 1486 PARK_sw008_linBusError "Parking assist sensors: sw008 lin bus error";
CM_ SG_ 1486 PARK_sw008_linFrameCountError "Parking assist sensors: sw008 lin frame count error";
CM_ SG_ 1486 PARK_sw009_reverbPeriod "Parking assist sensors: sw009 reverb period";
CM_ SG_ 1486 PARK_sw009_reverbTime "Parking assist sensors: sw009 reverb time";
CM_ SG_ 1486 PARK_sw009_highAttenTime "Parking assist sensors: sw009 high atten time";
CM_ SG_ 1486 PARK_sw009_closeConstEcho "Parking assist sensors: sw009 close const echo";
CM_ SG_ 1486 PARK_sw009_lowAttenTime "Parking assist sensors: sw009 low atten time";
CM_ SG_ 1486 PARK_sw009_attenTimeJitter "Parking assist sensors: sw009 atten time jitter";
CM_ SG_ 1486 PARK_sw009_reverbFreqJitter "Parking assist sensors: sw009 reverb freq jitter";
CM_ SG_ 1486 PARK_sw011_sensorTemperature "Parking assist sensors: sw011 sensor temperature";
CM_ SG_ 1486 PARK_sw012_membraneDisconct "Parking assist sensors: sw012 membrane disconct";
CM_ SG_ 1486 PARK_sw012_dampResistorFail "Parking assist sensors: sw012 damp resistor fail";
CM_ SG_ 1486 PARK_sw012_resonanceDrift "Parking assist sensors: sw012 resonance drift";
CM_ SG_ 1486 PARK_sw012_sensorCRC "Parking assist sensors: sw012 sensor CRC";
CM_ SG_ 1486 PARK_sw012_recieveFailure "Parking assist sensors: sw012 recieve failure";
CM_ SG_ 1486 PARK_sw012_diagnosticTransferErr "Parking assist sensors: sw012 diagnostic transfer error";
CM_ SG_ 1486 PARK_sw013_linError "Parking assist sensors: sw013 lin error";
CM_ SG_ 1486 PARK_sw013_linBusError "Parking assist sensors: sw013 lin bus error";
CM_ SG_ 1486 PARK_sw013_linFrameCountError "Parking assist sensors: sw013 lin frame count error";
CM_ SG_ 1486 PARK_sw014_reverbPeriod "Parking assist sensors: sw014 reverb period";
CM_ SG_ 1486 PARK_sw014_reverbTime "Parking assist sensors: sw014 reverb time";
CM_ SG_ 1486 PARK_sw014_highAttenTime "Parking assist sensors: sw014 high atten time";
CM_ SG_ 1486 PARK_sw014_closeConstEcho "Parking assist sensors: sw014 close const echo";
CM_ SG_ 1486 PARK_sw014_lowAttenTime "Parking assist sensors: sw014 low atten time";
CM_ SG_ 1486 PARK_sw014_attenTimeJitter "Parking assist sensors: sw014 atten time jitter";
CM_ SG_ 1486 PARK_sw014_reverbFreqJitter "Parking assist sensors: sw014 reverb freq jitter";
CM_ SG_ 1486 PARK_sw016_sensorTemperature "Parking assist sensors: sw016 sensor temperature";
CM_ SG_ 1486 PARK_sw017_membraneDisconct "Parking assist sensors: sw017 membrane disconct";
CM_ SG_ 1486 PARK_sw017_dampResistorFail "Parking assist sensors: sw017 damp resistor fail";
CM_ SG_ 1486 PARK_sw017_resonanceDrift "Parking assist sensors: sw017 resonance drift";
CM_ SG_ 1486 PARK_sw017_sensorCRC "Parking assist sensors: sw017 sensor CRC";
CM_ SG_ 1486 PARK_sw017_recieveFailure "Parking assist sensors: sw017 recieve failure";
CM_ SG_ 1486 PARK_sw017_diagnosticTransferErr "Parking assist sensors: sw017 diagnostic transfer error";
CM_ SG_ 1486 PARK_sw018_linError "Parking assist sensors: sw018 lin error";
CM_ SG_ 1486 PARK_sw018_linBusError "Parking assist sensors: sw018 lin bus error";
CM_ SG_ 1486 PARK_sw018_linFrameCountError "Parking assist sensors: sw018 lin frame count error";
CM_ SG_ 1486 PARK_sw019_reverbPeriod "Parking assist sensors: sw019 reverb period";
CM_ SG_ 1486 PARK_sw019_reverbTime "Parking assist sensors: sw019 reverb time";
CM_ SG_ 1486 PARK_sw019_highAttenTime "Parking assist sensors: sw019 high atten time";
CM_ SG_ 1486 PARK_sw019_closeConstEcho "Parking assist sensors: sw019 close const echo";
CM_ SG_ 1486 PARK_sw019_lowAttenTime "Parking assist sensors: sw019 low atten time";
CM_ SG_ 1486 PARK_sw019_attenTimeJitter "Parking assist sensors: sw019 atten time jitter";
CM_ SG_ 1486 PARK_sw019_reverbFreqJitter "Parking assist sensors: sw019 reverb freq jitter";
CM_ SG_ 1486 PARK_sw021_sensorTemperature "Parking assist sensors: sw021 sensor temperature";
CM_ SG_ 1486 PARK_sw022_membraneDisconct "Parking assist sensors: sw022 membrane disconct";
CM_ SG_ 1486 PARK_sw022_dampResistorFail "Parking assist sensors: sw022 damp resistor fail";
CM_ SG_ 1486 PARK_sw022_resonanceDrift "Parking assist sensors: sw022 resonance drift";
CM_ SG_ 1486 PARK_sw022_sensorCRC "Parking assist sensors: sw022 sensor CRC";
CM_ SG_ 1486 PARK_sw022_recieveFailure "Parking assist sensors: sw022 recieve failure";
CM_ SG_ 1486 PARK_sw022_diagnosticTransferErr "Parking assist sensors: sw022 diagnostic transfer error";
CM_ SG_ 1486 PARK_sw023_linError "Parking assist sensors: sw023 lin error";
CM_ SG_ 1486 PARK_sw023_linBusError "Parking assist sensors: sw023 lin bus error";
CM_ SG_ 1486 PARK_sw023_linFrameCountError "Parking assist sensors: sw023 lin frame count error";
CM_ SG_ 1486 PARK_sw024_reverbPeriod "Parking assist sensors: sw024 reverb period";
CM_ SG_ 1486 PARK_sw024_reverbTime "Parking assist sensors: sw024 reverb time";
CM_ SG_ 1486 PARK_sw024_highAttenTime "Parking assist sensors: sw024 high atten time";
CM_ SG_ 1486 PARK_sw024_closeConstEcho "Parking assist sensors: sw024 close const echo";
CM_ SG_ 1486 PARK_sw024_lowAttenTime "Parking assist sensors: sw024 low atten time";
CM_ SG_ 1486 PARK_sw024_attenTimeJitter "Parking assist sensors: sw024 atten time jitter";
CM_ SG_ 1486 PARK_sw024_reverbFreqJitter "Parking assist sensors: sw024 reverb freq jitter";
CM_ SG_ 1486 PARK_sw026_sensorTemperature "Parking assist sensors: sw026 sensor temperature";
CM_ SG_ 1486 PARK_sw027_membraneDisconct "Parking assist sensors: sw027 membrane disconct";
CM_ SG_ 1486 PARK_sw027_dampResistorFail "Parking assist sensors: sw027 damp resistor fail";
CM_ SG_ 1486 PARK_sw027_resonanceDrift "Parking assist sensors: sw027 resonance drift";
CM_ SG_ 1486 PARK_sw027_sensorCRC "Parking assist sensors: sw027 sensor CRC";
CM_ SG_ 1486 PARK_sw027_recieveFailure "Parking assist sensors: sw027 recieve failure";
CM_ SG_ 1486 PARK_sw027_diagnosticTransferErr "Parking assist sensors: sw027 diagnostic transfer error";
CM_ SG_ 1486 PARK_sw028_linError "Parking assist sensors: sw028 lin error";
CM_ SG_ 1486 PARK_sw028_linBusError "Parking assist sensors: sw028 lin bus error";
CM_ SG_ 1486 PARK_sw028_linFrameCountError "Parking assist sensors: sw028 lin frame count error";
CM_ SG_ 1486 PARK_sw029_reverbPeriod "Parking assist sensors: sw029 reverb period";
CM_ SG_ 1486 PARK_sw029_reverbTime "Parking assist sensors: sw029 reverb time";
CM_ SG_ 1486 PARK_sw029_highAttenTime "Parking assist sensors: sw029 high atten time";
CM_ SG_ 1486 PARK_sw029_closeConstEcho "Parking assist sensors: sw029 close const echo";
CM_ SG_ 1486 PARK_sw029_lowAttenTime "Parking assist sensors: sw029 low atten time";
CM_ SG_ 1486 PARK_sw029_attenTimeJitter "Parking assist sensors: sw029 atten time jitter";
CM_ SG_ 1486 PARK_sw029_reverbFreqJitter "Parking assist sensors: sw029 reverb freq jitter";
CM_ SG_ 1486 PARK_sw031_sensorTemperature "Parking assist sensors: sw031 sensor temperature";
CM_ SG_ 1486 PARK_sw032_membraneDisconct "Parking assist sensors: sw032 membrane disconct";
CM_ SG_ 1486 PARK_sw032_dampResistorFail "Parking assist sensors: sw032 damp resistor fail";
CM_ SG_ 1486 PARK_sw032_resonanceDrift "Parking assist sensors: sw032 resonance drift";
CM_ SG_ 1486 PARK_sw032_sensorCRC "Parking assist sensors: sw032 sensor CRC";
CM_ SG_ 1486 PARK_sw032_recieveFailure "Parking assist sensors: sw032 recieve failure";
CM_ SG_ 1486 PARK_sw032_diagnosticTransferErr "Parking assist sensors: sw032 diagnostic transfer error";
CM_ SG_ 1486 PARK_sw033_linError "Parking assist sensors: sw033 lin error";
CM_ SG_ 1486 PARK_sw033_linBusError "Parking assist sensors: sw033 lin bus error";
CM_ SG_ 1486 PARK_sw033_linFrameCountError "Parking assist sensors: sw033 lin frame count error";
CM_ SG_ 1486 PARK_sw034_reverbPeriod "Parking assist sensors: sw034 reverb period";
CM_ SG_ 1486 PARK_sw034_reverbTime "Parking assist sensors: sw034 reverb time";
CM_ SG_ 1486 PARK_sw034_highAttenTime "Parking assist sensors: sw034 high atten time";
CM_ SG_ 1486 PARK_sw034_closeConstEcho "Parking assist sensors: sw034 close const echo";
CM_ SG_ 1486 PARK_sw034_lowAttenTime "Parking assist sensors: sw034 low atten time";
CM_ SG_ 1486 PARK_sw034_attenTimeJitter "Parking assist sensors: sw034 atten time jitter";
CM_ SG_ 1486 PARK_sw034_reverbFreqJitter "Parking assist sensors: sw034 reverb freq jitter";
CM_ SG_ 1486 PARK_sw036_sensorTemperature "Parking assist sensors: sw036 sensor temperature";
CM_ SG_ 1486 PARK_sw037_membraneDisconct "Parking assist sensors: sw037 membrane disconct";
CM_ SG_ 1486 PARK_sw037_dampResistorFail "Parking assist sensors: sw037 damp resistor fail";
CM_ SG_ 1486 PARK_sw037_resonanceDrift "Parking assist sensors: sw037 resonance drift";
CM_ SG_ 1486 PARK_sw037_sensorCRC "Parking assist sensors: sw037 sensor CRC";
CM_ SG_ 1486 PARK_sw037_recieveFailure "Parking assist sensors: sw037 recieve failure";
CM_ SG_ 1486 PARK_sw037_diagnosticTransferErr "Parking assist sensors: sw037 diagnostic transfer error";
CM_ SG_ 1486 PARK_sw038_linError "Parking assist sensors: sw038 lin error";
CM_ SG_ 1486 PARK_sw038_linBusError "Parking assist sensors: sw038 lin bus error";
CM_ SG_ 1486 PARK_sw038_linFrameCountError "Parking assist sensors: sw038 lin frame count error";
CM_ SG_ 1486 PARK_sw039_reverbPeriod "Parking assist sensors: sw039 reverb period";
CM_ SG_ 1486 PARK_sw039_reverbTime "Parking assist sensors: sw039 reverb time";
CM_ SG_ 1486 PARK_sw039_highAttenTime "Parking assist sensors: sw039 high atten time";
CM_ SG_ 1486 PARK_sw039_closeConstEcho "Parking assist sensors: sw039 close const echo";
CM_ SG_ 1486 PARK_sw039_lowAttenTime "Parking assist sensors: sw039 low atten time";
CM_ SG_ 1486 PARK_sw039_attenTimeJitter "Parking assist sensors: sw039 atten time jitter";
CM_ SG_ 1486 PARK_sw039_reverbFreqJitter "Parking assist sensors: sw039 reverb freq jitter";
CM_ SG_ 1486 PARK_sw041_sensorTemperature "Parking assist sensors: sw041 sensor temperature";
CM_ SG_ 1486 PARK_sw042_membraneDisconct "Parking assist sensors: sw042 membrane disconct";
CM_ SG_ 1486 PARK_sw042_dampResistorFail "Parking assist sensors: sw042 damp resistor fail";
CM_ SG_ 1486 PARK_sw042_resonanceDrift "Parking assist sensors: sw042 resonance drift";
CM_ SG_ 1486 PARK_sw042_sensorCRC "Parking assist sensors: sw042 sensor CRC";
CM_ SG_ 1486 PARK_sw042_recieveFailure "Parking assist sensors: sw042 recieve failure";
CM_ SG_ 1486 PARK_sw042_diagnosticTransferErr "Parking assist sensors: sw042 diagnostic transfer error";
CM_ SG_ 1486 PARK_sw043_linError "Parking assist sensors: sw043 lin error";
CM_ SG_ 1486 PARK_sw043_linBusError "Parking assist sensors: sw043 lin bus error";
CM_ SG_ 1486 PARK_sw043_linFrameCountError "Parking assist sensors: sw043 lin frame count error";
CM_ SG_ 1486 PARK_sw044_reverbPeriod "Parking assist sensors: sw044 reverb period";
CM_ SG_ 1486 PARK_sw044_reverbTime "Parking assist sensors: sw044 reverb time";
CM_ SG_ 1486 PARK_sw044_highAttenTime "Parking assist sensors: sw044 high atten time";
CM_ SG_ 1486 PARK_sw044_closeConstEcho "Parking assist sensors: sw044 close const echo";
CM_ SG_ 1486 PARK_sw044_lowAttenTime "Parking assist sensors: sw044 low atten time";
CM_ SG_ 1486 PARK_sw044_attenTimeJitter "Parking assist sensors: sw044 atten time jitter";
CM_ SG_ 1486 PARK_sw044_reverbFreqJitter "Parking assist sensors: sw044 reverb freq jitter";
CM_ SG_ 1486 PARK_sw046_sensorTemperature "Parking assist sensors: sw046 sensor temperature";
CM_ SG_ 1486 PARK_sw047_membraneDisconct "Parking assist sensors: sw047 membrane disconct";
CM_ SG_ 1486 PARK_sw047_dampResistorFail "Parking assist sensors: sw047 damp resistor fail";
CM_ SG_ 1486 PARK_sw047_resonanceDrift "Parking assist sensors: sw047 resonance drift";
CM_ SG_ 1486 PARK_sw047_sensorCRC "Parking assist sensors: sw047 sensor CRC";
CM_ SG_ 1486 PARK_sw047_recieveFailure "Parking assist sensors: sw047 recieve failure";
CM_ SG_ 1486 PARK_sw047_diagnosticTransferErr "Parking assist sensors: sw047 diagnostic transfer error";
CM_ SG_ 1486 PARK_sw048_linError "Parking assist sensors: sw048 lin error";
CM_ SG_ 1486 PARK_sw048_linBusError "Parking assist sensors: sw048 lin bus error";
CM_ SG_ 1486 PARK_sw048_linFrameCountError "Parking assist sensors: sw048 lin frame count error";
CM_ SG_ 1486 PARK_sw049_reverbPeriod "Parking assist sensors: sw049 reverb period";
CM_ SG_ 1486 PARK_sw049_reverbTime "Parking assist sensors: sw049 reverb time";
CM_ SG_ 1486 PARK_sw049_highAttenTime "Parking assist sensors: sw049 high atten time";
CM_ SG_ 1486 PARK_sw049_closeConstEcho "Parking assist sensors: sw049 close const echo";
CM_ SG_ 1486 PARK_sw049_lowAttenTime "Parking assist sensors: sw049 low atten time";
CM_ SG_ 1486 PARK_sw049_attenTimeJitter "Parking assist sensors: sw049 atten time jitter";
CM_ SG_ 1486 PARK_sw049_reverbFreqJitter "Parking assist sensors: sw049 reverb freq jitter";
CM_ SG_ 1486 PARK_sw051_sensorTemperature "Parking assist sensors: sw051 sensor temperature";
CM_ SG_ 1486 PARK_sw052_membraneDisconct "Parking assist sensors: sw052 membrane disconct";
CM_ SG_ 1486 PARK_sw052_dampResistorFail "Parking assist sensors: sw052 damp resistor fail";
CM_ SG_ 1486 PARK_sw052_resonanceDrift "Parking assist sensors: sw052 resonance drift";
CM_ SG_ 1486 PARK_sw052_sensorCRC "Parking assist sensors: sw052 sensor CRC";
CM_ SG_ 1486 PARK_sw052_recieveFailure "Parking assist sensors: sw052 recieve failure";
CM_ SG_ 1486 PARK_sw052_diagnosticTransferErr "Parking assist sensors: sw052 diagnostic transfer error";
CM_ SG_ 1486 PARK_sw053_linError "Parking assist sensors: sw053 lin error";
CM_ SG_ 1486 PARK_sw053_linBusError "Parking assist sensors: sw053 lin bus error";
CM_ SG_ 1486 PARK_sw053_linFrameCountError "Parking assist sensors: sw053 lin frame count error";
CM_ SG_ 1486 PARK_sw054_reverbPeriod "Parking assist sensors: sw054 reverb period";
CM_ SG_ 1486 PARK_sw054_reverbTime "Parking assist sensors: sw054 reverb time";
CM_ SG_ 1486 PARK_sw054_highAttenTime "Parking assist sensors: sw054 high atten time";
CM_ SG_ 1486 PARK_sw054_closeConstEcho "Parking assist sensors: sw054 close const echo";
CM_ SG_ 1486 PARK_sw054_lowAttenTime "Parking assist sensors: sw054 low atten time";
CM_ SG_ 1486 PARK_sw054_attenTimeJitter "Parking assist sensors: sw054 atten time jitter";
CM_ SG_ 1486 PARK_sw054_reverbFreqJitter "Parking assist sensors: sw054 reverb freq jitter";
CM_ SG_ 1486 PARK_sw056_sensorTemperature "Parking assist sensors: sw056 sensor temperature";
CM_ SG_ 1486 PARK_sw057_membraneDisconct "Parking assist sensors: sw057 membrane disconct";
CM_ SG_ 1486 PARK_sw057_dampResistorFail "Parking assist sensors: sw057 damp resistor fail";
CM_ SG_ 1486 PARK_sw057_resonanceDrift "Parking assist sensors: sw057 resonance drift";
CM_ SG_ 1486 PARK_sw057_sensorCRC "Parking assist sensors: sw057 sensor CRC";
CM_ SG_ 1486 PARK_sw057_recieveFailure "Parking assist sensors: sw057 recieve failure";
CM_ SG_ 1486 PARK_sw057_diagnosticTransferErr "Parking assist sensors: sw057 diagnostic transfer error";
CM_ SG_ 1486 PARK_sw058_linError "Parking assist sensors: sw058 lin error";
CM_ SG_ 1486 PARK_sw058_linBusError "Parking assist sensors: sw058 lin bus error";
CM_ SG_ 1486 PARK_sw058_linFrameCountError "Parking assist sensors: sw058 lin frame count error";
CM_ SG_ 1486 PARK_sw059_reverbPeriod "Parking assist sensors: sw059 reverb period";
CM_ SG_ 1486 PARK_sw059_reverbTime "Parking assist sensors: sw059 reverb time";
CM_ SG_ 1486 PARK_sw059_highAttenTime "Parking assist sensors: sw059 high atten time";
CM_ SG_ 1486 PARK_sw059_closeConstEcho "Parking assist sensors: sw059 close const echo";
CM_ SG_ 1486 PARK_sw059_lowAttenTime "Parking assist sensors: sw059 low atten time";
CM_ SG_ 1486 PARK_sw059_attenTimeJitter "Parking assist sensors: sw059 atten time jitter";
CM_ SG_ 1486 PARK_sw059_reverbFreqJitter "Parking assist sensors: sw059 reverb freq jitter";
CM_ SG_ 1486 PARK_sw061_voltage "Parking assist sensors: sw061 voltage";
CM_ SG_ 1486 PARK_sw063_voltage "Parking assist sensors: sw063 voltage";
CM_ SG_ 1486 PARK_sw064_faultCode "Parking assist sensors: sw064 fault code";
CM_ SG_ 1486 PARK_sw065_expectedCRC "Parking assist sensors: sw065 expected CRC";
CM_ SG_ 1486 PARK_sw065_calculatedCRC "Parking assist sensors: sw065 calculated CRC";
CM_ SG_ 1486 PARK_sw066_placeHolder "Parking assist sensors: sw066 place holder";
CM_ SG_ 1486 PARK_sw068_placeHolder "Parking assist sensors: sw068 place holder";
CM_ SG_ 1486 PARK_sw069_messageID "Parking assist sensors: sw069 message ID";
CM_ SG_ 1486 PARK_sw070_messageID "Parking assist sensors: sw070 message ID";
CM_ SG_ 1486 PARK_sw071_messageID "Parking assist sensors: sw071 message ID";
CM_ SG_ 1486 PARK_sw072_messageID "Parking assist sensors: sw072 message ID";
CM_ SG_ 1486 PARK_sw073_messageID "Parking assist sensors: sw073 message ID";
CM_ SG_ 1486 PARK_sw074_messageID "Parking assist sensors: sw074 message ID";
CM_ SG_ 1486 PARK_sw075_messageID "Parking assist sensors: sw075 message ID";
CM_ SG_ 1486 PARK_sw076_messageID "Parking assist sensors: sw076 message ID";
CM_ SG_ 1486 PARK_sw077_errorExp "Parking assist sensors: sw077 error exp";
CM_ SG_ 1486 PARK_sw077_errorRx "Parking assist sensors: sw077 error rx";
CM_ SG_ 1486 PARK_sw077_messageID "Parking assist sensors: sw077 message ID";
CM_ SG_ 1486 PARK_sw077_errorType "Parking assist sensors: sw077 error type";
CM_ SG_ 1486 PARK_sw078_errorExp "Parking assist sensors: sw078 error exp";
CM_ SG_ 1486 PARK_sw078_errorRx "Parking assist sensors: sw078 error rx";
CM_ SG_ 1486 PARK_sw078_messageID "Parking assist sensors: sw078 message ID";
CM_ SG_ 1486 PARK_sw078_errorType "Parking assist sensors: sw078 error type";
CM_ SG_ 1486 PARK_sw079_errorExp "Parking assist sensors: sw079 error exp";
CM_ SG_ 1486 PARK_sw079_errorRx "Parking assist sensors: sw079 error rx";
CM_ SG_ 1486 PARK_sw079_messageID "Parking assist sensors: sw079 message ID";
CM_ SG_ 1486 PARK_sw079_errorType "Parking assist sensors: sw079 error type";
CM_ SG_ 1486 PARK_sw080_errorExp "Parking assist sensors: sw080 error exp";
CM_ SG_ 1486 PARK_sw080_errorRx "Parking assist sensors: sw080 error rx";
CM_ SG_ 1486 PARK_sw080_messageID "Parking assist sensors: sw080 message ID";
CM_ SG_ 1486 PARK_sw080_errorType "Parking assist sensors: sw080 error type";
CM_ SG_ 1486 PARK_sw081_errorExp "Parking assist sensors: sw081 error exp";
CM_ SG_ 1486 PARK_sw081_errorRx "Parking assist sensors: sw081 error rx";
CM_ SG_ 1486 PARK_sw081_messageID "Parking assist sensors: sw081 message ID";
CM_ SG_ 1486 PARK_sw081_errorType "Parking assist sensors: sw081 error type";
CM_ SG_ 1486 PARK_sw082_errorExp "Parking assist sensors: sw082 error exp";
CM_ SG_ 1486 PARK_sw082_errorRx "Parking assist sensors: sw082 error rx";
CM_ SG_ 1486 PARK_sw082_messageID "Parking assist sensors: sw082 message ID";
CM_ SG_ 1486 PARK_sw082_errorType "Parking assist sensors: sw082 error type";
CM_ SG_ 1486 PARK_sw083_errorExp "Parking assist sensors: sw083 error exp";
CM_ SG_ 1486 PARK_sw083_errorRx "Parking assist sensors: sw083 error rx";
CM_ SG_ 1486 PARK_sw083_messageID "Parking assist sensors: sw083 message ID";
CM_ SG_ 1486 PARK_sw083_errorType "Parking assist sensors: sw083 error type";
CM_ SG_ 1486 PARK_sw084_errorExp "Parking assist sensors: sw084 error exp";
CM_ SG_ 1486 PARK_sw084_errorRx "Parking assist sensors: sw084 error rx";
CM_ SG_ 1486 PARK_sw084_messageID "Parking assist sensors: sw084 message ID";
CM_ SG_ 1486 PARK_sw084_errorType "Parking assist sensors: sw084 error type";
CM_ SG_ 1486 PARK_sw086_writeRetryCounter "Parking assist sensors: sw086 write retry counter";
CM_ SG_ 1486 PARK_sw086_readRetryCounter "Parking assist sensors: sw086 read retry counter";
CM_ SG_ 1486 PARK_sw086_currentErrorCode "Parking assist sensors: sw086 current error code";
CM_ SG_ 1486 PARK_sw087_s1_sensorType "Parking assist sensors: sw087 s1 sensor type; raw 3 = signal not available (SNA)";
CM_ SG_ 1486 PARK_sw087_s2_sensorType "Parking assist sensors: sw087 s2 sensor type; raw 3 = signal not available (SNA)";
CM_ SG_ 1486 PARK_sw087_s3_sensorType "Parking assist sensors: sw087 s3 sensor type; raw 3 = signal not available (SNA)";
CM_ SG_ 1486 PARK_sw087_s4_sensorType "Parking assist sensors: sw087 s4 sensor type; raw 3 = signal not available (SNA)";
CM_ SG_ 1486 PARK_sw087_s5_sensorType "Parking assist sensors: sw087 s5 sensor type; raw 3 = signal not available (SNA)";
CM_ SG_ 1486 PARK_sw087_s6_sensorType "Parking assist sensors: sw087 s6 sensor type; raw 3 = signal not available (SNA)";
CM_ SG_ 1486 PARK_sw087_s7_sensorType "Parking assist sensors: sw087 s7 sensor type; raw 3 = signal not available (SNA)";
CM_ SG_ 1486 PARK_sw087_s8_sensorType "Parking assist sensors: sw087 s8 sensor type; raw 3 = signal not available (SNA)";
CM_ SG_ 1486 PARK_sw087_s9_sensorType "Parking assist sensors: sw087 s9 sensor type; raw 3 = signal not available (SNA)";
CM_ SG_ 1486 PARK_sw087_s10_sensorType "Parking assist sensors: sw087 s10 sensor type; raw 3 = signal not available (SNA)";
CM_ SG_ 1486 PARK_sw087_s11_sensorType "Parking assist sensors: sw087 s11 sensor type; raw 3 = signal not available (SNA)";
CM_ SG_ 1486 PARK_sw087_s12_sensorType "Parking assist sensors: sw087 s12 sensor type; raw 3 = signal not available (SNA)";
CM_ BO_ 806 "Parking assist sensors message: info";
CM_ SG_ 806 PARK_infoIndex "Parking assist sensors: info index";
CM_ SG_ 806 PARK_infoBuildType "Parking assist sensors: info build type";
CM_ SG_ 806 PARK_infoComponentID "Parking assist sensors: info component ID";
CM_ SG_ 806 PARK_infoPcbaID "Parking assist sensors: info pcba ID";
CM_ SG_ 806 PARK_infoAssemblyID "Parking assist sensors: info assembly ID";
CM_ SG_ 806 PARK_infoUsageID "Parking assist sensors: info usage ID";
CM_ SG_ 806 PARK_infoApplicationCRC "Parking assist sensors: info application CRC";
CM_ SG_ 806 PARK_infoBootUdsProtoVersion "Parking assist sensors: info boot uds proto version";
CM_ SG_ 806 PARK_infoBootloaderCRC "Parking assist sensors: info bootloader CRC";
CM_ BO_ 846 "Parking assist sensors message: pas front middle";
CM_ SG_ 846 PARK_frontLeftMiddleRawDistData "Zone defined as -38 degrees -> +12 degrees, distance to object in units of centimeters.; raw 255 = signal not available (SNA)";
CM_ SG_ 846 PARK_frontMiddleRawDistData "Zone defined as -12 degrees to +12 degrees, distance to object in units of centimeters.; raw 255 = signal not available (SNA)";
CM_ SG_ 846 PARK_frontRightMiddleRawDistData "Zone defined +12 degrees to +38 degreees, distance to object in units of centimeters.; raw 255 = signal not available (SNA)";
CM_ SG_ 846 PARK_pasFrontMiddleCounter "Parking assist sensors: pas front middle counter";
CM_ SG_ 846 PARK_pasFrontMiddleChecksum "Parking assist sensors: pas front middle checksum";
CM_ BO_ 862 "Parking assist sensors message: pas rear middle";
CM_ SG_ 862 PARK_rearLeftMiddleRawDistData "Zone defined as -124 degrees to -166 degrees, distance to object in units of centimeters.; raw 255 = signal not available (SNA)";
CM_ SG_ 862 PARK_rearMiddleRawDistData "Zone defined as -166 degrees to +166 degrees, distance to object in units of centimeters.; raw 255 = signal not available (SNA)";
CM_ SG_ 862 PARK_rearRightMiddleRawDistData "Zone defined as +166 degrees to +124 degrees, distance to object in units of centimeters.; raw 255 = signal not available (SNA)";
CM_ SG_ 862 PARK_pasRearMiddleCounter "Parking assist sensors: pas rear middle counter";
CM_ SG_ 862 PARK_pasRearMiddleChecksum "Parking assist sensors: pas rear middle checksum";
BA_DEF_ BO_ "GenMsgCycleTime" INT 0 3600000;
BA_DEF_ BO_ "GenMsgSendType" ENUM "Cyclic","NotUsed","NotUsed","NotUsed","NotUsed","NotUsed","NotUsed","IfActive","NoMsgSendType","NotUsed";
BA_DEF_ BO_ "VFrameFormat" ENUM "StandardCAN","ExtendedCAN","reserved","J1939PG","reserved","reserved","reserved","reserved","reserved","reserved","reserved","reserved","reserved","reserved","StandardCAN_FD","ExtendedCAN_FD";
BA_DEF_ BO_ "CANFD_BRS" ENUM "0","1";
BA_DEF_ SG_ "GenSigSNA" STRING;
BA_DEF_ SG_ "SystemSignalLongSymbol" STRING;
BA_DEF_ SG_ "Confidence" ENUM "validated","plausible","layout-only","contradicted";
BA_DEF_DEF_ "GenMsgCycleTime" 0;
BA_DEF_DEF_ "GenMsgSendType" "NoMsgSendType";
BA_DEF_DEF_ "VFrameFormat" "StandardCAN";
BA_DEF_DEF_ "CANFD_BRS" "1";
BA_DEF_DEF_ "GenSigSNA" "";
BA_DEF_DEF_ "SystemSignalLongSymbol" "";
BA_DEF_DEF_ "Confidence" "layout-only";
BA_ "GenMsgCycleTime" BO_ 983 1000;
BA_ "GenMsgSendType" BO_ 983 0;
BA_ "GenMsgCycleTime" BO_ 828 10000;
BA_ "GenMsgSendType" BO_ 828 0;
BA_ "GenMsgCycleTime" BO_ 767 100;
BA_ "GenMsgSendType" BO_ 767 0;
BA_ "GenMsgCycleTime" BO_ 766 1000;
BA_ "GenMsgSendType" BO_ 766 0;
BA_ "GenMsgCycleTime" BO_ 771 500;
BA_ "GenMsgSendType" BO_ 771 0;
BA_ "GenMsgCycleTime" BO_ 806 1000;
BA_ "GenMsgSendType" BO_ 806 0;
BA_ "GenMsgCycleTime" BO_ 846 100;
BA_ "GenMsgSendType" BO_ 846 0;
BA_ "GenMsgCycleTime" BO_ 862 100;
BA_ "GenMsgSendType" BO_ 862 0;
BA_ "Confidence" SG_ 1470 IDB_alertID 1;
BA_ "Confidence" SG_ 1470 IDB_alertState 1;
BA_ "Confidence" SG_ 1470 IDB_a014_wheelSpeedSensorFreq 1;
BA_ "Confidence" SG_ 1470 IDB_a014_wheelSpeedSensorPhase 1;
BA_ "Confidence" SG_ 1470 IDB_a014_wheelSpeedSensorMisinst 1;
BA_ "SystemSignalLongSymbol" SG_ 1470 IDB_a014_wheelSpeedSensorMisinst "IDB_a014_wheelSpeedSensorMisinstallation";
BA_ "Confidence" SG_ 1470 IDB_a014_wheelSpeedSensorWrongEx 1;
BA_ "SystemSignalLongSymbol" SG_ 1470 IDB_a014_wheelSpeedSensorWrongEx "IDB_a014_wheelSpeedSensorWrongExciter";
BA_ "Confidence" SG_ 1470 IDB_a014_wheelSpeedSensorSpeedJu 1;
BA_ "SystemSignalLongSymbol" SG_ 1470 IDB_a014_wheelSpeedSensorSpeedJu "IDB_a014_wheelSpeedSensorSpeedJumpMinus";
BA_ "Confidence" SG_ 1470 IDB_a014_wheelSpeedSensorSp_0001 1;
BA_ "SystemSignalLongSymbol" SG_ 1470 IDB_a014_wheelSpeedSensorSp_0001 "IDB_a014_wheelSpeedSensorSpeedJumpPlus";
BA_ "Confidence" SG_ 1470 IDB_a014_wheelSpeedSensorAirGap 1;
BA_ "Confidence" SG_ 1470 IDB_a014_wheelSpeedSensorBIST 1;
BA_ "Confidence" SG_ 1470 IDB_a014_wheelSpeedSensorLeakage 1;
BA_ "SystemSignalLongSymbol" SG_ 1470 IDB_a014_wheelSpeedSensorLeakage "IDB_a014_wheelSpeedSensorLeakageCur";
BA_ "Confidence" SG_ 1470 IDB_a014_wheelSpeedSensorOverTem 1;
BA_ "SystemSignalLongSymbol" SG_ 1470 IDB_a014_wheelSpeedSensorOverTem "IDB_a014_wheelSpeedSensorOverTemp";
BA_ "Confidence" SG_ 1470 IDB_a014_wheelSpeedSensorSh_0001 1;
BA_ "SystemSignalLongSymbol" SG_ 1470 IDB_a014_wheelSpeedSensorSh_0001 "IDB_a014_wheelSpeedSensorShortToGnd";
BA_ "Confidence" SG_ 1470 IDB_a014_wheelSpeedSensorShortTo 1;
BA_ "SystemSignalLongSymbol" SG_ 1470 IDB_a014_wheelSpeedSensorShortTo "IDB_a014_wheelSpeedSensorShortToBat";
BA_ "Confidence" SG_ 1470 IDB_a014_wheelSpeedSensorOpen 1;
BA_ "Confidence" SG_ 1470 IDB_a015_wheelSpeedSensorFreq 1;
BA_ "Confidence" SG_ 1470 IDB_a015_wheelSpeedSensorPhase 1;
BA_ "Confidence" SG_ 1470 IDB_a015_wheelSpeedSensorMisinst 1;
BA_ "SystemSignalLongSymbol" SG_ 1470 IDB_a015_wheelSpeedSensorMisinst "IDB_a015_wheelSpeedSensorMisinstallation";
BA_ "Confidence" SG_ 1470 IDB_a015_wheelSpeedSensorWrongEx 1;
BA_ "SystemSignalLongSymbol" SG_ 1470 IDB_a015_wheelSpeedSensorWrongEx "IDB_a015_wheelSpeedSensorWrongExciter";
BA_ "Confidence" SG_ 1470 IDB_a015_wheelSpeedSensorSpeedJu 1;
BA_ "SystemSignalLongSymbol" SG_ 1470 IDB_a015_wheelSpeedSensorSpeedJu "IDB_a015_wheelSpeedSensorSpeedJumpMinus";
BA_ "Confidence" SG_ 1470 IDB_a015_wheelSpeedSensorSp_0001 1;
BA_ "SystemSignalLongSymbol" SG_ 1470 IDB_a015_wheelSpeedSensorSp_0001 "IDB_a015_wheelSpeedSensorSpeedJumpPlus";
BA_ "Confidence" SG_ 1470 IDB_a015_wheelSpeedSensorAirGap 1;
BA_ "Confidence" SG_ 1470 IDB_a015_wheelSpeedSensorBIST 1;
BA_ "Confidence" SG_ 1470 IDB_a015_wheelSpeedSensorLeakage 1;
BA_ "SystemSignalLongSymbol" SG_ 1470 IDB_a015_wheelSpeedSensorLeakage "IDB_a015_wheelSpeedSensorLeakageCur";
BA_ "Confidence" SG_ 1470 IDB_a015_wheelSpeedSensorOverTem 1;
BA_ "SystemSignalLongSymbol" SG_ 1470 IDB_a015_wheelSpeedSensorOverTem "IDB_a015_wheelSpeedSensorOverTemp";
BA_ "Confidence" SG_ 1470 IDB_a015_wheelSpeedSensorSh_0001 1;
BA_ "SystemSignalLongSymbol" SG_ 1470 IDB_a015_wheelSpeedSensorSh_0001 "IDB_a015_wheelSpeedSensorShortToGnd";
BA_ "Confidence" SG_ 1470 IDB_a015_wheelSpeedSensorShortTo 1;
BA_ "SystemSignalLongSymbol" SG_ 1470 IDB_a015_wheelSpeedSensorShortTo "IDB_a015_wheelSpeedSensorShortToBat";
BA_ "Confidence" SG_ 1470 IDB_a015_wheelSpeedSensorOpen 1;
BA_ "Confidence" SG_ 1470 IDB_a016_wheelSpeedSensorFreq 1;
BA_ "Confidence" SG_ 1470 IDB_a016_wheelSpeedSensorPhase 1;
BA_ "Confidence" SG_ 1470 IDB_a016_wheelSpeedSensorMisinst 1;
BA_ "SystemSignalLongSymbol" SG_ 1470 IDB_a016_wheelSpeedSensorMisinst "IDB_a016_wheelSpeedSensorMisinstallation";
BA_ "Confidence" SG_ 1470 IDB_a016_wheelSpeedSensorWrongEx 1;
BA_ "SystemSignalLongSymbol" SG_ 1470 IDB_a016_wheelSpeedSensorWrongEx "IDB_a016_wheelSpeedSensorWrongExciter";
BA_ "Confidence" SG_ 1470 IDB_a016_wheelSpeedSensorSpeedJu 1;
BA_ "SystemSignalLongSymbol" SG_ 1470 IDB_a016_wheelSpeedSensorSpeedJu "IDB_a016_wheelSpeedSensorSpeedJumpMinus";
BA_ "Confidence" SG_ 1470 IDB_a016_wheelSpeedSensorSp_0001 1;
BA_ "SystemSignalLongSymbol" SG_ 1470 IDB_a016_wheelSpeedSensorSp_0001 "IDB_a016_wheelSpeedSensorSpeedJumpPlus";
BA_ "Confidence" SG_ 1470 IDB_a016_wheelSpeedSensorAirGap 1;
BA_ "Confidence" SG_ 1470 IDB_a016_wheelSpeedSensorBIST 1;
BA_ "Confidence" SG_ 1470 IDB_a016_wheelSpeedSensorLeakage 1;
BA_ "SystemSignalLongSymbol" SG_ 1470 IDB_a016_wheelSpeedSensorLeakage "IDB_a016_wheelSpeedSensorLeakageCur";
BA_ "Confidence" SG_ 1470 IDB_a016_wheelSpeedSensorOverTem 1;
BA_ "SystemSignalLongSymbol" SG_ 1470 IDB_a016_wheelSpeedSensorOverTem "IDB_a016_wheelSpeedSensorOverTemp";
BA_ "Confidence" SG_ 1470 IDB_a016_wheelSpeedSensorSh_0001 1;
BA_ "SystemSignalLongSymbol" SG_ 1470 IDB_a016_wheelSpeedSensorSh_0001 "IDB_a016_wheelSpeedSensorShortToGnd";
BA_ "Confidence" SG_ 1470 IDB_a016_wheelSpeedSensorShortTo 1;
BA_ "SystemSignalLongSymbol" SG_ 1470 IDB_a016_wheelSpeedSensorShortTo "IDB_a016_wheelSpeedSensorShortToBat";
BA_ "Confidence" SG_ 1470 IDB_a016_wheelSpeedSensorOpen 1;
BA_ "Confidence" SG_ 1470 IDB_a017_wheelSpeedSensorFreq 1;
BA_ "Confidence" SG_ 1470 IDB_a017_wheelSpeedSensorPhase 1;
BA_ "Confidence" SG_ 1470 IDB_a017_wheelSpeedSensorMisinst 1;
BA_ "SystemSignalLongSymbol" SG_ 1470 IDB_a017_wheelSpeedSensorMisinst "IDB_a017_wheelSpeedSensorMisinstallation";
BA_ "Confidence" SG_ 1470 IDB_a017_wheelSpeedSensorWrongEx 1;
BA_ "SystemSignalLongSymbol" SG_ 1470 IDB_a017_wheelSpeedSensorWrongEx "IDB_a017_wheelSpeedSensorWrongExciter";
BA_ "Confidence" SG_ 1470 IDB_a017_wheelSpeedSensorSpeedJu 1;
BA_ "SystemSignalLongSymbol" SG_ 1470 IDB_a017_wheelSpeedSensorSpeedJu "IDB_a017_wheelSpeedSensorSpeedJumpMinus";
BA_ "Confidence" SG_ 1470 IDB_a017_wheelSpeedSensorSp_0001 1;
BA_ "SystemSignalLongSymbol" SG_ 1470 IDB_a017_wheelSpeedSensorSp_0001 "IDB_a017_wheelSpeedSensorSpeedJumpPlus";
BA_ "Confidence" SG_ 1470 IDB_a017_wheelSpeedSensorAirGap 1;
BA_ "Confidence" SG_ 1470 IDB_a017_wheelSpeedSensorBIST 1;
BA_ "Confidence" SG_ 1470 IDB_a017_wheelSpeedSensorLeakage 1;
BA_ "SystemSignalLongSymbol" SG_ 1470 IDB_a017_wheelSpeedSensorLeakage "IDB_a017_wheelSpeedSensorLeakageCur";
BA_ "Confidence" SG_ 1470 IDB_a017_wheelSpeedSensorOverTem 1;
BA_ "SystemSignalLongSymbol" SG_ 1470 IDB_a017_wheelSpeedSensorOverTem "IDB_a017_wheelSpeedSensorOverTemp";
BA_ "Confidence" SG_ 1470 IDB_a017_wheelSpeedSensorSh_0001 1;
BA_ "SystemSignalLongSymbol" SG_ 1470 IDB_a017_wheelSpeedSensorSh_0001 "IDB_a017_wheelSpeedSensorShortToGnd";
BA_ "Confidence" SG_ 1470 IDB_a017_wheelSpeedSensorShortTo 1;
BA_ "SystemSignalLongSymbol" SG_ 1470 IDB_a017_wheelSpeedSensorShortTo "IDB_a017_wheelSpeedSensorShortToBat";
BA_ "Confidence" SG_ 1470 IDB_a017_wheelSpeedSensorOpen 1;
BA_ "Confidence" SG_ 1470 IDB_a020_canSignalValidity 1;
BA_ "Confidence" SG_ 1470 IDB_a020_signalValueCrosscheck 1;
BA_ "Confidence" SG_ 1470 IDB_a030_primaryExternalCircuitL 1;
BA_ "SystemSignalLongSymbol" SG_ 1470 IDB_a030_primaryExternalCircuitL "IDB_a030_primaryExternalCircuitLeakage";
BA_ "Confidence" SG_ 1470 IDB_a030_secondaryExternalCircui 1;
BA_ "SystemSignalLongSymbol" SG_ 1470 IDB_a030_secondaryExternalCircui "IDB_a030_secondaryExternalCircuitLeakage";
BA_ "Confidence" SG_ 1470 IDB_a030_primaryChamberInternalL 1;
BA_ "SystemSignalLongSymbol" SG_ 1470 IDB_a030_primaryChamberInternalL "IDB_a030_primaryChamberInternalLeakage";
BA_ "Confidence" SG_ 1470 IDB_a030_syncModeInternalLeakage 1;
BA_ "Confidence" SG_ 1470 IDB_a030_secondaryChamberInterna 1;
BA_ "SystemSignalLongSymbol" SG_ 1470 IDB_a030_secondaryChamberInterna "IDB_a030_secondaryChamberInternalLeakage";
BA_ "Confidence" SG_ 1470 IDB_a030_masterCylinderInternalL 1;
BA_ "SystemSignalLongSymbol" SG_ 1470 IDB_a030_masterCylinderInternalL "IDB_a030_masterCylinderInternalLeakage";
BA_ "Confidence" SG_ 1470 IDB_a060_validityOnChassisBus 1;
BA_ "Confidence" SG_ 1470 IDB_a060_validityOnPartyBus 1;
BA_ "Confidence" SG_ 1470 IDB_a061_validityOnChassisBus 1;
BA_ "Confidence" SG_ 1470 IDB_a061_validityOnPartyBus 1;
BA_ "Confidence" SG_ 1470 IDB_a063_validityOnChassisBus 1;
BA_ "Confidence" SG_ 1470 IDB_a063_validityOnPartyBus 1;
BA_ "Confidence" SG_ 1470 IDB_a064_validityOnChassisBus 1;
BA_ "Confidence" SG_ 1470 IDB_a064_validityOnPartyBus 1;
BA_ "Confidence" SG_ 1470 IDB_a065_validityOnChassisBus 1;
BA_ "Confidence" SG_ 1470 IDB_a065_validityOnPartyBus 1;
BA_ "Confidence" SG_ 1470 IDB_a106_qualifierValidity 1;
BA_ "Confidence" SG_ 1470 IDB_a106_signalNotAvailable 1;
BA_ "Confidence" SG_ 1470 IDB_a107_qualifierValidity 1;
BA_ "Confidence" SG_ 1470 IDB_a107_signalNotAvailable 1;
BA_ "Confidence" SG_ 1470 IDB_a112_qualifierValidity 1;
BA_ "Confidence" SG_ 1470 IDB_a112_signalNotAvailable 1;
BA_ "Confidence" SG_ 1470 IDB_a113_qualifierValidity 1;
BA_ "Confidence" SG_ 1470 IDB_a113_signalNotAvailable 1;
BA_ "Confidence" SG_ 1470 IDB_a114_qualifierValidity 1;
BA_ "Confidence" SG_ 1470 IDB_a114_signalNotAvailable 1;
BA_ "Confidence" SG_ 1470 IDB_a126_PMebrCmdStateValidity 1;
BA_ "Confidence" SG_ 1470 IDB_a126_PMstate2Validity 1;
BA_ "Confidence" SG_ 1470 IDB_a126_PMstate2Missing 1;
BA_ "Confidence" SG_ 1470 IDB_a126_DIchassisControlValidit 1;
BA_ "SystemSignalLongSymbol" SG_ 1470 IDB_a126_DIchassisControlValidit "IDB_a126_DIchassisControlValidity";
BA_ "Confidence" SG_ 1470 IDB_a126_DIchassisControlMissing 1;
BA_ "Confidence" SG_ 1470 IDB_a126_DIrequestActiveValidity 1;
BA_ "Confidence" SG_ 1470 IDB_a129_validityOnChassisBus 1;
BA_ "Confidence" SG_ 1470 IDB_a129_validityOnPartyBus 1;
BA_ "Confidence" SG_ 1470 IDB_a130_PMbrakePedalCmdQFValidi 1;
BA_ "SystemSignalLongSymbol" SG_ 1470 IDB_a130_PMbrakePedalCmdQFValidi "IDB_a130_PMbrakePedalCmdQFValidity";
BA_ "Confidence" SG_ 1470 IDB_a130_PMstate2Validity 1;
BA_ "Confidence" SG_ 1470 IDB_a130_PMstate2Missing 1;
BA_ "Confidence" SG_ 1470 IDB_a130_DIbrakeCommandValidity 1;
BA_ "Confidence" SG_ 1470 IDB_a130_DIbrakeCommandMissing 1;
BA_ "Confidence" SG_ 1470 IDB_a130_DIbrakeTorqueCommandFul 1;
BA_ "SystemSignalLongSymbol" SG_ 1470 IDB_a130_DIbrakeTorqueCommandFul "IDB_a130_DIbrakeTorqueCommandFullSNA";
BA_ "Confidence" SG_ 1470 IDB_a130_DIbrakeTorqueComma_0001 1;
BA_ "SystemSignalLongSymbol" SG_ 1470 IDB_a130_DIbrakeTorqueComma_0001 "IDB_a130_DIbrakeTorqueCommandFullTooLow";
BA_ "Confidence" SG_ 1470 IDB_a132_validityOnChassisBus 1;
BA_ "Confidence" SG_ 1470 IDB_a132_validityOnPartyBus 1;
BA_ "Confidence" SG_ 983 IDB_matrixIndex 1;
BA_ "SystemSignalLongSymbol" SG_ 983 IDB_a070_DIchassisControlChecksu "IDB_a070_DIchassisControlChecksum";
BA_ "SystemSignalLongSymbol" SG_ 983 IDB_a119_VCLEFTepbmStatusChecksu "IDB_a119_VCLEFTepbmStatusChecksum";
BA_ "SystemSignalLongSymbol" SG_ 983 IDB_a129_RCUinputRodStrokeInvali "IDB_a129_RCUinputRodStrokeInvalid";
BA_ "SystemSignalLongSymbol" SG_ 983 IDB_a130_DIfullTorqueRequestInva "IDB_a130_DIfullTorqueRequestInvalid";
BA_ "SystemSignalLongSymbol" SG_ 983 IDB_a132_RCUinputRodStrokeQFInva "IDB_a132_RCUinputRodStrokeQFInvalid";
BA_ "SystemSignalLongSymbol" SG_ 983 IDB_a138_DIbrakeTorqueCommandAnd "IDB_a138_DIbrakeTorqueCommandAndFlagMismatch";
BA_ "SystemSignalLongSymbol" SG_ 983 IDB_a139_DIbrakeTorqueCommandFul "IDB_a139_DIbrakeTorqueCommandFullSNA";
BA_ "SystemSignalLongSymbol" SG_ 983 IDB_a140_PMbrakePedalCmdQFInvali "IDB_a140_PMbrakePedalCmdQFInvalid";
BA_ "SystemSignalLongSymbol" SG_ 983 IDB_a141_DIbrakeTorqueCommandFul "IDB_a141_DIbrakeTorqueCommandFullTooLow";
BA_ "SystemSignalLongSymbol" SG_ 983 IDB_a144_hydraulicPushthroughAct "IDB_a144_hydraulicPushthroughActive";
BA_ "SystemSignalLongSymbol" SG_ 983 IDB_a145_DASredundantBrakingCont "IDB_a145_DASredundantBrakingControlDLC";
BA_ "SystemSignalLongSymbol" SG_ 983 IDB_a146_DASredundantBrakingCont "IDB_a146_DASredundantBrakingControlCounter";
BA_ "SystemSignalLongSymbol" SG_ 983 IDB_a147_DASredundantBrakingCont "IDB_a147_DASredundantBrakingControlChecksum";
BA_ "SystemSignalLongSymbol" SG_ 983 IDB_a148_DASbrakeTorqueCommandIn "IDB_a148_DASbrakeTorqueCommandInvalid";
BA_ "SystemSignalLongSymbol" SG_ 983 IDB_a149_DASmiaBrakeTorqueComman "IDB_a149_DASmiaBrakeTorqueCommandInvalid";
BA_ "Confidence" SG_ 828 IDB_infoIndex 1;
BA_ "Confidence" SG_ 828 IDB_infoPcbaID 0;
BA_ "Confidence" SG_ 828 IDB_infoAssemblyID 0;
BA_ "Confidence" SG_ 828 IDB_infoUsageID 0;
BA_ "Confidence" SG_ 828 IDB_infoSubUsageID 0;
BA_ "Confidence" SG_ 1012 LS_lightShowIndex 1;
BA_ "Confidence" SG_ 1012 LS_lightLeftRampedChannel1Reques 0;
BA_ "SystemSignalLongSymbol" SG_ 1012 LS_lightLeftRampedChannel1Reques "LS_lightLeftRampedChannel1Request";
BA_ "Confidence" SG_ 1012 LS_lightLeftRampedChannel1Durati 0;
BA_ "SystemSignalLongSymbol" SG_ 1012 LS_lightLeftRampedChannel1Durati "LS_lightLeftRampedChannel1Duration";
BA_ "Confidence" SG_ 1012 LS_lightLeftRampedChannel2Reques 0;
BA_ "SystemSignalLongSymbol" SG_ 1012 LS_lightLeftRampedChannel2Reques "LS_lightLeftRampedChannel2Request";
BA_ "Confidence" SG_ 1012 LS_lightLeftRampedChannel2Durati 0;
BA_ "SystemSignalLongSymbol" SG_ 1012 LS_lightLeftRampedChannel2Durati "LS_lightLeftRampedChannel2Duration";
BA_ "Confidence" SG_ 1012 LS_lightLeftRampedChannel3Reques 0;
BA_ "SystemSignalLongSymbol" SG_ 1012 LS_lightLeftRampedChannel3Reques "LS_lightLeftRampedChannel3Request";
BA_ "Confidence" SG_ 1012 LS_lightLeftRampedChannel3Durati 0;
BA_ "SystemSignalLongSymbol" SG_ 1012 LS_lightLeftRampedChannel3Durati "LS_lightLeftRampedChannel3Duration";
BA_ "Confidence" SG_ 1012 LS_lightLeftRampedChannel4Reques 0;
BA_ "SystemSignalLongSymbol" SG_ 1012 LS_lightLeftRampedChannel4Reques "LS_lightLeftRampedChannel4Request";
BA_ "Confidence" SG_ 1012 LS_lightLeftRampedChannel4Durati 0;
BA_ "SystemSignalLongSymbol" SG_ 1012 LS_lightLeftRampedChannel4Durati "LS_lightLeftRampedChannel4Duration";
BA_ "Confidence" SG_ 1012 LS_lightLeftRampedChannel5Reques 0;
BA_ "SystemSignalLongSymbol" SG_ 1012 LS_lightLeftRampedChannel5Reques "LS_lightLeftRampedChannel5Request";
BA_ "Confidence" SG_ 1012 LS_lightLeftRampedChannel5Durati 0;
BA_ "SystemSignalLongSymbol" SG_ 1012 LS_lightLeftRampedChannel5Durati "LS_lightLeftRampedChannel5Duration";
BA_ "Confidence" SG_ 1012 LS_lightLeftRampedChannel6Reques 0;
BA_ "SystemSignalLongSymbol" SG_ 1012 LS_lightLeftRampedChannel6Reques "LS_lightLeftRampedChannel6Request";
BA_ "Confidence" SG_ 1012 LS_lightLeftRampedChannel6Durati 0;
BA_ "SystemSignalLongSymbol" SG_ 1012 LS_lightLeftRampedChannel6Durati "LS_lightLeftRampedChannel6Duration";
BA_ "Confidence" SG_ 1012 LS_lightLeftRampedChannel7Reques 0;
BA_ "SystemSignalLongSymbol" SG_ 1012 LS_lightLeftRampedChannel7Reques "LS_lightLeftRampedChannel7Request";
BA_ "Confidence" SG_ 1012 LS_lightLeftRampedChannel7Durati 0;
BA_ "SystemSignalLongSymbol" SG_ 1012 LS_lightLeftRampedChannel7Durati "LS_lightLeftRampedChannel7Duration";
BA_ "Confidence" SG_ 1012 LS_lightRightRampedChannel1Reque 0;
BA_ "SystemSignalLongSymbol" SG_ 1012 LS_lightRightRampedChannel1Reque "LS_lightRightRampedChannel1Request";
BA_ "Confidence" SG_ 1012 LS_lightRightRampedChannel1Durat 0;
BA_ "GenSigSNA" SG_ 1012 LS_lightRightRampedChannel1Durat "1";
BA_ "SystemSignalLongSymbol" SG_ 1012 LS_lightRightRampedChannel1Durat "LS_lightRightRampedChannel1Duration";
BA_ "Confidence" SG_ 1012 LS_lightRightRampedChannel2Reque 0;
BA_ "SystemSignalLongSymbol" SG_ 1012 LS_lightRightRampedChannel2Reque "LS_lightRightRampedChannel2Request";
BA_ "Confidence" SG_ 1012 LS_lightRightRampedChannel2Durat 0;
BA_ "GenSigSNA" SG_ 1012 LS_lightRightRampedChannel2Durat "1";
BA_ "SystemSignalLongSymbol" SG_ 1012 LS_lightRightRampedChannel2Durat "LS_lightRightRampedChannel2Duration";
BA_ "Confidence" SG_ 1012 LS_lightRightRampedChannel3Reque 0;
BA_ "SystemSignalLongSymbol" SG_ 1012 LS_lightRightRampedChannel3Reque "LS_lightRightRampedChannel3Request";
BA_ "Confidence" SG_ 1012 LS_lightRightRampedChannel3Durat 0;
BA_ "SystemSignalLongSymbol" SG_ 1012 LS_lightRightRampedChannel3Durat "LS_lightRightRampedChannel3Duration";
BA_ "Confidence" SG_ 1012 LS_lightRightRampedChannel4Reque 0;
BA_ "SystemSignalLongSymbol" SG_ 1012 LS_lightRightRampedChannel4Reque "LS_lightRightRampedChannel4Request";
BA_ "Confidence" SG_ 1012 LS_lightRightRampedChannel4Durat 0;
BA_ "SystemSignalLongSymbol" SG_ 1012 LS_lightRightRampedChannel4Durat "LS_lightRightRampedChannel4Duration";
BA_ "Confidence" SG_ 1012 LS_lightRightRampedChannel5Reque 0;
BA_ "SystemSignalLongSymbol" SG_ 1012 LS_lightRightRampedChannel5Reque "LS_lightRightRampedChannel5Request";
BA_ "Confidence" SG_ 1012 LS_lightRightRampedChannel5Durat 0;
BA_ "SystemSignalLongSymbol" SG_ 1012 LS_lightRightRampedChannel5Durat "LS_lightRightRampedChannel5Duration";
BA_ "Confidence" SG_ 1012 LS_lightRightRampedChannel6Reque 0;
BA_ "SystemSignalLongSymbol" SG_ 1012 LS_lightRightRampedChannel6Reque "LS_lightRightRampedChannel6Request";
BA_ "Confidence" SG_ 1012 LS_lightRightRampedChannel6Durat 0;
BA_ "SystemSignalLongSymbol" SG_ 1012 LS_lightRightRampedChannel6Durat "LS_lightRightRampedChannel6Duration";
BA_ "Confidence" SG_ 1012 LS_lightRightRampedChannel7Reque 0;
BA_ "SystemSignalLongSymbol" SG_ 1012 LS_lightRightRampedChannel7Reque "LS_lightRightRampedChannel7Request";
BA_ "Confidence" SG_ 1012 LS_lightRightRampedChannel7Durat 0;
BA_ "SystemSignalLongSymbol" SG_ 1012 LS_lightRightRampedChannel7Durat "LS_lightRightRampedChannel7Duration";
BA_ "Confidence" SG_ 1012 LS_lightRearTurnLeftRequest 0;
BA_ "Confidence" SG_ 1012 LS_lightRearTurnRightRequest 0;
BA_ "Confidence" SG_ 1012 LS_lightSideRepeaterLeftRequest 0;
BA_ "Confidence" SG_ 1012 LS_lightSideRepeaterRightRequest 0;
BA_ "Confidence" SG_ 1012 LS_lightSideMarkerLeftRequest 0;
BA_ "Confidence" SG_ 1012 LS_lightSideMarkerRightRequest 0;
BA_ "Confidence" SG_ 1012 LS_lightFrontFogLeftRequest 0;
BA_ "Confidence" SG_ 1012 LS_lightFrontFogRightRequest 0;
BA_ "Confidence" SG_ 1012 LS_lightRearFogRequest 0;
BA_ "Confidence" SG_ 1012 LS_lightBrakeRequest 0;
BA_ "Confidence" SG_ 1012 LS_lightTailLeftRequest 0;
BA_ "Confidence" SG_ 1012 LS_lightTailRightRequest 0;
BA_ "Confidence" SG_ 1012 LS_lightLicensePlateRequest 0;
BA_ "Confidence" SG_ 1012 LS_lightReverseRequest 0;
BA_ "Confidence" SG_ 1012 LS_lightAuxParkLeftRequest 0;
BA_ "Confidence" SG_ 1012 LS_lightAuxParkRightRequest 0;
BA_ "Confidence" SG_ 1012 LS_mirrorRequestLeft 0;
BA_ "Confidence" SG_ 1012 LS_mirrorRequestRight 0;
BA_ "Confidence" SG_ 1012 LS_liftgateRequest 0;
BA_ "Confidence" SG_ 1012 LS_windowRequestLF 0;
BA_ "Confidence" SG_ 1012 LS_windowRequestLR 0;
BA_ "Confidence" SG_ 1012 LS_windowRequestRF 0;
BA_ "Confidence" SG_ 1012 LS_windowRequestRR 0;
BA_ "Confidence" SG_ 1012 LS_presentingHandleRequestLF 0;
BA_ "Confidence" SG_ 1012 LS_presentingHandleRequestLR 0;
BA_ "Confidence" SG_ 1012 LS_presentingHandleRequestRF 0;
BA_ "Confidence" SG_ 1012 LS_presentingHandleRequestRR 0;
BA_ "Confidence" SG_ 1012 LS_powerFrontDoorRequestLeft 0;
BA_ "Confidence" SG_ 1012 LS_powerFrontDoorRequestRight 0;
BA_ "Confidence" SG_ 1012 LS_falconDoorRequestLeft 0;
BA_ "Confidence" SG_ 1012 LS_falconDoorRequestRight 0;
BA_ "Confidence" SG_ 1012 LS_chargePortRequest 0;
BA_ "GenSigSNA" SG_ 1012 LS_chargePortRequest "3";
BA_ "Confidence" SG_ 1012 LS_chargePortRaveRequest 0;
BA_ "Confidence" SG_ 1012 LS_suspensionRequest 0;
BA_ "GenSigSNA" SG_ 1012 LS_suspensionRequest "3";
BA_ "Confidence" SG_ 1012 LS_rgbIPFLRed 0;
BA_ "Confidence" SG_ 1012 LS_rgbIPFLGreen 0;
BA_ "Confidence" SG_ 1012 LS_rgbIPFLBlue 0;
BA_ "Confidence" SG_ 1012 LS_rgbIPFRRed 0;
BA_ "Confidence" SG_ 1012 LS_rgbIPFRGreen 0;
BA_ "Confidence" SG_ 1012 LS_rgbIPFRBlue 0;
BA_ "Confidence" SG_ 1012 LS_rgbDoorFLForeRed 0;
BA_ "Confidence" SG_ 1012 LS_rgbDoorFLForeGreen 0;
BA_ "Confidence" SG_ 1012 LS_rgbDoorFLForeBlue 0;
BA_ "Confidence" SG_ 1012 LS_rgbDoorFLAftRed 0;
BA_ "Confidence" SG_ 1012 LS_rgbDoorFLAftGreen 0;
BA_ "Confidence" SG_ 1012 LS_rgbDoorFLAftBlue 0;
BA_ "Confidence" SG_ 1012 LS_rgbDoorFRForeRed 0;
BA_ "Confidence" SG_ 1012 LS_rgbDoorFRForeGreen 0;
BA_ "Confidence" SG_ 1012 LS_rgbDoorFRForeBlue 0;
BA_ "Confidence" SG_ 1012 LS_rgbDoorFRAftRed 0;
BA_ "Confidence" SG_ 1012 LS_rgbDoorFRAftGreen 0;
BA_ "Confidence" SG_ 1012 LS_rgbDoorFRAftBlue 0;
BA_ "Confidence" SG_ 1012 LS_rgbDoorRLForeRed 0;
BA_ "Confidence" SG_ 1012 LS_rgbDoorRLForeGreen 0;
BA_ "Confidence" SG_ 1012 LS_rgbDoorRLForeBlue 0;
BA_ "Confidence" SG_ 1012 LS_rgbDoorRLAftRed 0;
BA_ "Confidence" SG_ 1012 LS_rgbDoorRLAftGreen 0;
BA_ "Confidence" SG_ 1012 LS_rgbDoorRLAftBlue 0;
BA_ "Confidence" SG_ 1012 LS_rgbDoorRRForeRed 0;
BA_ "Confidence" SG_ 1012 LS_rgbDoorRRForeGreen 0;
BA_ "Confidence" SG_ 1012 LS_rgbDoorRRForeBlue 0;
BA_ "Confidence" SG_ 1012 LS_rgbDoorRRAftRed 0;
BA_ "Confidence" SG_ 1012 LS_rgbDoorRRAftGreen 0;
BA_ "Confidence" SG_ 1012 LS_rgbDoorRRAftBlue 0;
BA_ "Confidence" SG_ 1012 LS_frontMatrix0 0;
BA_ "Confidence" SG_ 1012 LS_frontMatrix1 0;
BA_ "Confidence" SG_ 1012 LS_frontMatrix2 0;
BA_ "Confidence" SG_ 1012 LS_frontMatrix3 0;
BA_ "Confidence" SG_ 1012 LS_frontMatrix4 0;
BA_ "Confidence" SG_ 1012 LS_frontMatrix5 0;
BA_ "Confidence" SG_ 1012 LS_frontMatrix6 0;
BA_ "Confidence" SG_ 1012 LS_frontMatrix7 0;
BA_ "Confidence" SG_ 1012 LS_frontMatrix8 0;
BA_ "Confidence" SG_ 1012 LS_frontMatrix9 0;
BA_ "Confidence" SG_ 1012 LS_frontMatrix10 0;
BA_ "Confidence" SG_ 1012 LS_frontMatrix11 0;
BA_ "Confidence" SG_ 1012 LS_frontMatrix12 0;
BA_ "Confidence" SG_ 1012 LS_frontMatrix13 0;
BA_ "Confidence" SG_ 1012 LS_frontMatrix14 0;
BA_ "Confidence" SG_ 1012 LS_frontMatrix15 0;
BA_ "Confidence" SG_ 1012 LS_frontMatrix16 0;
BA_ "Confidence" SG_ 1012 LS_frontMatrix17 0;
BA_ "Confidence" SG_ 1012 LS_frontMatrix18 0;
BA_ "Confidence" SG_ 1012 LS_frontMatrix19 0;
BA_ "Confidence" SG_ 1012 LS_frontMatrix20 0;
BA_ "Confidence" SG_ 1012 LS_frontMatrix21 0;
BA_ "Confidence" SG_ 1012 LS_frontMatrix22 0;
BA_ "Confidence" SG_ 1012 LS_frontMatrix23 0;
BA_ "Confidence" SG_ 1012 LS_frontMatrix24 0;
BA_ "Confidence" SG_ 1012 LS_frontMatrix25 0;
BA_ "Confidence" SG_ 1012 LS_frontMatrix26 0;
BA_ "Confidence" SG_ 1012 LS_frontMatrix27 0;
BA_ "Confidence" SG_ 1012 LS_frontMatrix28 0;
BA_ "Confidence" SG_ 1012 LS_frontMatrix29 0;
BA_ "Confidence" SG_ 1012 LS_frontMatrix30 0;
BA_ "Confidence" SG_ 1012 LS_frontMatrix31 0;
BA_ "Confidence" SG_ 1012 LS_frontMatrix32 0;
BA_ "Confidence" SG_ 1012 LS_frontMatrix33 0;
BA_ "Confidence" SG_ 1012 LS_frontMatrix34 0;
BA_ "Confidence" SG_ 1012 LS_frontMatrix35 0;
BA_ "Confidence" SG_ 1012 LS_frontMatrix36 0;
BA_ "Confidence" SG_ 1012 LS_frontMatrix37 0;
BA_ "Confidence" SG_ 1012 LS_frontMatrix38 0;
BA_ "Confidence" SG_ 1012 LS_frontMatrix39 0;
BA_ "Confidence" SG_ 1012 LS_frontMatrix40 0;
BA_ "Confidence" SG_ 1012 LS_frontMatrix41 0;
BA_ "Confidence" SG_ 1012 LS_frontMatrix42 0;
BA_ "Confidence" SG_ 1012 LS_frontMatrix43 0;
BA_ "Confidence" SG_ 1012 LS_frontMatrix44 0;
BA_ "Confidence" SG_ 1012 LS_frontMatrix45 0;
BA_ "Confidence" SG_ 1012 LS_frontMatrix46 0;
BA_ "Confidence" SG_ 1012 LS_frontMatrix47 0;
BA_ "Confidence" SG_ 1012 LS_frontMatrix48 0;
BA_ "Confidence" SG_ 1012 LS_frontMatrix49 0;
BA_ "Confidence" SG_ 1012 LS_frontMatrix50 0;
BA_ "Confidence" SG_ 1012 LS_frontMatrix51 0;
BA_ "Confidence" SG_ 1012 LS_frontMatrix52 0;
BA_ "Confidence" SG_ 1012 LS_frontMatrix53 0;
BA_ "Confidence" SG_ 1012 LS_frontMatrix54 0;
BA_ "Confidence" SG_ 1012 LS_frontMatrix55 0;
BA_ "Confidence" SG_ 1012 LS_frontMatrix56 0;
BA_ "Confidence" SG_ 1012 LS_frontMatrix57 0;
BA_ "Confidence" SG_ 1012 LS_frontMatrix58 0;
BA_ "Confidence" SG_ 1012 LS_frontMatrix59 0;
BA_ "Confidence" SG_ 1012 LS_rearMatrix0 0;
BA_ "Confidence" SG_ 1012 LS_rearMatrix1 0;
BA_ "Confidence" SG_ 1012 LS_rearMatrix2 0;
BA_ "Confidence" SG_ 1012 LS_rearMatrix3 0;
BA_ "Confidence" SG_ 1012 LS_rearMatrix4 0;
BA_ "Confidence" SG_ 1012 LS_rearMatrix5 0;
BA_ "Confidence" SG_ 1012 LS_rearMatrix6 0;
BA_ "Confidence" SG_ 1012 LS_rearMatrix7 0;
BA_ "Confidence" SG_ 1012 LS_rearMatrix8 0;
BA_ "Confidence" SG_ 1012 LS_rearMatrix9 0;
BA_ "Confidence" SG_ 1012 LS_rearMatrix10 0;
BA_ "Confidence" SG_ 1012 LS_rearMatrix11 0;
BA_ "Confidence" SG_ 1012 LS_rearMatrix12 0;
BA_ "Confidence" SG_ 1012 LS_rearMatrix13 0;
BA_ "Confidence" SG_ 1012 LS_rearMatrix14 0;
BA_ "Confidence" SG_ 1012 LS_rearMatrix15 0;
BA_ "Confidence" SG_ 1012 LS_rearMatrix16 0;
BA_ "Confidence" SG_ 1012 LS_rearMatrix17 0;
BA_ "Confidence" SG_ 1012 LS_rearMatrix18 0;
BA_ "Confidence" SG_ 1012 LS_rearMatrix19 0;
BA_ "Confidence" SG_ 1012 LS_rearMatrix20 0;
BA_ "Confidence" SG_ 1012 LS_rearMatrix21 0;
BA_ "Confidence" SG_ 1012 LS_rearMatrix22 0;
BA_ "Confidence" SG_ 1012 LS_rearMatrix23 0;
BA_ "Confidence" SG_ 1012 LS_rearMatrix24 0;
BA_ "Confidence" SG_ 1012 LS_rearMatrix25 0;
BA_ "Confidence" SG_ 1012 LS_rearMatrix26 0;
BA_ "Confidence" SG_ 1012 LS_rearMatrix27 0;
BA_ "Confidence" SG_ 1012 LS_rearMatrix28 0;
BA_ "Confidence" SG_ 1012 LS_rearMatrix29 0;
BA_ "Confidence" SG_ 1012 LS_rearMatrix30 0;
BA_ "Confidence" SG_ 1012 LS_rearMatrix31 0;
BA_ "Confidence" SG_ 1012 LS_rearMatrix32 0;
BA_ "Confidence" SG_ 1012 LS_rearMatrix33 0;
BA_ "Confidence" SG_ 1012 LS_rearMatrix34 0;
BA_ "Confidence" SG_ 1012 LS_rearMatrix35 0;
BA_ "Confidence" SG_ 1012 LS_rearMatrix36 0;
BA_ "Confidence" SG_ 1012 LS_rearMatrix37 0;
BA_ "Confidence" SG_ 1012 LS_rearMatrix38 0;
BA_ "Confidence" SG_ 1012 LS_rearMatrix39 0;
BA_ "Confidence" SG_ 1012 LS_rearMatrix40 0;
BA_ "Confidence" SG_ 1012 LS_rearMatrix41 0;
BA_ "Confidence" SG_ 1012 LS_rearMatrix42 0;
BA_ "Confidence" SG_ 1012 LS_rearMatrix43 0;
BA_ "Confidence" SG_ 1012 LS_rearMatrix44 0;
BA_ "Confidence" SG_ 1012 LS_rearMatrix45 0;
BA_ "Confidence" SG_ 1012 LS_rearMatrix46 0;
BA_ "Confidence" SG_ 1012 LS_rearMatrix47 0;
BA_ "Confidence" SG_ 1012 LS_rearMatrix48 0;
BA_ "Confidence" SG_ 1012 LS_rearMatrix49 0;
BA_ "Confidence" SG_ 1012 LS_rearMatrix50 0;
BA_ "Confidence" SG_ 1012 LS_rearMatrix51 0;
BA_ "Confidence" SG_ 1012 LS_rearMatrix52 0;
BA_ "Confidence" SG_ 1012 LS_rearMatrix53 0;
BA_ "Confidence" SG_ 1012 LS_rearMatrix54 0;
BA_ "Confidence" SG_ 1012 LS_rearMatrix55 0;
BA_ "Confidence" SG_ 1012 LS_rearMatrix56 0;
BA_ "Confidence" SG_ 1012 LS_rearMatrix57 0;
BA_ "Confidence" SG_ 1012 LS_rearMatrix58 0;
BA_ "Confidence" SG_ 1012 LS_rearMatrix59 0;
BA_ "Confidence" SG_ 1012 LS_offroadLightBar0 0;
BA_ "Confidence" SG_ 1012 LS_offroadLightBar1 0;
BA_ "Confidence" SG_ 1012 LS_offroadLightBar2 0;
BA_ "Confidence" SG_ 1012 LS_offroadLightBar3 0;
BA_ "Confidence" SG_ 1012 LS_offroadLightBar4 0;
BA_ "Confidence" SG_ 1012 LS_offroadLightBar5 0;
BA_ "Confidence" SG_ 1429 OCS1P_alertID 1;
BA_ "Confidence" SG_ 1429 OCS1P_alertState 1;
BA_ "Confidence" SG_ 767 OCS1P_matrixIndex 1;
BA_ "SystemSignalLongSymbol" SG_ 767 OCS1P_w148_classificationMismatc "OCS1P_w148_classificationMismatch";
BA_ "SystemSignalLongSymbol" SG_ 767 OCS1P_w156_seatbeltReminderUnava "OCS1P_w156_seatbeltReminderUnavailable";
BA_ "Confidence" SG_ 766 OCS1P_infoIndex 1;
BA_ "Confidence" SG_ 766 OCS1P_infoBuildType 0;
BA_ "Confidence" SG_ 766 OCS1P_infoBuildConfigID 0;
BA_ "Confidence" SG_ 766 OCS1P_infoHardwareID 0;
BA_ "Confidence" SG_ 766 OCS1P_infoComponentID 0;
BA_ "Confidence" SG_ 766 OCS1P_infoPcbaID 0;
BA_ "Confidence" SG_ 766 OCS1P_infoAssemblyID 0;
BA_ "Confidence" SG_ 766 OCS1P_infoUsageID 0;
BA_ "Confidence" SG_ 766 OCS1P_infoSubUsageID 0;
BA_ "Confidence" SG_ 766 OCS1P_infoApplicationCRC 0;
BA_ "Confidence" SG_ 766 OCS1P_infoBootSvnRev 0;
BA_ "Confidence" SG_ 766 OCS1P_infoAppGitHashBytes 0;
BA_ "Confidence" SG_ 766 OCS1P_infoBootGitHashBytes 0;
BA_ "Confidence" SG_ 766 OCS1P_infoPlatformType 0;
BA_ "Confidence" SG_ 766 OCS1P_infoBootUdsProtoVersion 0;
BA_ "Confidence" SG_ 766 OCS1P_infoBootloaderCRC 0;
BA_ "Confidence" SG_ 771 OCS1P_occupantClassification 0;
BA_ "GenSigSNA" SG_ 771 OCS1P_occupantClassification "255";
BA_ "Confidence" SG_ 771 OCS1P_occupantClassificationQF 0;
BA_ "Confidence" SG_ 771 OCS1P_occupiedState 0;
BA_ "GenSigSNA" SG_ 771 OCS1P_occupiedState "3";
BA_ "Confidence" SG_ 771 OCS1P_triggerSnapshot 0;
BA_ "Confidence" SG_ 771 OCS1P_occupantClassificationRaw 0;
BA_ "GenSigSNA" SG_ 771 OCS1P_occupantClassificationRaw "7";
BA_ "Confidence" SG_ 771 OCS1P_occupantClassificationSelf 0;
BA_ "GenSigSNA" SG_ 771 OCS1P_occupantClassificationSelf "7";
BA_ "Confidence" SG_ 771 OCS1P_occupantClassificationRawC 0;
BA_ "GenSigSNA" SG_ 771 OCS1P_occupantClassificationRawC "7";
BA_ "SystemSignalLongSymbol" SG_ 771 OCS1P_occupantClassificationRawC "OCS1P_occupantClassificationRawCap";
BA_ "Confidence" SG_ 771 OCS1P_occupantClassificationCap 0;
BA_ "GenSigSNA" SG_ 771 OCS1P_occupantClassificationCap "7";
BA_ "Confidence" SG_ 771 OCS1P_classificationHeld 0;
BA_ "Confidence" SG_ 771 OCS1P_cushionStable 0;
BA_ "Confidence" SG_ 771 OCS1P_classificationExtHold 0;
BA_ "Confidence" SG_ 771 OCS1P_classificationHoldState 0;
BA_ "Confidence" SG_ 771 OCS1P_classificationVariant 0;
BA_ "Confidence" SG_ 771 OCS1P_sandwichDisabled 0;
BA_ "Confidence" SG_ 771 OCS1P_noSandwichType 0;
BA_ "Confidence" SG_ 771 OCS1P_sandwichBoundaryType 0;
BA_ "Confidence" SG_ 771 OCS1P_sbrBoundaryType 0;
BA_ "Confidence" SG_ 771 OCS1P_occupiedStateCap 0;
BA_ "GenSigSNA" SG_ 771 OCS1P_occupiedStateCap "3";
BA_ "Confidence" SG_ 771 OCS1P_seatbackStable 0;
BA_ "Confidence" SG_ 771 OCS1P_sandwichStable 0;
BA_ "Confidence" SG_ 771 OCS1P_cushionStableCap 0;
BA_ "Confidence" SG_ 771 OCS1P_seatbackStableCap 0;
BA_ "Confidence" SG_ 771 OCS1P_classificationHeldCap 0;
BA_ "Confidence" SG_ 771 OCS1P_statusCounter 0;
BA_ "Confidence" SG_ 771 OCS1P_statusChecksum 0;
BA_ "Confidence" SG_ 1486 PARK_alertID 1;
BA_ "Confidence" SG_ 1486 PARK_alertState 1;
BA_ "Confidence" SG_ 1486 PARK_sw001_sensorTemperature 1;
BA_ "SystemSignalLongSymbol" SG_ 1486 PARK_sw002_diagnosticTransferErr "PARK_sw002_diagnosticTransferError";
BA_ "Confidence" SG_ 1486 PARK_sw004_reverbPeriod 1;
BA_ "Confidence" SG_ 1486 PARK_sw004_reverbTime 1;
BA_ "Confidence" SG_ 1486 PARK_sw006_sensorTemperature 1;
BA_ "SystemSignalLongSymbol" SG_ 1486 PARK_sw007_diagnosticTransferErr "PARK_sw007_diagnosticTransferError";
BA_ "Confidence" SG_ 1486 PARK_sw009_reverbPeriod 1;
BA_ "Confidence" SG_ 1486 PARK_sw009_reverbTime 1;
BA_ "Confidence" SG_ 1486 PARK_sw011_sensorTemperature 1;
BA_ "SystemSignalLongSymbol" SG_ 1486 PARK_sw012_diagnosticTransferErr "PARK_sw012_diagnosticTransferError";
BA_ "Confidence" SG_ 1486 PARK_sw014_reverbPeriod 1;
BA_ "Confidence" SG_ 1486 PARK_sw014_reverbTime 1;
BA_ "Confidence" SG_ 1486 PARK_sw016_sensorTemperature 1;
BA_ "SystemSignalLongSymbol" SG_ 1486 PARK_sw017_diagnosticTransferErr "PARK_sw017_diagnosticTransferError";
BA_ "Confidence" SG_ 1486 PARK_sw019_reverbPeriod 1;
BA_ "Confidence" SG_ 1486 PARK_sw019_reverbTime 1;
BA_ "Confidence" SG_ 1486 PARK_sw021_sensorTemperature 1;
BA_ "SystemSignalLongSymbol" SG_ 1486 PARK_sw022_diagnosticTransferErr "PARK_sw022_diagnosticTransferError";
BA_ "Confidence" SG_ 1486 PARK_sw024_reverbPeriod 1;
BA_ "Confidence" SG_ 1486 PARK_sw024_reverbTime 1;
BA_ "Confidence" SG_ 1486 PARK_sw026_sensorTemperature 1;
BA_ "SystemSignalLongSymbol" SG_ 1486 PARK_sw027_diagnosticTransferErr "PARK_sw027_diagnosticTransferError";
BA_ "Confidence" SG_ 1486 PARK_sw029_reverbPeriod 1;
BA_ "Confidence" SG_ 1486 PARK_sw029_reverbTime 1;
BA_ "Confidence" SG_ 1486 PARK_sw031_sensorTemperature 1;
BA_ "SystemSignalLongSymbol" SG_ 1486 PARK_sw032_diagnosticTransferErr "PARK_sw032_diagnosticTransferError";
BA_ "Confidence" SG_ 1486 PARK_sw034_reverbPeriod 1;
BA_ "Confidence" SG_ 1486 PARK_sw034_reverbTime 1;
BA_ "Confidence" SG_ 1486 PARK_sw036_sensorTemperature 1;
BA_ "SystemSignalLongSymbol" SG_ 1486 PARK_sw037_diagnosticTransferErr "PARK_sw037_diagnosticTransferError";
BA_ "Confidence" SG_ 1486 PARK_sw039_reverbPeriod 1;
BA_ "Confidence" SG_ 1486 PARK_sw039_reverbTime 1;
BA_ "Confidence" SG_ 1486 PARK_sw041_sensorTemperature 1;
BA_ "SystemSignalLongSymbol" SG_ 1486 PARK_sw042_diagnosticTransferErr "PARK_sw042_diagnosticTransferError";
BA_ "Confidence" SG_ 1486 PARK_sw044_reverbPeriod 1;
BA_ "Confidence" SG_ 1486 PARK_sw044_reverbTime 1;
BA_ "Confidence" SG_ 1486 PARK_sw046_sensorTemperature 1;
BA_ "SystemSignalLongSymbol" SG_ 1486 PARK_sw047_diagnosticTransferErr "PARK_sw047_diagnosticTransferError";
BA_ "Confidence" SG_ 1486 PARK_sw049_reverbPeriod 1;
BA_ "Confidence" SG_ 1486 PARK_sw049_reverbTime 1;
BA_ "Confidence" SG_ 1486 PARK_sw051_sensorTemperature 1;
BA_ "SystemSignalLongSymbol" SG_ 1486 PARK_sw052_diagnosticTransferErr "PARK_sw052_diagnosticTransferError";
BA_ "Confidence" SG_ 1486 PARK_sw054_reverbPeriod 1;
BA_ "Confidence" SG_ 1486 PARK_sw054_reverbTime 1;
BA_ "Confidence" SG_ 1486 PARK_sw056_sensorTemperature 1;
BA_ "SystemSignalLongSymbol" SG_ 1486 PARK_sw057_diagnosticTransferErr "PARK_sw057_diagnosticTransferError";
BA_ "Confidence" SG_ 1486 PARK_sw059_reverbPeriod 1;
BA_ "Confidence" SG_ 1486 PARK_sw059_reverbTime 1;
BA_ "Confidence" SG_ 1486 PARK_sw061_voltage 1;
BA_ "Confidence" SG_ 1486 PARK_sw063_voltage 1;
BA_ "Confidence" SG_ 1486 PARK_sw077_errorType 1;
BA_ "Confidence" SG_ 1486 PARK_sw078_errorType 1;
BA_ "Confidence" SG_ 1486 PARK_sw079_errorType 1;
BA_ "Confidence" SG_ 1486 PARK_sw080_errorType 1;
BA_ "Confidence" SG_ 1486 PARK_sw081_errorType 1;
BA_ "Confidence" SG_ 1486 PARK_sw082_errorType 1;
BA_ "Confidence" SG_ 1486 PARK_sw083_errorType 1;
BA_ "Confidence" SG_ 1486 PARK_sw084_errorType 1;
BA_ "Confidence" SG_ 1486 PARK_sw087_s1_sensorType 1;
BA_ "GenSigSNA" SG_ 1486 PARK_sw087_s1_sensorType "3";
BA_ "Confidence" SG_ 1486 PARK_sw087_s2_sensorType 1;
BA_ "GenSigSNA" SG_ 1486 PARK_sw087_s2_sensorType "3";
BA_ "Confidence" SG_ 1486 PARK_sw087_s3_sensorType 1;
BA_ "GenSigSNA" SG_ 1486 PARK_sw087_s3_sensorType "3";
BA_ "Confidence" SG_ 1486 PARK_sw087_s4_sensorType 1;
BA_ "GenSigSNA" SG_ 1486 PARK_sw087_s4_sensorType "3";
BA_ "Confidence" SG_ 1486 PARK_sw087_s5_sensorType 1;
BA_ "GenSigSNA" SG_ 1486 PARK_sw087_s5_sensorType "3";
BA_ "Confidence" SG_ 1486 PARK_sw087_s6_sensorType 1;
BA_ "GenSigSNA" SG_ 1486 PARK_sw087_s6_sensorType "3";
BA_ "Confidence" SG_ 1486 PARK_sw087_s7_sensorType 1;
BA_ "GenSigSNA" SG_ 1486 PARK_sw087_s7_sensorType "3";
BA_ "Confidence" SG_ 1486 PARK_sw087_s8_sensorType 1;
BA_ "GenSigSNA" SG_ 1486 PARK_sw087_s8_sensorType "3";
BA_ "Confidence" SG_ 1486 PARK_sw087_s9_sensorType 1;
BA_ "GenSigSNA" SG_ 1486 PARK_sw087_s9_sensorType "3";
BA_ "Confidence" SG_ 1486 PARK_sw087_s10_sensorType 1;
BA_ "GenSigSNA" SG_ 1486 PARK_sw087_s10_sensorType "3";
BA_ "Confidence" SG_ 1486 PARK_sw087_s11_sensorType 1;
BA_ "GenSigSNA" SG_ 1486 PARK_sw087_s11_sensorType "3";
BA_ "Confidence" SG_ 1486 PARK_sw087_s12_sensorType 1;
BA_ "GenSigSNA" SG_ 1486 PARK_sw087_s12_sensorType "3";
BA_ "Confidence" SG_ 806 PARK_infoIndex 1;
BA_ "Confidence" SG_ 806 PARK_infoBuildType 0;
BA_ "Confidence" SG_ 806 PARK_infoComponentID 0;
BA_ "Confidence" SG_ 806 PARK_infoPcbaID 0;
BA_ "Confidence" SG_ 806 PARK_infoAssemblyID 0;
BA_ "Confidence" SG_ 806 PARK_infoUsageID 0;
BA_ "Confidence" SG_ 806 PARK_infoApplicationCRC 0;
BA_ "Confidence" SG_ 806 PARK_infoBootUdsProtoVersion 0;
BA_ "Confidence" SG_ 806 PARK_infoBootloaderCRC 0;
BA_ "Confidence" SG_ 846 PARK_frontLeftMiddleRawDistData 0;
BA_ "GenSigSNA" SG_ 846 PARK_frontLeftMiddleRawDistData "255";
BA_ "Confidence" SG_ 846 PARK_frontMiddleRawDistData 0;
BA_ "GenSigSNA" SG_ 846 PARK_frontMiddleRawDistData "255";
BA_ "Confidence" SG_ 846 PARK_frontRightMiddleRawDistData 0;
BA_ "GenSigSNA" SG_ 846 PARK_frontRightMiddleRawDistData "255";
BA_ "Confidence" SG_ 846 PARK_pasFrontMiddleCounter 0;
BA_ "Confidence" SG_ 846 PARK_pasFrontMiddleChecksum 0;
BA_ "Confidence" SG_ 862 PARK_rearLeftMiddleRawDistData 0;
BA_ "GenSigSNA" SG_ 862 PARK_rearLeftMiddleRawDistData "255";
BA_ "Confidence" SG_ 862 PARK_rearMiddleRawDistData 0;
BA_ "GenSigSNA" SG_ 862 PARK_rearMiddleRawDistData "255";
BA_ "Confidence" SG_ 862 PARK_rearRightMiddleRawDistData 0;
BA_ "GenSigSNA" SG_ 862 PARK_rearRightMiddleRawDistData "255";
BA_ "Confidence" SG_ 862 PARK_pasRearMiddleCounter 0;
BA_ "Confidence" SG_ 862 PARK_pasRearMiddleChecksum 0;
VAL_ 1470 IDB_alertID 157 "a157_PMlocStateCounter" 156 "a156_PMlocStateChecksum" 155 "a155_PMlocStateDLC" 152 "a152_DIlocStatus2Checksum" 151 "a151_DIlocStatus2Counter" 150 "a150_DIlocStatus2DLC" 149 "a149_DASmiaBrakeTorqueCommandInvalid" 148 "a148_DASbrakeTorqueCommandInvalid" 147 "a147_DASredundantBrakingControlChecksum" 146 "a146_DASredundantBrakingControlCounter" 145 "a145_DASredundantBrakingControlDLC" 144 "a144_hydraulicPushthroughActive" 143 "a143_factoryModeActive" 142 "a142_PMebrCmdStateInvalid" 141 "a141_DIbrakeTorqueCommandFullTooLow" 140 "a140_PMbrakePedalCmdQFInvalid" 139 "a139_DIbrakeTorqueCommandFullSNA" 138 "a138_DIbrakeTorqueCommandAndFlagMismatch" 137 "a137_VCLEFTcdpRequestInvalid" 136 "a136_RCUptsCalMissing" 135 "a135_DIbrakeCommandChecksum" 134 "a134_DIbrakeCommandCounter" 133 "a133_DIbrakeCommandDLC" 132 "a132_RCUinputRodStrokeQFInvalid" 131 "a131_cbcFaulted" 130 "a130_DIfullTorqueRequestInvalid" 129 "a129_RCUinputRodStrokeInvalid" 128 "a128_largeAirVolume" 127 "a127_brakeFluidLevelInvalid" 126 "a126_DItorqueRequestInvalid" 125 "a125_PMvdcCmdStateInvalid" 124 "a124_VCFRONTtempInvalid" 123 "a123_DIRtorqueCommandInvalid" 122 "a122_DIFtorqueCommandInvalid" 121 "a121_dynoModeActive" 120 "a120_EPAS3Pinvalid" 119 "a119_VCLEFTepbmStatusChecksum" 118 "a118_VCLEFTepbmStatusCounter" 117 "a117_VCLEFTepbmStatusDLC" 116 "a116_VCFRONTsensorsDLC" 115 "a115_VCFRONTespLvStInvalid" 114 "a114_longAccelInvalid" 113 "a113_latAccelInvalid" 112 "a112_yawRateInvalid" 111 "a111_EPBstatusChecksum" 110 "a110_EPBstatusCounter" 109 "a109_BDWsignalInvalid" 108 "a108_EPBstatusDLC" 107 "a107_DIRtorqueInvalid" 106 "a106_DIFtorqueInvalid" 105 "a105_DIgearInvalid" 104 "a104_DIaccelPosInvalid" 103 "a103_DIfullTorquePathFaulted" 102 "a102_bdwRequestActiveInvalid" 101 "a101_RCMcollisionCounter" 100 "a100_RCMcollisionChecksum" 99 "a099_RCMcollisionDLC" 98 "a098_VCFRONTLVPwrStCounter" 97 "a097_VCFRONTLVPwrStChecksum" 96 "a096_VCFRONTLVPowerStateDLC" 95 "a095_RCMinertial2Counter" 94 "a094_RCMinertial2Checksum" 93 "a093_RCMinertial2DLC" 92 "a092_RCMinertial1Counter" 91 "a091_RCMinertial1Checksum" 90 "a090_RCMinertial1DLC" 89 "a089_PMstate2Counter" 88 "a088_PMstate2Checksum" 87 "a087_PMstate2DLC" 86 "a086_EPAS3PsysStatusCounter" 85 "a085_EPAS3PsysStatusChecksum" 84 "a084_EPAS3PsysStatusDLC" 83 "a083_DIvdcRightCounter" 82 "a082_DIvdcRightChecksum" 81 "a081_DIvdcRightDLC" 80 "a080_DIvdcLeftCounter" 79 "a079_DIvdcLeftChecksum" 78 "a078_DIvdcLeftDLC" 77 "a077_DIRtorqueCounter" 76 "a076_DIRtorqueChecksum" 75 "a075_DIRtorqueDLC" 74 "a074_DIsystemStatusCounter" 73 "a073_DIsystemStatusChecksum" 72 "a072_DIsystemStatusDLC" 71 "a071_DIchassisControlCounter" 70 "a070_DIchassisControlChecksum" 69 "a069_DIchassisControlDLC" 68 "a068_DIFtorqueCounter" 67 "a067_DIFtorqueChecksum" 66 "a066_DIFtorqueDLC" 65 "a065_RCUactuationCounter" 64 "a064_RCUactuationChecksum" 63 "a063_RCUactuationDLC" 62 "a062_RCUstatusCounter" 61 "a061_RCUstatusChecksum" 60 "a060_RCUstatusDLC" 59 "a059_cdpFaulted" 58 "a058_scmFaulted" 57 "a057_bdwRequestInvalid" 56 "a056_fadeCompensationFaulted" 55 "a055_panicBrakeAssistFaulted" 54 "a054_skidDetectionFaulted" 53 "a053_DItorquePathFaulted" 52 "a052_vdcFaulted" 51 "a051_ebdFaulted" 50 "a050_absFaulted" 49 "a049_cdpActive" 48 "a048_scmActive" 47 "a047_brakeDiscWipeActive" 46 "a046_fadeCompensationActive" 45 "a045_panicBrakeAssistActive" 44 "a044_standstillSkidDetected" 43 "a043_cbcActive" 42 "a042_btcActive" 41 "a041_vdcActive" 40 "a040_ebdActive" 39 "a039_absActive" 38 "a038_motorInitFault" 37 "a037_chassisBusOff" 36 "a036_partyBusOff" 35 "a035_motorStuck" 34 "a034_motorPositionSetFault" 33 "a033_motorHardOverheat" 32 "a032_motorSoftOverheat" 31 "a031_solenoidValveStuck" 30 "a030_fluidLeakDetected" 29 "a029_pressureSensNotCal" 28 "a028_simPresSensorFault" 27 "a027_circuitPresSensorFault" 26 "a026_axImplausible" 25 "a025_ayImplausible" 24 "a024_yawImplausible" 23 "a023_steeringImplausible" 22 "a022_brakeFluidLow" 21 "a021_pedalSensorNotCal" 20 "a020_RCUpedalTravelMismatch" 19 "a019_pedalSensorFault" 18 "a018_WSSGenericFault" 17 "a017_ReRWSSFault" 16 "a016_ReLWSSFault" 15 "a015_FrRWSSFault" 14 "a014_FrLWSSFault" 13 "a013_motorPosSensorFault" 12 "a012_motorGenericFault" 11 "a011_solenoidValveFault" 10 "a010_asicGenericFault" 9 "a009_asicBoostFault" 8 "a008_motorPowerOpen" 7 "a007_wakeLineOpen" 6 "a006_supplyHardUndervoltage" 5 "a005_supplyMidUndervoltage" 4 "a004_supplyUndervoltage" 3 "a003_supplyHardOvervoltage" 2 "a002_supplyOvervoltage" 1 "a001_mcuGenericFault" 0 "ALERT_DO_NOT_USE_ZERO" ;
VAL_ 1470 IDB_alertState 1 "SET" 0 "CLEARED" ;
VAL_ 1470 IDB_a014_wheelSpeedSensorFreq 1 "NOT_OK" 0 "OK" ;
VAL_ 1470 IDB_a014_wheelSpeedSensorPhase 1 "NOT_OK" 0 "OK" ;
VAL_ 1470 IDB_a014_wheelSpeedSensorMisinst 1 "NOT_OK" 0 "OK" ;
VAL_ 1470 IDB_a014_wheelSpeedSensorWrongEx 1 "NOT_OK" 0 "OK" ;
VAL_ 1470 IDB_a014_wheelSpeedSensorSpeedJu 1 "NOT_OK" 0 "OK" ;
VAL_ 1470 IDB_a014_wheelSpeedSensorSp_0001 1 "NOT_OK" 0 "OK" ;
VAL_ 1470 IDB_a014_wheelSpeedSensorAirGap 1 "NOT_OK" 0 "OK" ;
VAL_ 1470 IDB_a014_wheelSpeedSensorBIST 1 "NOT_OK" 0 "OK" ;
VAL_ 1470 IDB_a014_wheelSpeedSensorLeakage 1 "NOT_OK" 0 "OK" ;
VAL_ 1470 IDB_a014_wheelSpeedSensorOverTem 1 "NOT_OK" 0 "OK" ;
VAL_ 1470 IDB_a014_wheelSpeedSensorSh_0001 1 "NOT_OK" 0 "OK" ;
VAL_ 1470 IDB_a014_wheelSpeedSensorShortTo 1 "NOT_OK" 0 "OK" ;
VAL_ 1470 IDB_a014_wheelSpeedSensorOpen 1 "NOT_OK" 0 "OK" ;
VAL_ 1470 IDB_a015_wheelSpeedSensorFreq 1 "NOT_OK" 0 "OK" ;
VAL_ 1470 IDB_a015_wheelSpeedSensorPhase 1 "NOT_OK" 0 "OK" ;
VAL_ 1470 IDB_a015_wheelSpeedSensorMisinst 1 "NOT_OK" 0 "OK" ;
VAL_ 1470 IDB_a015_wheelSpeedSensorWrongEx 1 "NOT_OK" 0 "OK" ;
VAL_ 1470 IDB_a015_wheelSpeedSensorSpeedJu 1 "NOT_OK" 0 "OK" ;
VAL_ 1470 IDB_a015_wheelSpeedSensorSp_0001 1 "NOT_OK" 0 "OK" ;
VAL_ 1470 IDB_a015_wheelSpeedSensorAirGap 1 "NOT_OK" 0 "OK" ;
VAL_ 1470 IDB_a015_wheelSpeedSensorBIST 1 "NOT_OK" 0 "OK" ;
VAL_ 1470 IDB_a015_wheelSpeedSensorLeakage 1 "NOT_OK" 0 "OK" ;
VAL_ 1470 IDB_a015_wheelSpeedSensorOverTem 1 "NOT_OK" 0 "OK" ;
VAL_ 1470 IDB_a015_wheelSpeedSensorSh_0001 1 "NOT_OK" 0 "OK" ;
VAL_ 1470 IDB_a015_wheelSpeedSensorShortTo 1 "NOT_OK" 0 "OK" ;
VAL_ 1470 IDB_a015_wheelSpeedSensorOpen 1 "NOT_OK" 0 "OK" ;
VAL_ 1470 IDB_a016_wheelSpeedSensorFreq 1 "NOT_OK" 0 "OK" ;
VAL_ 1470 IDB_a016_wheelSpeedSensorPhase 1 "NOT_OK" 0 "OK" ;
VAL_ 1470 IDB_a016_wheelSpeedSensorMisinst 1 "NOT_OK" 0 "OK" ;
VAL_ 1470 IDB_a016_wheelSpeedSensorWrongEx 1 "NOT_OK" 0 "OK" ;
VAL_ 1470 IDB_a016_wheelSpeedSensorSpeedJu 1 "NOT_OK" 0 "OK" ;
VAL_ 1470 IDB_a016_wheelSpeedSensorSp_0001 1 "NOT_OK" 0 "OK" ;
VAL_ 1470 IDB_a016_wheelSpeedSensorAirGap 1 "NOT_OK" 0 "OK" ;
VAL_ 1470 IDB_a016_wheelSpeedSensorBIST 1 "NOT_OK" 0 "OK" ;
VAL_ 1470 IDB_a016_wheelSpeedSensorLeakage 1 "NOT_OK" 0 "OK" ;
VAL_ 1470 IDB_a016_wheelSpeedSensorOverTem 1 "NOT_OK" 0 "OK" ;
VAL_ 1470 IDB_a016_wheelSpeedSensorSh_0001 1 "NOT_OK" 0 "OK" ;
VAL_ 1470 IDB_a016_wheelSpeedSensorShortTo 1 "NOT_OK" 0 "OK" ;
VAL_ 1470 IDB_a016_wheelSpeedSensorOpen 1 "NOT_OK" 0 "OK" ;
VAL_ 1470 IDB_a017_wheelSpeedSensorFreq 1 "NOT_OK" 0 "OK" ;
VAL_ 1470 IDB_a017_wheelSpeedSensorPhase 1 "NOT_OK" 0 "OK" ;
VAL_ 1470 IDB_a017_wheelSpeedSensorMisinst 1 "NOT_OK" 0 "OK" ;
VAL_ 1470 IDB_a017_wheelSpeedSensorWrongEx 1 "NOT_OK" 0 "OK" ;
VAL_ 1470 IDB_a017_wheelSpeedSensorSpeedJu 1 "NOT_OK" 0 "OK" ;
VAL_ 1470 IDB_a017_wheelSpeedSensorSp_0001 1 "NOT_OK" 0 "OK" ;
VAL_ 1470 IDB_a017_wheelSpeedSensorAirGap 1 "NOT_OK" 0 "OK" ;
VAL_ 1470 IDB_a017_wheelSpeedSensorBIST 1 "NOT_OK" 0 "OK" ;
VAL_ 1470 IDB_a017_wheelSpeedSensorLeakage 1 "NOT_OK" 0 "OK" ;
VAL_ 1470 IDB_a017_wheelSpeedSensorOverTem 1 "NOT_OK" 0 "OK" ;
VAL_ 1470 IDB_a017_wheelSpeedSensorSh_0001 1 "NOT_OK" 0 "OK" ;
VAL_ 1470 IDB_a017_wheelSpeedSensorShortTo 1 "NOT_OK" 0 "OK" ;
VAL_ 1470 IDB_a017_wheelSpeedSensorOpen 1 "NOT_OK" 0 "OK" ;
VAL_ 1470 IDB_a020_canSignalValidity 1 "NOT_OK" 0 "OK" ;
VAL_ 1470 IDB_a020_signalValueCrosscheck 1 "NOT_OK" 0 "OK" ;
VAL_ 1470 IDB_a030_primaryExternalCircuitL 1 "NOT_OK" 0 "OK" ;
VAL_ 1470 IDB_a030_secondaryExternalCircui 1 "NOT_OK" 0 "OK" ;
VAL_ 1470 IDB_a030_primaryChamberInternalL 1 "NOT_OK" 0 "OK" ;
VAL_ 1470 IDB_a030_syncModeInternalLeakage 1 "NOT_OK" 0 "OK" ;
VAL_ 1470 IDB_a030_secondaryChamberInterna 1 "NOT_OK" 0 "OK" ;
VAL_ 1470 IDB_a030_masterCylinderInternalL 1 "NOT_OK" 0 "OK" ;
VAL_ 1470 IDB_a060_validityOnChassisBus 1 "NOT_OK" 0 "OK" ;
VAL_ 1470 IDB_a060_validityOnPartyBus 1 "NOT_OK" 0 "OK" ;
VAL_ 1470 IDB_a061_validityOnChassisBus 1 "NOT_OK" 0 "OK" ;
VAL_ 1470 IDB_a061_validityOnPartyBus 1 "NOT_OK" 0 "OK" ;
VAL_ 1470 IDB_a063_validityOnChassisBus 1 "NOT_OK" 0 "OK" ;
VAL_ 1470 IDB_a063_validityOnPartyBus 1 "NOT_OK" 0 "OK" ;
VAL_ 1470 IDB_a064_validityOnChassisBus 1 "NOT_OK" 0 "OK" ;
VAL_ 1470 IDB_a064_validityOnPartyBus 1 "NOT_OK" 0 "OK" ;
VAL_ 1470 IDB_a065_validityOnChassisBus 1 "NOT_OK" 0 "OK" ;
VAL_ 1470 IDB_a065_validityOnPartyBus 1 "NOT_OK" 0 "OK" ;
VAL_ 1470 IDB_a106_qualifierValidity 1 "NOT_OK" 0 "OK" ;
VAL_ 1470 IDB_a106_signalNotAvailable 1 "NOT_OK" 0 "OK" ;
VAL_ 1470 IDB_a107_qualifierValidity 1 "NOT_OK" 0 "OK" ;
VAL_ 1470 IDB_a107_signalNotAvailable 1 "NOT_OK" 0 "OK" ;
VAL_ 1470 IDB_a112_qualifierValidity 1 "NOT_OK" 0 "OK" ;
VAL_ 1470 IDB_a112_signalNotAvailable 1 "NOT_OK" 0 "OK" ;
VAL_ 1470 IDB_a113_qualifierValidity 1 "NOT_OK" 0 "OK" ;
VAL_ 1470 IDB_a113_signalNotAvailable 1 "NOT_OK" 0 "OK" ;
VAL_ 1470 IDB_a114_qualifierValidity 1 "NOT_OK" 0 "OK" ;
VAL_ 1470 IDB_a114_signalNotAvailable 1 "NOT_OK" 0 "OK" ;
VAL_ 1470 IDB_a126_PMebrCmdStateValidity 1 "NOT_OK" 0 "OK" ;
VAL_ 1470 IDB_a126_PMstate2Validity 1 "NOT_OK" 0 "OK" ;
VAL_ 1470 IDB_a126_PMstate2Missing 1 "NOT_OK" 0 "OK" ;
VAL_ 1470 IDB_a126_DIchassisControlValidit 1 "NOT_OK" 0 "OK" ;
VAL_ 1470 IDB_a126_DIchassisControlMissing 1 "NOT_OK" 0 "OK" ;
VAL_ 1470 IDB_a126_DIrequestActiveValidity 1 "NOT_OK" 0 "OK" ;
VAL_ 1470 IDB_a129_validityOnChassisBus 1 "NOT_OK" 0 "OK" ;
VAL_ 1470 IDB_a129_validityOnPartyBus 1 "NOT_OK" 0 "OK" ;
VAL_ 1470 IDB_a130_PMbrakePedalCmdQFValidi 1 "NOT_OK" 0 "OK" ;
VAL_ 1470 IDB_a130_PMstate2Validity 1 "NOT_OK" 0 "OK" ;
VAL_ 1470 IDB_a130_PMstate2Missing 1 "NOT_OK" 0 "OK" ;
VAL_ 1470 IDB_a130_DIbrakeCommandValidity 1 "NOT_OK" 0 "OK" ;
VAL_ 1470 IDB_a130_DIbrakeCommandMissing 1 "NOT_OK" 0 "OK" ;
VAL_ 1470 IDB_a130_DIbrakeTorqueCommandFul 1 "NOT_OK" 0 "OK" ;
VAL_ 1470 IDB_a130_DIbrakeTorqueComma_0001 1 "NOT_OK" 0 "OK" ;
VAL_ 1470 IDB_a132_validityOnChassisBus 1 "NOT_OK" 0 "OK" ;
VAL_ 1470 IDB_a132_validityOnPartyBus 1 "NOT_OK" 0 "OK" ;
VAL_ 983 IDB_matrixIndex 2 "AlertMatrix2" 1 "AlertMatrix1" 0 "AlertMatrix0" ;
VAL_ 828 IDB_infoIndex 255 "END" 31 "SUBCOMPONENT_GITHASH" 30 "PACKAGE_SN_8_14" 29 "PACKAGE_SN_1_7" 27 "PACKAGE_PN_15_20" 26 "PACKAGE_PN_8_14" 25 "PACKAGE_PN_1_7" 23 "SUBCOMPONENT2" 22 "VARIANTCRC" 20 "UDS_PROTOCOL_BOOTCRC" 19 "VERSION_DEPRECATED" 18 "BOOTLOADER_GITHASH" 17 "APP_GITHASH" 16 "SUBCOMPONENT" 15 "BOOTLOADER_CRC" 14 "BOOTLOADER_SVN" 13 "APP_CRC" 11 "PCBAID_ASSYID_USAGEID" 10 "BUILD_HWID_COMPONENTID" 9 "DEPRECATED_9" 8 "DEPRECATED_8" 7 "DEPRECATED_7" 6 "DEPRECATED_6" 5 "DEPRECATED_5" 4 "DEPRECATED_4" 3 "DEPRECATED_3" 2 "DEPRECATED_2" 1 "DEPRECATED_1" 0 "DEPRECATED_0" ;
VAL_ 1012 LS_lightShowIndex 24 "LightShowMux24" 23 "LightShowMux23" 22 "LightShowMux22" 21 "LightShowMux21" 20 "LightShowMux20" 19 "LightShowMux19" 18 "LightShowMux18" 17 "LightShowMux17" 16 "LightShowMux16" 15 "LightShowMux15" 14 "LightShowMux14" 13 "LightShowMux13" 12 "LightShowMux12" 11 "LightShowMux11" 10 "LightShowMux10" 9 "LightShowMux9" 8 "LightShowMux8" 7 "LightShowMux7" 6 "LightShowMux6" 5 "LightShowMux5" 4 "LightShowMux4" 3 "LightShowMux3" 2 "LightShowMux2" 1 "LightShowMux1" 0 "LightShowMux0" ;
VAL_ 1012 LS_lightLeftRampedChannel1Durati 3 "TWO_SECONDS" 2 "ONE_SECOND" 1 "HALF_SECOND" 0 "INSTANT" ;
VAL_ 1012 LS_lightLeftRampedChannel2Durati 3 "TWO_SECONDS" 2 "ONE_SECOND" 1 "HALF_SECOND" 0 "INSTANT" ;
VAL_ 1012 LS_lightLeftRampedChannel3Durati 3 "TWO_SECONDS" 2 "ONE_SECOND" 1 "HALF_SECOND" 0 "INSTANT" ;
VAL_ 1012 LS_lightLeftRampedChannel4Durati 3 "TWO_SECONDS" 2 "ONE_SECOND" 1 "HALF_SECOND" 0 "INSTANT" ;
VAL_ 1012 LS_lightLeftRampedChannel5Durati 3 "TWO_SECONDS" 2 "ONE_SECOND" 1 "HALF_SECOND" 0 "INSTANT" ;
VAL_ 1012 LS_lightLeftRampedChannel6Durati 3 "TWO_SECONDS" 2 "ONE_SECOND" 1 "HALF_SECOND" 0 "INSTANT" ;
VAL_ 1012 LS_lightLeftRampedChannel7Durati 3 "TWO_SECONDS" 2 "ONE_SECOND" 1 "HALF_SECOND" 0 "INSTANT" ;
VAL_ 1012 LS_lightRightRampedChannel1Durat 3 "TWO_SECONDS" 2 "ONE_SECOND" 1 "HALF_SECOND" 0 "INSTANT" ;
VAL_ 1012 LS_lightRightRampedChannel2Durat 3 "TWO_SECONDS" 2 "ONE_SECOND" 1 "HALF_SECOND" 0 "INSTANT" ;
VAL_ 1012 LS_lightRightRampedChannel3Durat 3 "TWO_SECONDS" 2 "ONE_SECOND" 1 "HALF_SECOND" 0 "INSTANT" ;
VAL_ 1012 LS_lightRightRampedChannel4Durat 3 "TWO_SECONDS" 2 "ONE_SECOND" 1 "HALF_SECOND" 0 "INSTANT" ;
VAL_ 1012 LS_lightRightRampedChannel5Durat 3 "TWO_SECONDS" 2 "ONE_SECOND" 1 "HALF_SECOND" 0 "INSTANT" ;
VAL_ 1012 LS_lightRightRampedChannel6Durat 3 "TWO_SECONDS" 2 "ONE_SECOND" 1 "HALF_SECOND" 0 "INSTANT" ;
VAL_ 1012 LS_lightRightRampedChannel7Durat 3 "TWO_SECONDS" 2 "ONE_SECOND" 1 "HALF_SECOND" 0 "INSTANT" ;
VAL_ 1012 LS_mirrorRequestLeft 4 "HOLIDAY_PARTY_STOP" 3 "HOLIDAY_PARTY_CLOSE" 2 "HOLIDAY_PARTY_DANCE" 1 "HOLIDAY_PARTY_OPEN" 0 "HOLIDAY_PARTY_IDLE" ;
VAL_ 1012 LS_mirrorRequestRight 4 "HOLIDAY_PARTY_STOP" 3 "HOLIDAY_PARTY_CLOSE" 2 "HOLIDAY_PARTY_DANCE" 1 "HOLIDAY_PARTY_OPEN" 0 "HOLIDAY_PARTY_IDLE" ;
VAL_ 1012 LS_liftgateRequest 4 "HOLIDAY_PARTY_STOP" 3 "HOLIDAY_PARTY_CLOSE" 2 "HOLIDAY_PARTY_DANCE" 1 "HOLIDAY_PARTY_OPEN" 0 "HOLIDAY_PARTY_IDLE" ;
VAL_ 1012 LS_windowRequestLF 4 "HOLIDAY_PARTY_STOP" 3 "HOLIDAY_PARTY_CLOSE" 2 "HOLIDAY_PARTY_DANCE" 1 "HOLIDAY_PARTY_OPEN" 0 "HOLIDAY_PARTY_IDLE" ;
VAL_ 1012 LS_windowRequestLR 4 "HOLIDAY_PARTY_STOP" 3 "HOLIDAY_PARTY_CLOSE" 2 "HOLIDAY_PARTY_DANCE" 1 "HOLIDAY_PARTY_OPEN" 0 "HOLIDAY_PARTY_IDLE" ;
VAL_ 1012 LS_windowRequestRF 4 "HOLIDAY_PARTY_STOP" 3 "HOLIDAY_PARTY_CLOSE" 2 "HOLIDAY_PARTY_DANCE" 1 "HOLIDAY_PARTY_OPEN" 0 "HOLIDAY_PARTY_IDLE" ;
VAL_ 1012 LS_windowRequestRR 4 "HOLIDAY_PARTY_STOP" 3 "HOLIDAY_PARTY_CLOSE" 2 "HOLIDAY_PARTY_DANCE" 1 "HOLIDAY_PARTY_OPEN" 0 "HOLIDAY_PARTY_IDLE" ;
VAL_ 1012 LS_presentingHandleRequestLF 4 "HOLIDAY_PARTY_STOP" 3 "HOLIDAY_PARTY_CLOSE" 2 "HOLIDAY_PARTY_DANCE" 1 "HOLIDAY_PARTY_OPEN" 0 "HOLIDAY_PARTY_IDLE" ;
VAL_ 1012 LS_presentingHandleRequestLR 4 "HOLIDAY_PARTY_STOP" 3 "HOLIDAY_PARTY_CLOSE" 2 "HOLIDAY_PARTY_DANCE" 1 "HOLIDAY_PARTY_OPEN" 0 "HOLIDAY_PARTY_IDLE" ;
VAL_ 1012 LS_presentingHandleRequestRF 4 "HOLIDAY_PARTY_STOP" 3 "HOLIDAY_PARTY_CLOSE" 2 "HOLIDAY_PARTY_DANCE" 1 "HOLIDAY_PARTY_OPEN" 0 "HOLIDAY_PARTY_IDLE" ;
VAL_ 1012 LS_presentingHandleRequestRR 4 "HOLIDAY_PARTY_STOP" 3 "HOLIDAY_PARTY_CLOSE" 2 "HOLIDAY_PARTY_DANCE" 1 "HOLIDAY_PARTY_OPEN" 0 "HOLIDAY_PARTY_IDLE" ;
VAL_ 1012 LS_powerFrontDoorRequestLeft 4 "HOLIDAY_PARTY_STOP" 3 "HOLIDAY_PARTY_CLOSE" 2 "HOLIDAY_PARTY_DANCE" 1 "HOLIDAY_PARTY_OPEN" 0 "HOLIDAY_PARTY_IDLE" ;
VAL_ 1012 LS_powerFrontDoorRequestRight 4 "HOLIDAY_PARTY_STOP" 3 "HOLIDAY_PARTY_CLOSE" 2 "HOLIDAY_PARTY_DANCE" 1 "HOLIDAY_PARTY_OPEN" 0 "HOLIDAY_PARTY_IDLE" ;
VAL_ 1012 LS_falconDoorRequestLeft 4 "HOLIDAY_PARTY_STOP" 3 "HOLIDAY_PARTY_CLOSE" 2 "HOLIDAY_PARTY_DANCE" 1 "HOLIDAY_PARTY_OPEN" 0 "HOLIDAY_PARTY_IDLE" ;
VAL_ 1012 LS_falconDoorRequestRight 4 "HOLIDAY_PARTY_STOP" 3 "HOLIDAY_PARTY_CLOSE" 2 "HOLIDAY_PARTY_DANCE" 1 "HOLIDAY_PARTY_OPEN" 0 "HOLIDAY_PARTY_IDLE" ;
VAL_ 1012 LS_chargePortRequest 3 "REQUEST_SNA" 2 "REQUEST_CLOSE" 1 "REQUEST_OPEN" 0 "REQUEST_NONE" ;
VAL_ 1012 LS_suspensionRequest 3 "SUSPENSION_REQUEST_SNA" 2 "SUSPENSION_REQUEST_LOWER" 1 "SUSPENSION_REQUEST_RAISE" 0 "SUSPENSION_REQUEST_NONE" ;
VAL_ 1429 OCS1P_alertID 156 "a156_seatbeltReminderUnavailable" 155 "a155_rbExit2Exited2" 154 "a154_rbExit2Exited1" 153 "a153_rbExit1Exited" 152 "a152_rbExit1Triggered" 151 "a151_rbEntryExited" 150 "a150_rbEntryTriggered" 148 "a148_classificationMismatch" 145 "a145_rebaselineTriggered" 144 "a144_mismatchCarRegion" 143 "a143_mismatchPassAirbag" 142 "a142_tempHumidityInvalid" 141 "a141_humidityInvalidCalib" 140 "a140_tempInvalidCalib" 139 "a139_seatbackSelfDutyHigh" 138 "a138_seatbackSelfDutyLow" 137 "a137_cushionSelfDutyHigh" 136 "a136_cushionSelfDutyLow" 135 "a135_tempNoCalib" 134 "a134_uninitializedCalib" 133 "a133_sandwichBadCalib" 132 "a132_seatbackSelfNoCalib" 131 "a131_cushionSelfNoCalib" 130 "a130_sandwichNoCalib" 129 "a129_seatbackSelfShort" 128 "a128_seatbackSelfLow" 127 "a127_seatbackSelfOpen" 126 "a126_cushionSelfShort" 125 "a125_cushionSelfLow" 124 "a124_cushionSelfOpen" 123 "a123_sandwichShort" 122 "a122_sandwichLow" 121 "a121_sandwichOpen" 15 "a015_NVMMAlert" 0 "ALERT_DO_NOT_USE_ZERO" ;
VAL_ 1429 OCS1P_alertState 1 "SET" 0 "CLEARED" ;
VAL_ 767 OCS1P_matrixIndex 2 "AlertMatrix2" 0 "AlertMatrix0" ;
VAL_ 766 OCS1P_infoIndex 20 "Mux20" 19 "Mux19" 18 "Mux18" 17 "Mux17" 14 "Mux14" 13 "Mux13" 11 "Mux11" 10 "Mux10" ;
VAL_ 766 OCS1P_infoBuildType 4 "INFO_MFG_BUILD" 3 "INFO_TRACEABLE_CI_BUILD" 2 "INFO_LOCAL_BUILD" 1 "INFO_PLATFORM_BUILD" 0 "INFO_UNKNOWN_BUILD" ;
VAL_ 771 OCS1P_occupantClassification 255 "OCCUPANT_CLASSIFICATION_SNA" 4 "OCCUPANT_CLASSIFICATION_INIT" 3 "OCCUPANT_CLASSIFICATION_OCCUPIED_ALLOW_LARGE" 2 "OCCUPANT_CLASSIFICATION_OCCUPIED_ALLOW_SMALL" 1 "OCCUPANT_CLASSIFICATION_OCCUPIED_INHIBIT" 0 "OCCUPANT_CLASSIFICATION_EMPTY" ;
VAL_ 771 OCS1P_occupantClassificationQF 1 "OCCUPANT_CLASSIFICATION_NOT_FAULTED" 0 "OCCUPANT_CLASSIFICATION_FAULTED" ;
VAL_ 771 OCS1P_occupiedState 3 "OCCUPIED_STATE_SNA" 1 "OCCUPIED_STATE_OCCUPIED" 0 "OCCUPIED_STATE_UNOCCUPIED" ;
VAL_ 771 OCS1P_triggerSnapshot 19 "REASON_LCB_TOO_HIGH" 18 "REASON_SWITCHED_TO_HCB" 17 "REASON_LARGE_REBASELINE" 16 "REASON_BORDERLINE_CLASSIFICATION" 15 "REASON_MISSED_EXIT_EVENT" 14 "REASON_MISSED_ENTRY_EVENT" 13 "REASON_EMPTY_CONFIDENT_EXITED" 12 "REASON_EMPTY_CONFIDENT_REBASELINED" 11 "REASON_EXIT_REBASELINED" 10 "REASON_EXIT_FAILED" 9 "REASON_EXIT_TRIGGERED" 8 "REASON_ENTRY_REBASELINED" 7 "REASON_ENTRY_FAILED" 6 "REASON_ENTRY_TRIGGERED" 5 "REASON_SENSOR_LOW_SHORT" 4 "REASON_SENSOR_OPEN" 3 "REASON_SANDWICH_LOW" 2 "REASON_REBASELINED" 1 "REASON_MISMATCH" 0 "REASON_NONE" ;
VAL_ 771 OCS1P_occupantClassificationRaw 7 "OCCUPANT_CLASSIFICATION_SNA" 4 "OCCUPANT_CLASSIFICATION_INIT" 3 "OCCUPANT_CLASSIFICATION_OCCUPIED_ALLOW_LARGE" 2 "OCCUPANT_CLASSIFICATION_OCCUPIED_ALLOW_SMALL" 1 "OCCUPANT_CLASSIFICATION_OCCUPIED_INHIBIT" 0 "OCCUPANT_CLASSIFICATION_EMPTY" ;
VAL_ 771 OCS1P_occupantClassificationSelf 7 "OCCUPANT_CLASSIFICATION_SNA" 4 "OCCUPANT_CLASSIFICATION_INIT" 3 "OCCUPANT_CLASSIFICATION_OCCUPIED_ALLOW_LARGE" 2 "OCCUPANT_CLASSIFICATION_OCCUPIED_ALLOW_SMALL" 1 "OCCUPANT_CLASSIFICATION_OCCUPIED_INHIBIT" 0 "OCCUPANT_CLASSIFICATION_EMPTY" ;
VAL_ 771 OCS1P_occupantClassificationRawC 7 "OCCUPANT_CLASSIFICATION_SNA" 4 "OCCUPANT_CLASSIFICATION_INIT" 3 "OCCUPANT_CLASSIFICATION_OCCUPIED_ALLOW_LARGE" 2 "OCCUPANT_CLASSIFICATION_OCCUPIED_ALLOW_SMALL" 1 "OCCUPANT_CLASSIFICATION_OCCUPIED_INHIBIT" 0 "OCCUPANT_CLASSIFICATION_EMPTY" ;
VAL_ 771 OCS1P_occupantClassificationCap 7 "OCCUPANT_CLASSIFICATION_SNA" 4 "OCCUPANT_CLASSIFICATION_INIT" 3 "OCCUPANT_CLASSIFICATION_OCCUPIED_ALLOW_LARGE" 2 "OCCUPANT_CLASSIFICATION_OCCUPIED_ALLOW_SMALL" 1 "OCCUPANT_CLASSIFICATION_OCCUPIED_INHIBIT" 0 "OCCUPANT_CLASSIFICATION_EMPTY" ;
VAL_ 771 OCS1P_classificationHoldState 3 "OCCUPANCY_HOLD_FAULT" 2 "OCCUPANCY_HOLD_EXTERNAL" 1 "OCCUPANCY_HOLD_BASIC" 0 "OCCUPANCY_HOLD_OFF" ;
VAL_ 771 OCS1P_classificationVariant 7 "CLASSIFICATION_VARIANT_UNKNOWN" 3 "CLASSIFICATION_VARIANT_SELF_SBR_RB" 2 "CLASSIFICATION_VARIANT_SELF_SBR" 1 "CLASSIFICATION_VARIANT_SELF_ONLY" 0 "CLASSIFICATION_VARIANT_ALL_SENSORS" ;
VAL_ 771 OCS1P_noSandwichType 3 "NO_SANDWICH_UNKNOWN" 2 "NO_SANDWICH_NA" 1 "NO_SANDWICH_EU" 0 "SANDWICH_INSTALLED" ;
VAL_ 771 OCS1P_sandwichBoundaryType 1 "SANDWICH_LRD" 0 "SANDWICH_DEFAULT" ;
VAL_ 771 OCS1P_sbrBoundaryType 1 "SBR_1669747_1763884" 0 "SBR_DEFAULT" ;
VAL_ 771 OCS1P_occupiedStateCap 3 "OCCUPIED_STATE_SNA" 1 "OCCUPIED_STATE_OCCUPIED" 0 "OCCUPIED_STATE_UNOCCUPIED" ;
VAL_ 1486 PARK_alertID 87 "a087_sensorMismatchError" 86 "a086_nvmFault" 85 "a085_watchdogReset" 84 "a084_sccmError" 83 "a083_vcFrontError" 82 "a082_rcmError" 81 "a081_espError" 80 "a080_epbError" 79 "a079_epasError" 78 "a078_diError" 77 "a077_dasError" 76 "a076_vcFrontMia" 75 "a075_rcmMia" 74 "a074_espMia" 73 "a073_epbMia" 72 "a072_epasMia" 71 "a071_diMia" 70 "a070_sccmMia" 69 "a069_dasMia" 68 "a068_hardwareWatchDog" 67 "a067_privateCANBusOff" 66 "a066_calibrationMissing" 65 "a065_crcFault" 64 "a064_ecuFault" 63 "a063_sensorVoltage" 62 "a062_ecuOverVoltage" 61 "a061_ecuUnderVoltage" 60 "a060_s12_crossTalk" 59 "a059_s12_blocked" 58 "a058_s12_linCommError" 57 "a057_s12_internalFail" 56 "a056_s12_overTemp" 55 "a055_s11_crossTalk" 54 "a054_s11_blocked" 53 "a053_s11_linCommError" 52 "a052_s11_internalFail" 51 "a051_s11_overTemp" 50 "a050_s10_crossTalk" 49 "a049_s10_blocked" 48 "a048_s10_linCommError" 47 "a047_s10_internalFail" 46 "a046_s10_overTemp" 45 "a045_s9_crossTalk" 44 "a044_s9_blocked" 43 "a043_s9_linCommError" 42 "a042_s9_internalFail" 41 "a041_s9_overTemp" 40 "a040_s8_crossTalk" 39 "a039_s8_blocked" 38 "a038_s8_linCommError" 37 "a037_s8_internalFail" 36 "a036_s8_overTemp" 35 "a035_s7_crossTalk" 34 "a034_s7_blocked" 33 "a033_s7_linCommError" 32 "a032_s7_internalFail" 31 "a031_s7_overTemp" 30 "a030_s6_crossTalk" 29 "a029_s6_blocked" 28 "a028_s6_linCommError" 27 "a027_s6_internalFail" 26 "a026_s6_overTemp" 25 "a025_s5_crossTalk" 24 "a024_s5_blocked" 23 "a023_s5_linCommError" 22 "a022_s5_internalFail" 21 "a021_s5_overTemp" 20 "a020_s4_crossTalk" 19 "a019_s4_blocked" 18 "a018_s4_linCommError" 17 "a017_s4_internalFail" 16 "a016_s4_overTemp" 15 "a015_s3_crossTalk" 14 "a014_s3_blocked" 13 "a013_s3_linCommError" 12 "a012_s3_internalFail" 11 "a011_s3_overTemp" 10 "a010_s2_crossTalk" 9 "a009_s2_blocked" 8 "a008_s2_linCommError" 7 "a007_s2_internalFail" 6 "a006_s2_overTemp" 5 "a005_s1_crossTalk" 4 "a004_s1_blocked" 3 "a003_s1_linCommError" 2 "a002_s1_internalFail" 1 "a001_s1_overTemp" 0 "ALERT_DO_NOT_USE_ZERO" ;
VAL_ 1486 PARK_alertState 1 "SET" 0 "CLEARED" ;
VAL_ 1486 PARK_sw077_errorType 5 "OVERRUN" 4 "INVALID_DATA" 3 "SEQUENCE" 2 "CHECKSUM" 1 "LENGTH" 0 "NONE" ;
VAL_ 1486 PARK_sw078_errorType 5 "OVERRUN" 4 "INVALID_DATA" 3 "SEQUENCE" 2 "CHECKSUM" 1 "LENGTH" 0 "NONE" ;
VAL_ 1486 PARK_sw079_errorType 5 "OVERRUN" 4 "INVALID_DATA" 3 "SEQUENCE" 2 "CHECKSUM" 1 "LENGTH" 0 "NONE" ;
VAL_ 1486 PARK_sw080_errorType 5 "OVERRUN" 4 "INVALID_DATA" 3 "SEQUENCE" 2 "CHECKSUM" 1 "LENGTH" 0 "NONE" ;
VAL_ 1486 PARK_sw081_errorType 5 "OVERRUN" 4 "INVALID_DATA" 3 "SEQUENCE" 2 "CHECKSUM" 1 "LENGTH" 0 "NONE" ;
VAL_ 1486 PARK_sw082_errorType 5 "OVERRUN" 4 "INVALID_DATA" 3 "SEQUENCE" 2 "CHECKSUM" 1 "LENGTH" 0 "NONE" ;
VAL_ 1486 PARK_sw083_errorType 5 "OVERRUN" 4 "INVALID_DATA" 3 "SEQUENCE" 2 "CHECKSUM" 1 "LENGTH" 0 "NONE" ;
VAL_ 1486 PARK_sw084_errorType 5 "OVERRUN" 4 "INVALID_DATA" 3 "SEQUENCE" 2 "CHECKSUM" 1 "LENGTH" 0 "NONE" ;
VAL_ 1486 PARK_sw087_s1_sensorType 3 "SNA" 2 "VALEO_HP" 1 "VALEO_HPFL" 0 "NONE" ;
VAL_ 1486 PARK_sw087_s2_sensorType 3 "SNA" 2 "VALEO_HP" 1 "VALEO_HPFL" 0 "NONE" ;
VAL_ 1486 PARK_sw087_s3_sensorType 3 "SNA" 2 "VALEO_HP" 1 "VALEO_HPFL" 0 "NONE" ;
VAL_ 1486 PARK_sw087_s4_sensorType 3 "SNA" 2 "VALEO_HP" 1 "VALEO_HPFL" 0 "NONE" ;
VAL_ 1486 PARK_sw087_s5_sensorType 3 "SNA" 2 "VALEO_HP" 1 "VALEO_HPFL" 0 "NONE" ;
VAL_ 1486 PARK_sw087_s6_sensorType 3 "SNA" 2 "VALEO_HP" 1 "VALEO_HPFL" 0 "NONE" ;
VAL_ 1486 PARK_sw087_s7_sensorType 3 "SNA" 2 "VALEO_HP" 1 "VALEO_HPFL" 0 "NONE" ;
VAL_ 1486 PARK_sw087_s8_sensorType 3 "SNA" 2 "VALEO_HP" 1 "VALEO_HPFL" 0 "NONE" ;
VAL_ 1486 PARK_sw087_s9_sensorType 3 "SNA" 2 "VALEO_HP" 1 "VALEO_HPFL" 0 "NONE" ;
VAL_ 1486 PARK_sw087_s10_sensorType 3 "SNA" 2 "VALEO_HP" 1 "VALEO_HPFL" 0 "NONE" ;
VAL_ 1486 PARK_sw087_s11_sensorType 3 "SNA" 2 "VALEO_HP" 1 "VALEO_HPFL" 0 "NONE" ;
VAL_ 1486 PARK_sw087_s12_sensorType 3 "SNA" 2 "VALEO_HP" 1 "VALEO_HPFL" 0 "NONE" ;
VAL_ 806 PARK_infoIndex 255 "END" 31 "SUBCOMPONENT_GITHASH" 30 "PACKAGE_SN_8_14" 29 "PACKAGE_SN_1_7" 27 "PACKAGE_PN_15_20" 26 "PACKAGE_PN_8_14" 25 "PACKAGE_PN_1_7" 23 "SUBCOMPONENT2" 22 "VARIANTCRC" 20 "UDS_PROTOCOL_BOOTCRC" 19 "VERSION_DEPRECATED" 18 "BOOTLOADER_GITHASH" 17 "APP_GITHASH" 16 "SUBCOMPONENT" 15 "BOOTLOADER_CRC" 14 "BOOTLOADER_SVN" 13 "APP_CRC" 11 "PCBAID_ASSYID_USAGEID" 10 "BUILD_HWID_COMPONENTID" 9 "DEPRECATED_9" 8 "DEPRECATED_8" 7 "DEPRECATED_7" 6 "DEPRECATED_6" 5 "DEPRECATED_5" 4 "DEPRECATED_4" 3 "DEPRECATED_3" 2 "DEPRECATED_2" 1 "DEPRECATED_1" 0 "DEPRECATED_0" ;
VAL_ 806 PARK_infoBuildType 4 "INFO_MFG_BUILD" 3 "INFO_TRACEABLE_CI_BUILD" 2 "INFO_LOCAL_BUILD" 1 "INFO_PLATFORM_BUILD" 0 "INFO_UNKNOWN_BUILD" ;
VAL_ 846 PARK_frontLeftMiddleRawDistData 255 "SNA" ;
VAL_ 846 PARK_frontMiddleRawDistData 255 "SNA" ;
VAL_ 846 PARK_frontRightMiddleRawDistData 255 "SNA" ;
VAL_ 862 PARK_rearLeftMiddleRawDistData 255 "SNA" ;
VAL_ 862 PARK_rearMiddleRawDistData 255 "SNA" ;
VAL_ 862 PARK_rearRightMiddleRawDistData 255 "SNA" ;
